VERSION ""

NS_ :

BS_:

BU_: ESP_EV

BO_ 3221225472 VECTOR__INDEPENDENT_SIG_MSG: 0 Vector__XXX
 SG_ NoGearshiftReqStatus : 0|2@0+ (1,0) [0|3] "" Vector__XXX
 SG_ CruiseCntShutESPStatus : 0|2@0+ (1,0) [0|3] "" Vector__XXX
 SG_ CruiseCntShutESP : 0|1@0+ (1,0) [0|1] "" Vector__XXX
 SG_ PowerModeStateStatus : 0|2@0+ (1,0) [0|3] "" Vector__XXX

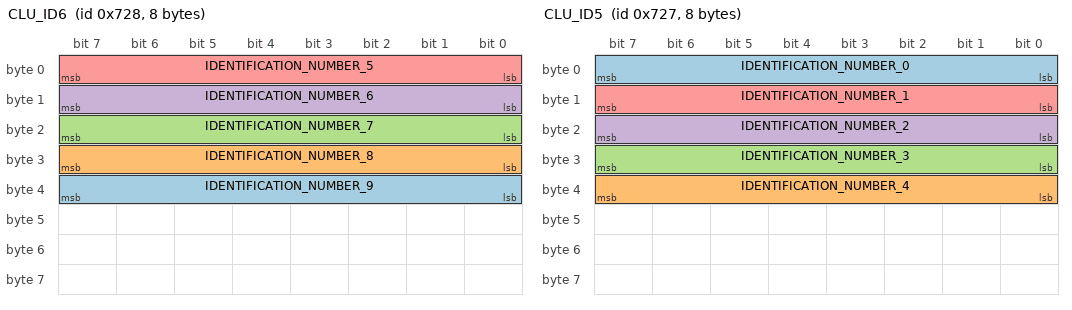
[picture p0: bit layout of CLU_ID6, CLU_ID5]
BO_ 1832 CLU_ID6: 8 Vector__XXX
 SG_ IDENTIFICATION_NUMBER_9 : 32|8@1+ (1,0) [0|255] ""  ESP_EV
 SG_ IDENTIFICATION_NUMBER_8 : 24|8@1+ (1,0) [0|255] ""  ESP_EV
 SG_ IDENTIFICATION_NUMBER_7 : 16|8@1+ (1,0) [0|255] ""  ESP_EV
 SG_ IDENTIFICATION_NUMBER_6 : 8|8@1+ (1,0) [0|255] ""  ESP_EV
 SG_ IDENTIFICATION_NUMBER_5 : 0|8@1+ (1,0) [0|255] ""  ESP_EV

BO_ 1831 CLU_ID5: 8 Vector__XXX
 SG_ IDENTIFICATION_NUMBER_0 : 0|8@1+ (1,0) [0|255] ""  ESP_EV
 SG_ IDENTIFICATION_NUMBER_4 : 32|8@1+ (1,0) [0|255] ""  ESP_EV
 SG_ IDENTIFICATION_NUMBER_3 : 24|8@1+ (1,0) [0|255] ""  ESP_EV
 SG_ IDENTIFICATION_NUMBER_2 : 16|8@1+ (1,0) [0|255] ""  ESP_EV
 SG_ IDENTIFICATION_NUMBER_1 : 8|8@1+ (1,0) [0|255] ""  ESP_EV

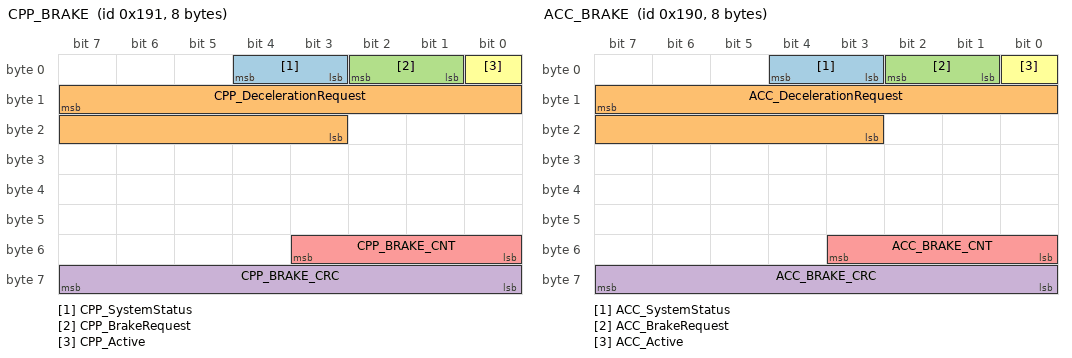
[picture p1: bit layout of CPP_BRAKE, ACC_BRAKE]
BO_ 401 CPP_BRAKE: 8 Vector__XXX
 SG_ CPP_SystemStatus : 4|2@0+ (1,0) [0|3] ""  ESP_EV
 SG_ CPP_DecelerationRequest : 15|13@0+ (0.001,-5) [-5|3.191] "g"  ESP_EV
 SG_ CPP_BrakeRequest : 2|2@0+ (1,0) [0|3] ""  ESP_EV
 SG_ CPP_BRAKE_CRC : 63|8@0+ (1,0) [0|255] ""  ESP_EV
 SG_ CPP_BRAKE_CNT : 51|4@0+ (1,0) [0|15] ""  ESP_EV
 SG_ CPP_Active : 0|1@0+ (1,0) [0|1] ""  ESP_EV

BO_ 400 ACC_BRAKE: 8 Vector__XXX
 SG_ ACC_SystemStatus : 4|2@0+ (1,0) [0|3] ""  ESP_EV
 SG_ ACC_DecelerationRequest : 15|13@0+ (0.001,-5) [-5|3.191] "g"  ESP_EV
 SG_ ACC_BrakeRequest : 2|2@0+ (1,0) [0|3] ""  ESP_EV
 SG_ ACC_BRAKE_CRC : 63|8@0+ (1,0) [0|255] ""  ESP_EV
 SG_ ACC_BRAKE_CNT : 51|4@0+ (1,0) [0|15] ""  ESP_EV
 SG_ ACC_Active : 0|1@0+ (1,0) [0|1] ""  ESP_EV

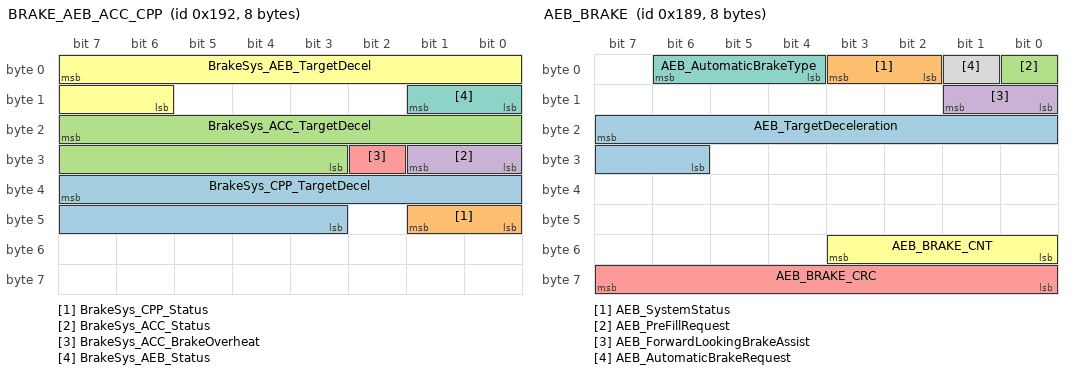
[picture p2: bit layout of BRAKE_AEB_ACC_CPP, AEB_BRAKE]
BO_ 402 BRAKE_AEB_ACC_CPP: 8 ESP_EV
 SG_ BrakeSys_CPP_TargetDecel : 39|13@0+ (0.001,-5) [-5|3.191] "g" Vector__XXX
 SG_ BrakeSys_CPP_Status : 41|2@0+ (1,0) [0|0] "" Vector__XXX
 SG_ BrakeSys_ACC_TargetDecel : 23|13@0+ (0.001,-5) [-5|3.191] "g" Vector__XXX
 SG_ BrakeSys_ACC_Status : 25|2@0+ (1,0) [0|3] "" Vector__XXX
 SG_ BrakeSys_ACC_BrakeOverheat : 26|1@0+ (1,0) [0|1] "" Vector__XXX
 SG_ BrakeSys_AEB_TargetDecel : 7|10@0+ (0.01,-5) [-5|5.23] "g" Vector__XXX
 SG_ BrakeSys_AEB_Status : 9|2@0+ (1,0) [0|3] "" Vector__XXX

BO_ 393 AEB_BRAKE: 8 Vector__XXX
 SG_ AEB_TargetDeceleration : 23|10@0+ (0.01,-5) [-5|5.23] "g"  ESP_EV
 SG_ AEB_SystemStatus : 3|2@0+ (1,0) [0|3] ""  ESP_EV
 SG_ AEB_PreFillRequest : 0|1@0+ (1,0) [0|1] ""  ESP_EV
 SG_ AEB_ForwardLookingBrakeAssist : 9|2@0+ (1,0) [0|2] ""  ESP_EV
 SG_ AEB_BRAKE_CRC : 63|8@0+ (1,0) [0|255] ""  ESP_EV
 SG_ AEB_BRAKE_CNT : 51|4@0+ (1,0) [0|15] ""  ESP_EV
 SG_ AEB_AutomaticBrakeType : 6|3@0+ (1,0) [0|5] ""  ESP_EV
 SG_ AEB_AutomaticBrakeRequest : 1|1@0+ (1,0) [0|1] ""  ESP_EV

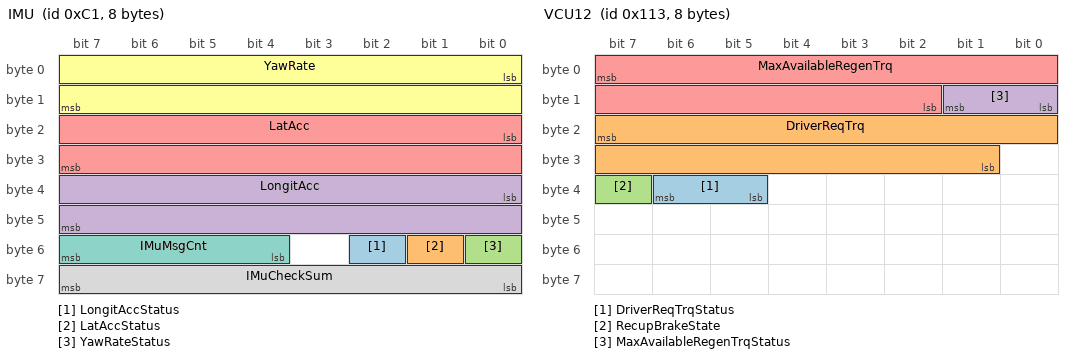
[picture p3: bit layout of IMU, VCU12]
BO_ 193 IMU: 8 Vector__XXX
 SG_ LongitAccStatus : 50|1@1+ (1,0) [0|1] ""  ESP_EV
 SG_ LatAccStatus : 49|1@1+ (1,0) [0|1] ""  ESP_EV
 SG_ YawRateStatus : 48|1@1+ (1,0) [0|1] ""  ESP_EV
 SG_ LongitAcc : 32|16@1+ (0.002,-65.532) [-65.532|65.538] "m/s2"  ESP_EV
 SG_ LatAcc : 16|16@1+ (0.002,-65.532) [-65.532|65.538] "m/s2"  ESP_EV
 SG_ YawRate : 0|16@1+ (0.005,-163.83) [-163.83|163.845] "°/s"  ESP_EV
 SG_ IMuMsgCnt : 52|4@1+ (1,0) [0|15] ""  ESP_EV
 SG_ IMuCheckSum : 56|8@1+ (1,0) [0|255] ""  ESP_EV

BO_ 2015 TesterFunctionalReq: 8 Vector__XXX
 SG_ TesterFunctionalRequestESP : 7|64@0+ (1,0) [0|0] ""  ESP_EV

BO_ 275 VCU12: 8 Vector__XXX
 SG_ DriverReqTrqStatus : 38|2@0+ (1,0) [0|3] ""  ESP_EV
 SG_ DriverReqTrq : 23|15@0+ (0.2,-3276.8) [-3276.8|3276.6] ""  ESP_EV
 SG_ RecupBrakeState : 39|1@0+ (1,0) [0|1] ""  ESP_EV
 SG_ MaxAvailableRegenTrqStatus : 9|2@0+ (1,0) [0|3] ""  ESP_EV
 SG_ MaxAvailableRegenTrq : 7|14@0+ (0.2,0) [0|3276.6] ""  ESP_EV

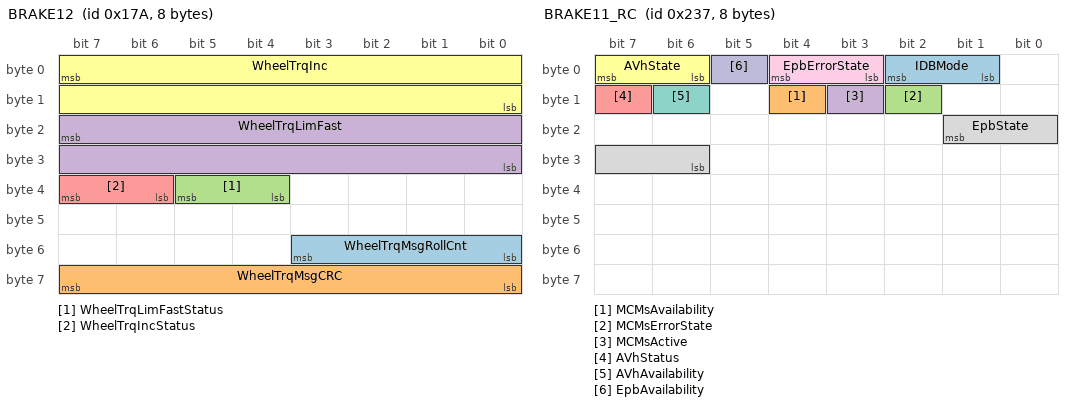
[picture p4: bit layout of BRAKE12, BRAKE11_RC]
BO_ 378 BRAKE12: 8 ESP_EV
 SG_ WheelTrqMsgRollCnt : 51|4@0+ (1,0) [0|15] "" Vector__XXX
 SG_ WheelTrqMsgCRC : 63|8@0+ (1,0) [0|255] "" Vector__XXX
 SG_ WheelTrqLimFastStatus : 37|2@0+ (1,0) [0|3] "" Vector__XXX
 SG_ WheelTrqLimFast : 23|16@0+ (0.1,-3276.8) [-3276.8|3276.7] "Nm" Vector__XXX
 SG_ WheelTrqIncStatus : 39|2@0+ (1,0) [0|3] "" Vector__XXX
 SG_ WheelTrqInc : 7|16@0+ (0.1,-3276.8) [-3276.8|3276.7] "Nm" Vector__XXX

BO_ 567 BRAKE11_RC: 8 ESP_EV
 SG_ IDBMode : 2|2@0+ (1,0) [0|3] "" Vector__XXX
 SG_ MCMsAvailability : 12|1@0+ (1,0) [0|1] "" Vector__XXX
 SG_ MCMsErrorState : 10|1@0+ (1,0) [0|1] "" Vector__XXX
 SG_ MCMsActive : 11|1@0+ (1,0) [0|1] "" Vector__XXX
 SG_ AVhStatus : 15|1@0+ (1,0) [0|1] "" Vector__XXX
 SG_ AVhState : 7|2@0+ (1,0) [0|3] "" Vector__XXX
 SG_ AVhAvailability : 14|1@0+ (1,0) [0|1] "" Vector__XXX
 SG_ EpbState : 17|4@0+ (1,0) [0|15] "" Vector__XXX
 SG_ EpbErrorState : 4|2@0+ (1,0) [0|3] "" Vector__XXX
 SG_ EpbAvailability : 5|1@0+ (1,0) [0|1] "" Vector__XXX

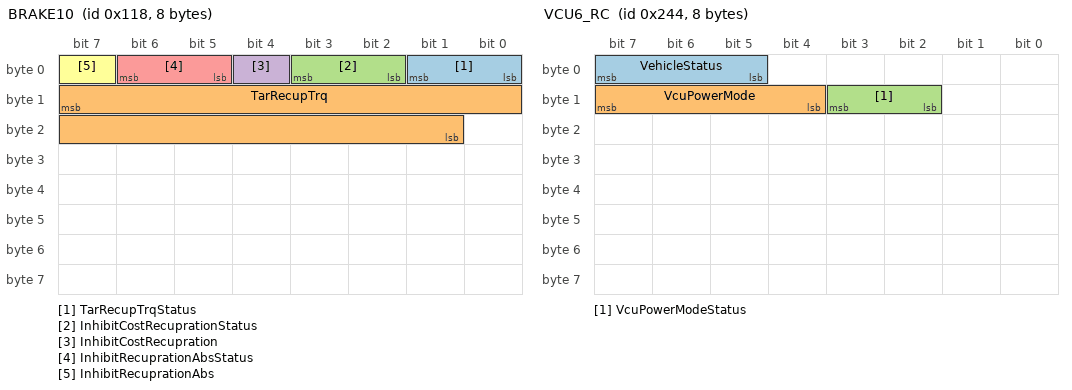
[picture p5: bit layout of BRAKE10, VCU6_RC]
BO_ 280 BRAKE10: 8 ESP_EV
 SG_ TarRecupTrqStatus : 1|2@0+ (1,0) [0|3] "" Vector__XXX
 SG_ TarRecupTrq : 15|15@0+ (0.1,0) [0|3276.7] "" Vector__XXX
 SG_ InhibitCostRecuprationStatus : 3|2@0+ (1,0) [0|3] "" Vector__XXX
 SG_ InhibitCostRecupration : 4|1@0+ (1,0) [0|1] "" Vector__XXX
 SG_ InhibitRecuprationAbsStatus : 6|2@0+ (1,0) [0|3] "" Vector__XXX
 SG_ InhibitRecuprationAbs : 7|1@0+ (1,0) [0|1] "" Vector__XXX

BO_ 1289 NM_ESP_TX: 8 ESP_EV
 SG_ PreviousState_ESP : 19|3@0+ (1,0) [0|7] "" Vector__XXX
 SG_ Reserved63 : 20|1@0+ (1,0) [0|1] "" Vector__XXX
 SG_ Reserved62 : 21|1@0+ (1,0) [0|1] "" Vector__XXX
 SG_ Reserved61 : 22|1@0+ (1,0) [0|1] "" Vector__XXX
 SG_ Reserved60 : 23|1@0+ (1,0) [0|1] "" Vector__XXX
 SG_ Reserved59 : 9|1@0+ (1,0) [0|1] "" Vector__XXX
 SG_ Reserved58 : 10|1@0+ (1,0) [0|1] "" Vector__XXX
 SG_ Reserved57 : 13|1@0+ (1,0) [0|1] "" Vector__XXX
 SG_ Reserved56 : 15|1@0+ (1,0) [0|1] "" Vector__XXX
 SG_ RepeatMessageReq_ESP : 8|1@0+ (1,0) [0|1] "" Vector__XXX
 SG_ PartialNetworkInformation_ESP : 14|1@0+ (1,0) [0|1] "" Vector__XXX
 SG_ NMCoOrdSlpReady_ESP : 11|1@0+ (1,0) [0|1] "" Vector__XXX
 SG_ ESP_NMPDU_USER_DATA_D5 : 63|8@0+ (1,0) [0|255] "" Vector__XXX
 SG_ ESP_NMPDU_USER_DATA_D4 : 55|8@0+ (1,0) [0|255] "" Vector__XXX
 SG_ ESP_NMPDU_USER_DATA_D3 : 47|8@0+ (1,0) [0|255] "" Vector__XXX
 SG_ ESP_NMPDU_USER_DATA_D2 : 39|8@0+ (1,0) [0|255] "" Vector__XXX
 SG_ ESP_NMPDU_USER_DATA_D1 : 31|8@0+ (1,0) [0|255] "" Vector__XXX
 SG_ ESP_NMPDU_SRC_ECU_ID : 7|8@0+ (1,0) [0|255] "" Vector__XXX
 SG_ CurrentState_ESP : 16|1@0+ (1,0) [0|1] "" Vector__XXX
 SG_ ActiveWakeUp_ESP : 12|1@0+ (1,0) [0|1] "" Vector__XXX

BO_ 1163 BRAKE_SF1: 8 Vector__XXX
 SG_ VCUMToFailureStatus : 33|2@0+ (1,0) [0|3] "" Vector__XXX
 SG_ VCUInvalidFailureStatus : 35|2@0+ (1,0) [0|3] "" Vector__XXX

BO_ 580 VCU6_RC: 8 Vector__XXX
 SG_ VehicleStatus : 7|3@0+ (1,0) [0|7] ""  ESP_EV
 SG_ VcuPowerMode : 15|4@0+ (1,0) [0|15] ""  ESP_EV
 SG_ VcuPowerModeStatus : 11|2@0+ (1,0) [0|3] ""  ESP_EV

BO_ 579 VCU5: 8 Vector__XXX
 SG_ GearForDisplayVcu : 7|4@0+ (1,0) [0|15] ""  ESP_EV
 SG_ GearForDisplayVcuStatus : 3|2@0+ (1,0) [0|3] ""  ESP_EV

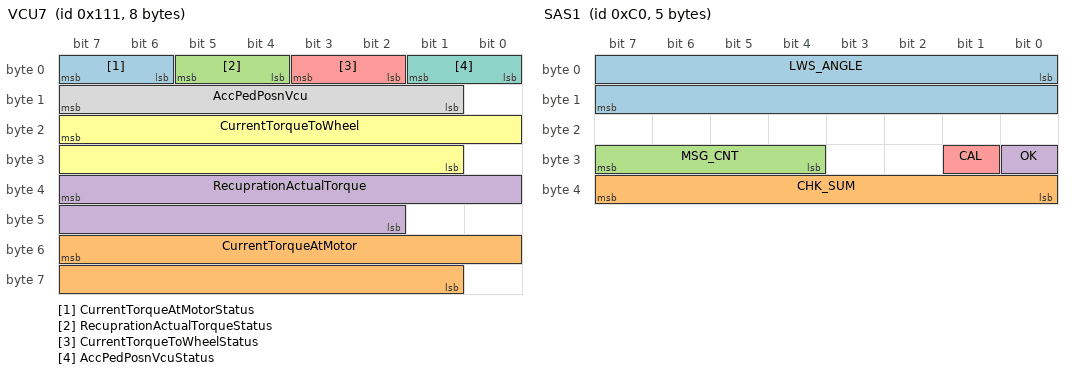
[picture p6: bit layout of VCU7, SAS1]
BO_ 273 VCU7: 8 Vector__XXX
 SG_ CurrentTorqueAtMotorStatus : 7|2@0+ (1,0) [0|3] ""  ESP_EV
 SG_ CurrentTorqueAtMotor : 55|15@0+ (0.2,-3276.8) [-3276.8|3276.6] ""  ESP_EV
 SG_ RecuprationActualTorqueStatus : 5|2@0+ (1,0) [0|3] ""  ESP_EV
 SG_ RecuprationActualTorque : 39|14@0+ (0.2,0) [0|3276.6] ""  ESP_EV
 SG_ CurrentTorqueToWheelStatus : 3|2@0+ (1,0) [0|3] ""  ESP_EV
 SG_ CurrentTorqueToWheel : 23|15@0+ (0.2,-3276.8) [-3276.8|3276.6] ""  ESP_EV
 SG_ AccPedPosnVcuStatus : 1|2@0+ (1,0) [0|3] ""  ESP_EV
 SG_ AccPedPosnVcu : 15|7@0+ (1,0) [0|100] "%"  ESP_EV

BO_ 192 SAS1: 5 Vector__XXX
 SG_ LWS_ANGLE : 0|16@1- (0.1,0) [-780|779.9] "degree"  ESP_EV
 SG_ CHK_SUM : 32|8@1+ (1,0) [0|255] ""  ESP_EV
 SG_ MSG_CNT : 28|4@1+ (1,0) [0|15] ""  ESP_EV
 SG_ OK : 24|1@1+ (1,0) [0|1] ""  ESP_EV
 SG_ CAL : 25|1@1+ (1,0) [0|1] ""  ESP_EV

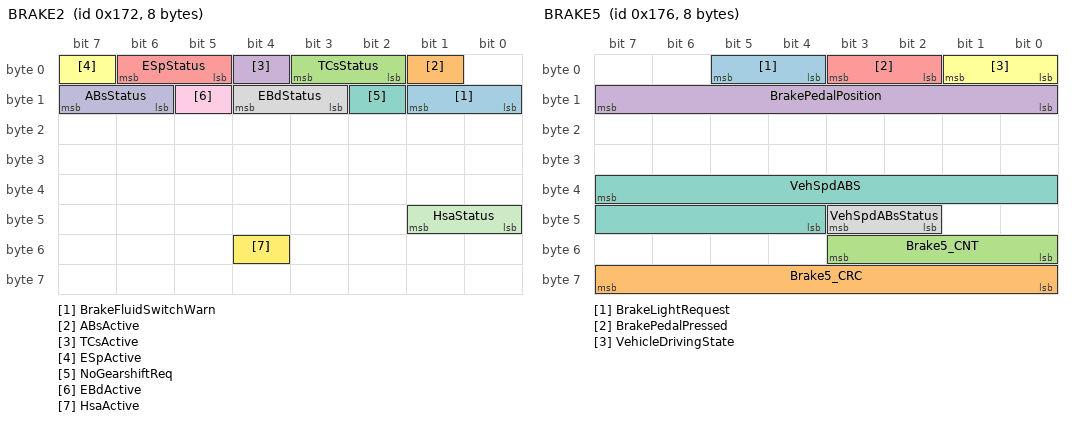
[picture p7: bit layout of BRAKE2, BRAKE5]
BO_ 370 BRAKE2: 8 ESP_EV
 SG_ BrakeFluidSwitchWarn : 9|2@0+ (1,0) [0|0] "" Vector__XXX
 SG_ ABsActive : 1|1@0+ (1,0) [0|1] "" Vector__XXX
 SG_ TCsStatus : 3|2@0+ (1,0) [0|3] "" Vector__XXX
 SG_ TCsActive : 4|1@0+ (1,0) [0|1] "" Vector__XXX
 SG_ ESpStatus : 6|2@0+ (1,0) [0|3] "" Vector__XXX
 SG_ ESpActive : 7|1@0+ (1,0) [0|1] "" Vector__XXX
 SG_ NoGearshiftReq : 10|1@0+ (1,0) [0|1] "" Vector__XXX
 SG_ EBdStatus : 12|2@0+ (1,0) [0|3] "" Vector__XXX
 SG_ EBdActive : 13|1@0+ (1,0) [0|1] "" Vector__XXX
 SG_ ABsStatus : 15|2@0+ (1,0) [0|3] "" Vector__XXX
 SG_ HsaStatus : 41|2@0+ (1,0) [0|3] "" Vector__XXX
 SG_ HsaActive : 52|1@0+ (1,0) [0|1] "" Vector__XXX

BO_ 374 BRAKE5: 8 ESP_EV
 SG_ BrakeLightRequest : 5|2@0+ (1,0) [0|3] "" Vector__XXX
 SG_ Brake5_CRC : 63|8@0+ (1,0) [0|255] "" Vector__XXX
 SG_ Brake5_CNT : 51|4@0+ (1,0) [0|15] "" Vector__XXX
 SG_ BrakePedalPosition : 15|8@0+ (0.4,0) [0|100] "%" Vector__XXX
 SG_ BrakePedalPressed : 3|2@0+ (1,0) [0|3] "" Vector__XXX
 SG_ VehicleDrivingState : 1|2@0+ (1,0) [0|3] "" Vector__XXX
 SG_ VehSpdABS : 39|12@0+ (0.03125,0) [0|127.96875] "m/s" Vector__XXX
 SG_ VehSpdABsStatus : 43|2@0+ (1,0) [0|3] "" Vector__XXX

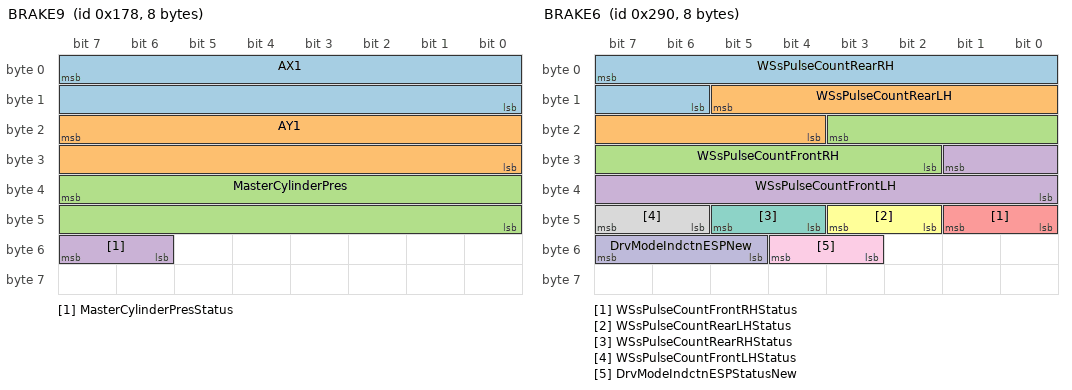
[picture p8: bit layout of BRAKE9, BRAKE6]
BO_ 376 BRAKE9: 8 ESP_EV
 SG_ AX1 : 7|16@0+ (0.0001,-3.2768) [-3.2768|3.2767] "g" Vector__XXX
 SG_ AY1 : 23|16@0+ (0.0001,-3.2768) [-3.2768|3.2767] "g" Vector__XXX
 SG_ MasterCylinderPres : 39|16@0+ (0.05,-40) [-40|400] "bar" Vector__XXX
 SG_ MasterCylinderPresStatus : 55|2@0+ (1,0) [0|3] "" Vector__XXX

BO_ 656 BRAKE6: 8 ESP_EV
 SG_ WSsPulseCountRearRH : 7|10@0+ (1,0) [0|1023] "Pulse" Vector__XXX
 SG_ WSsPulseCountRearLH : 13|10@0+ (1,0) [0|1023] "Pulse" Vector__XXX
 SG_ WSsPulseCountFrontRH : 19|10@0+ (1,0) [0|1023] "Pulse" Vector__XXX
 SG_ WSsPulseCountFrontLH : 25|10@0+ (1,0) [0|1023] "Pulse" Vector__XXX
 SG_ WSsPulseCountFrontRHStatus : 41|2@0+ (1,0) [0|3] "" Vector__XXX
 SG_ WSsPulseCountRearLHStatus : 43|2@0+ (1,0) [0|3] "" Vector__XXX
 SG_ WSsPulseCountRearRHStatus : 45|2@0+ (1,0) [0|3] "" Vector__XXX
 SG_ WSsPulseCountFrontLHStatus : 47|2@0+ (1,0) [0|3] "" Vector__XXX
 SG_ DrvModeIndctnESPStatusNew : 52|2@0+ (1,0) [0|3] "" Vector__XXX
 SG_ DrvModeIndctnESPNew : 55|3@0+ (1,0) [0|7] "" Vector__XXX

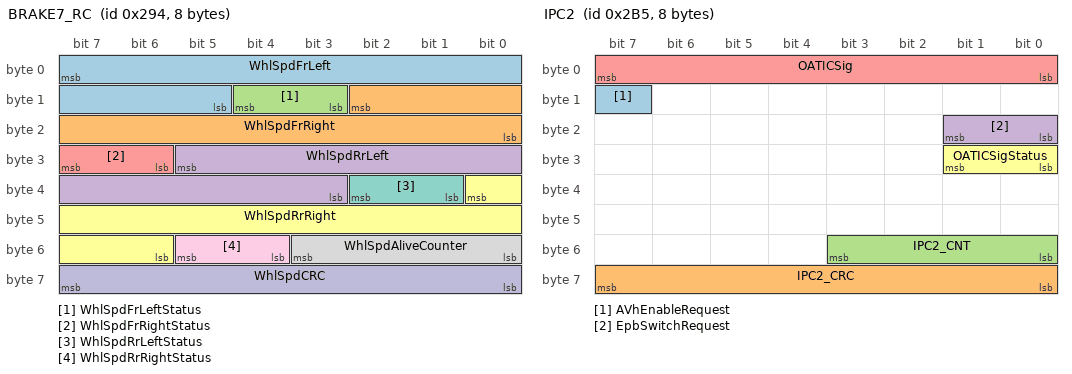
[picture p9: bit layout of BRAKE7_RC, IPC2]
BO_ 660 BRAKE7_RC: 8 ESP_EV
 SG_ WhlSpdFrLeft : 7|11@0+ (2,0) [0|4094] "rpm" Vector__XXX
 SG_ WhlSpdFrRight : 10|11@0+ (2,0) [0|4094] "rpm" Vector__XXX
 SG_ WhlSpdFrLeftStatus : 12|2@0+ (1,0) [0|3] "" Vector__XXX
 SG_ WhlSpdRrLeft : 29|11@0+ (2,0) [0|4094] "rpm" Vector__XXX
 SG_ WhlSpdFrRightStatus : 31|2@0+ (1,0) [0|3] "" Vector__XXX
 SG_ WhlSpdRrRight : 32|11@0+ (2,0) [0|4094] "rpm" Vector__XXX
 SG_ WhlSpdRrLeftStatus : 34|2@0+ (1,0) [0|3] "" Vector__XXX
 SG_ WhlSpdAliveCounter : 51|4@0+ (1,0) [0|15] "" Vector__XXX
 SG_ WhlSpdRrRightStatus : 53|2@0+ (1,0) [0|3] "" Vector__XXX
 SG_ WhlSpdCRC : 63|8@0+ (1,0) [0|255] "" Vector__XXX

BO_ 693 IPC2: 8 Vector__XXX
 SG_ AVhEnableRequest : 15|1@0+ (1,0) [0|1] ""  ESP_EV
 SG_ IPC2_CRC : 63|8@0+ (1,0) [0|255] ""  ESP_EV
 SG_ IPC2_CNT : 51|4@0+ (1,0) [0|15] ""  ESP_EV
 SG_ EpbSwitchRequest : 17|2@0+ (1,0) [0|3] ""  ESP_EV
 SG_ OATICSig : 7|8@0+ (0.5,-40) [-40|85] "degC"  ESP_EV
 SG_ OATICSigStatus : 25|2@0+ (1,0) [0|3] ""  ESP_EV

BO_ 722 BCM_HUICTrailer_RC1: 8 Vector__XXX
 SG_ PowerModeState : 5|4@0+ (1,0) [0|15] ""  ESP_EV

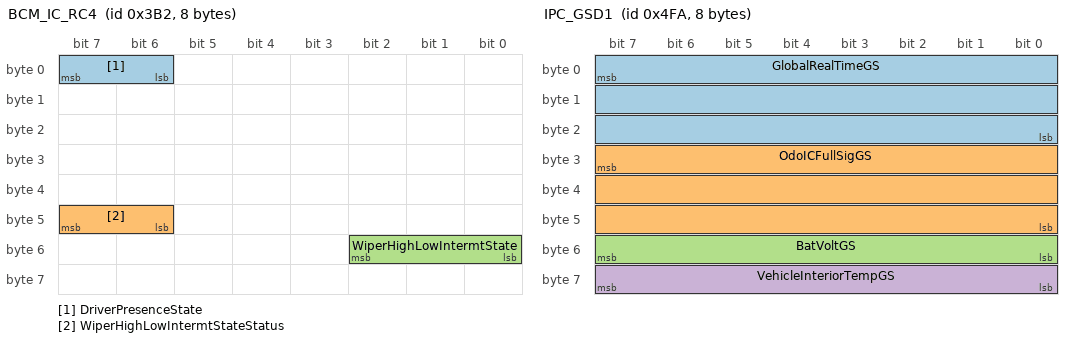
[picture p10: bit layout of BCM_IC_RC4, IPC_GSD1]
BO_ 946 BCM_IC_RC4: 8 Vector__XXX
 SG_ DriverPresenceState : 7|2@0+ (1,0) [0|3] ""  ESP_EV
 SG_ WiperHighLowIntermtStateStatus : 47|2@0+ (1,0) [0|3] ""  ESP_EV
 SG_ WiperHighLowIntermtState : 50|3@0+ (1,0) [0|7] ""  ESP_EV

BO_ 1274 IPC_GSD1: 8 Vector__XXX
 SG_ GlobalRealTimeGS : 7|24@0+ (1,0) [0|16777214] "min"  ESP_EV
 SG_ OdoICFullSigGS : 31|24@0+ (1,0) [0|16777214] "km"  ESP_EV
 SG_ BatVoltGS : 55|8@0+ (0.1,0) [0|25.4] "V"  ESP_EV
 SG_ VehicleInteriorTempGS : 63|8@0+ (1,-40) [-40|214] "Deg"  ESP_EV

BO_ 1280 NM_ESP_RX: 8 Vector__XXX
 SG_ BCM_NMPDU_SRC_ECU_ID : 7|8@0+ (1,0) [0|255] ""  ESP_EV
 SG_ RepeatMessageReq_BCM : 8|1@0+ (1,0) [0|1] ""  ESP_EV
 SG_ Reserved0 : 9|1@0+ (1,0) [0|1] ""  ESP_EV
 SG_ Reserved1 : 10|1@0+ (1,0) [0|1] ""  ESP_EV
 SG_ NMCoOrdSlpReady_BCM : 11|1@0+ (1,0) [0|1] ""  ESP_EV
 SG_ ActiveWakeUp_BCM : 12|1@0+ (1,0) [0|1] ""  ESP_EV
 SG_ Reserved2 : 13|1@0+ (1,0) [0|1] ""  ESP_EV
 SG_ PartialNetworkInformation_BCM : 14|1@0+ (1,0) [0|1] ""  ESP_EV
 SG_ Reserved3 : 15|1@0+ (1,0) [0|1] ""  ESP_EV
 SG_ CurrentState_BCM : 16|1@0+ (1,0) [0|1] ""  ESP_EV
 SG_ PreviousState_BCM : 19|3@0+ (1,0) [0|7] ""  ESP_EV
 SG_ Reserved4 : 20|1@0+ (1,0) [0|1] ""  ESP_EV
 SG_ Reserved5 : 21|1@0+ (1,0) [0|1] ""  ESP_EV
 SG_ Reserved6 : 22|1@0+ (1,0) [0|1] ""  ESP_EV
 SG_ Reserved7 : 23|1@0+ (1,0) [0|1] ""  ESP_EV
 SG_ BCM_NMPDU_USER_DATA_D1 : 31|8@0+ (1,0) [0|255] ""  ESP_EV
 SG_ BCM_NMPDU_USER_DATA_D2 : 39|8@0+ (1,0) [0|255] ""  ESP_EV
 SG_ BCM_NMPDU_USER_DATA_D3 : 47|8@0+ (1,0) [0|255] ""  ESP_EV
 SG_ BCM_NMPDU_USER_DATA_D4 : 55|8@0+ (1,0) [0|255] ""  ESP_EV
 SG_ BCM_NMPDU_USER_DATA_D5 : 63|8@0+ (1,0) [0|255] ""  ESP_EV

BO_ 1872 TesterPhysicalReq: 8 Vector__XXX
 SG_ TesterPhysicalRequestESP : 7|64@0+ (1,0) [0|0] ""  ESP_EV

BO_ 1880 TesterPhysicalResp: 8 ESP_EV
 SG_ TesterPhysicalResponseESP : 7|64@0+ (1,0) [0|0] "" Vector__XXX

CM_ "Arrival_P4: P_CAN; Epsilon_v2.00";
CM_ BU_ ESP_EV "ABS ECU EV ";
CM_ BO_ 3221225472 "This is a message for not used signals, created by Vector CANdb++ DBC OLE DB Provider.";
CM_ SG_ 3221225472 NoGearshiftReqStatus "status information of NoGearshiftReq
";
CM_ SG_ 3221225472 CruiseCntShutESPStatus "ESP requested to EMS ECU for shut sown the cruise control function
";
CM_ SG_ 3221225472 CruiseCntShutESP "ESP requested to EMS ECU for shut sown the cruise control function
";
CM_ SG_ 3221225472 PowerModeStateStatus "This signal is used to verify the correctness of Power Mode Status";
CM_ BO_ 1832 "IMU identification information";
CM_ BO_ 1831 "IMU identification information";
CM_ BO_ 401 "CPP brake request message";
CM_ SG_ 401 CPP_SystemStatus "CPP system status of CPP module";
CM_ SG_ 401 CPP_DecelerationRequest "CPP requested deceleration";
CM_ SG_ 401 CPP_BrakeRequest "CPP braking reqeust";
CM_ SG_ 401 CPP_BRAKE_CRC "E2E checksum";
CM_ SG_ 401 CPP_BRAKE_CNT "E2E Counter";
CM_ SG_ 401 CPP_Active "CPP active state";
CM_ SG_ 400 ACC_SystemStatus "ACC system status of ACC module";
CM_ SG_ 400 ACC_DecelerationRequest "ACC requested deceleration";
CM_ SG_ 400 ACC_BrakeRequest "ACC braking reqeust";
CM_ SG_ 400 ACC_BRAKE_CRC "E2E checksum";
CM_ SG_ 400 ACC_BRAKE_CNT "E2E Counter";
CM_ SG_ 400 ACC_Active "ACC active state";
CM_ SG_ 402 BrakeSys_CPP_TargetDecel "CPP applied target decel";
CM_ SG_ 402 BrakeSys_CPP_Status "CPP braking status";
CM_ SG_ 402 BrakeSys_ACC_TargetDecel "Brake System Automatic Braking Target Decel. Rate";
CM_ SG_ 402 BrakeSys_ACC_Status "ACC Brake System Automatic Braking Status";
CM_ SG_ 402 BrakeSys_ACC_BrakeOverheat "Brake System notification overheated brakes";
CM_ SG_ 402 BrakeSys_AEB_TargetDecel "Brake System Automatic Braking Target Decel. Rate";
CM_ SG_ 402 BrakeSys_AEB_Status "Brake System Automatic Braking Status";
CM_ SG_ 393 AEB_TargetDeceleration "AEB traget deceleration";
CM_ SG_ 393 AEB_SystemStatus "AEB system status of AEB module";
CM_ SG_ 393 AEB_PreFillRequest "Brake Prefill Request";
CM_ SG_ 393 AEB_ForwardLookingBrakeAssist "Forward-looking Brake Assist ";
CM_ SG_ 393 AEB_BRAKE_CRC "E2E Checksum";
CM_ SG_ 393 AEB_BRAKE_CNT "E2E counter";
CM_ SG_ 393 AEB_AutomaticBrakeType "Collision Preparation System Automatic Braking Type";
CM_ SG_ 393 AEB_AutomaticBrakeRequest "AEB braking reqeust";
CM_ BO_ 193 "Vehicle accelerations data received from IMU.";
CM_ SG_ 193 LongitAccStatus "The signal indicates data validity status of the vehicle's longit. acceleration.
";
CM_ SG_ 193 LatAccStatus "The signal indicates data validity status of the vehicle's lateral acceleration.
";
CM_ SG_ 193 YawRateStatus "The signal indicates data validity status of the vehicle's yaw rate.
";
CM_ SG_ 193 LongitAcc "Vehicle's longit. acceleration.";
CM_ SG_ 193 LatAcc "Vehicle's lateral acceleration.";
CM_ SG_ 193 YawRate "Vehicle's yaw rate.";
CM_ SG_ 193 IMuMsgCnt "Message Counter for IMU message.
";
CM_ SG_ 193 IMuCheckSum "Check sum for IMU message.
";
CM_ SG_ 275 DriverReqTrqStatus "Driver requested torque status";
CM_ SG_ 275 DriverReqTrq "Driver requested torque";
CM_ SG_ 275 RecupBrakeState "Recupration brake Enable Flag";
CM_ SG_ 275 MaxAvailableRegenTrqStatus "Status information of MaxAvailableRegenTrq Signal";
CM_ SG_ 275 MaxAvailableRegenTrq "Actual available regen torque at VCU";
CM_ SG_ 378 WheelTrqMsgRollCnt "Rolling counter for the message which consists of MotorTrqInc, MototrTrqLimFast";
CM_ SG_ 378 WheelTrqMsgCRC "CRC for entire message which consists of MotorTrqInc, MototrTrqLimFast";
CM_ SG_ 378 WheelTrqLimFastStatus "status information of EngTrqLimFast
";
CM_ SG_ 378 WheelTrqLimFast "target engine torque limit (fast) in NM.
Signal will be used by VCU ECU for ESP/TCS function from ESP
";
CM_ SG_ 378 WheelTrqIncStatus "Status signal information of MotorTrqInc
";
CM_ SG_ 378 WheelTrqInc "Target Motor torque increases in Nm.
Signal will be used by VCU ECU for ESP/TCS function from  ESP
";
CM_ SG_ 567 IDBMode "To inform other Controllers that the EPB Rollerbench Mode or Dyno Mode is active";
CM_ SG_ 567 MCMsAvailability "MCMs Function availability indication";
CM_ SG_ 567 MCMsErrorState "Status information of MCMS";
CM_ SG_ 567 MCMsActive "Indication that ESP system currently performs MCMS Intervention or not";
CM_ SG_ 567 AVhStatus "status of AVH function";
CM_ SG_ 567 AVhState "state of AVH function";
CM_ SG_ 567 AVhAvailability "AVH function availability indication";
CM_ SG_ 567 EpbState "status of EPB system";
CM_ SG_ 567 EpbErrorState "error indication of EPB system";
CM_ SG_ 567 EpbAvailability "EPB function availability information";
CM_ SG_ 280 TarRecupTrqStatus "Status signal of TarRegenTrq Signal";
CM_ SG_ 280 TarRecupTrq "Target Regen torque Value for VCU";
CM_ SG_ 280 InhibitCostRecuprationStatus "Costing Recupration Request Status";
CM_ SG_ 280 InhibitCostRecupration "costing Recupration Request";
CM_ SG_ 280 InhibitRecuprationAbsStatus "Recupration Request Status";
CM_ SG_ 280 InhibitRecuprationAbs "Recupration Request";
CM_ BO_ 1163 "Supervsion frame transmitted by ABS EV ECU";
CM_ SG_ 1163 VCUMToFailureStatus "VCUMTO failure status";
CM_ SG_ 1163 VCUInvalidFailureStatus "VCU invalid failure status";
CM_ SG_ 580 VehicleStatus "Vehicle status display messages";
CM_ SG_ 580 VcuPowerMode "Indicates the VCU power mode";
CM_ SG_ 580 VcuPowerModeStatus "This information is used to determine the plausibility status for VCU power mode message";
CM_ SG_ 579 GearForDisplayVcu "Gear For Display";
CM_ SG_ 579 GearForDisplayVcuStatus "Gear For Display Status";
CM_ SG_ 273 CurrentTorqueAtMotorStatus "Status signal of Current Torque At Motor";
CM_ SG_ 273 CurrentTorqueAtMotor "Current Torque At Motor values";
CM_ SG_ 273 RecuprationActualTorqueStatus "Recupration Request Status";
CM_ SG_ 273 RecuprationActualTorque "Recupration Torque values";
CM_ SG_ 273 CurrentTorqueToWheelStatus "Status signal of Current Torque To Wheel signal";
CM_ SG_ 273 CurrentTorqueToWheel "Current Torque To Wheel values";
CM_ SG_ 273 AccPedPosnVcuStatus "This information is used to determine the accelerator pedal position signal status";
CM_ SG_ 273 AccPedPosnVcu "This information is used to determine the accelerator pedal position";
CM_ SG_ 192 LWS_ANGLE "Current steering wheel angle
";
CM_ SG_ 192 CHK_SUM "Check sum for SAS Messages
";
CM_ SG_ 192 MSG_CNT "Message Counter for SAS Message
";
CM_ SG_ 192 OK "The signal indicates the failure status of the steering angle sensor
";
CM_ SG_ 192 CAL "Calibration status of the steering angle sensor
";
CM_ SG_ 370 BrakeFluidSwitchWarn "BFLS_Warning_Active is set if DTC is active: 
BFLSwitch_Invalid
0x5051 7B";
CM_ SG_ 370 ABsActive "Indication that ABS / ESP system currently performs ABS intervention";
CM_ SG_ 370 TCsStatus "status information of TCs";
CM_ SG_ 370 TCsActive "Indication that ESP system currently performs TCS intervention";
CM_ SG_ 370 ESpStatus "status information of Esp
";
CM_ SG_ 370 ESpActive "Indication that ESP system currently performs an ESP intervention
";
CM_ SG_ 370 NoGearshiftReq "Indication that ESP system inhibits automatic gear shift
";
CM_ SG_ 370 EBdStatus "status information of EBD
";
CM_ SG_ 370 EBdActive "Indication that ABS / ESP system currently performs EBD intervention
";
CM_ SG_ 370 ABsStatus "status information of ABs";
CM_ SG_ 370 HsaStatus "status information of HSA";
CM_ SG_ 370 HsaActive "Indication that ESP system currently performs HSA intervention.";
CM_ SG_ 374 BrakeLightRequest "Brake lights state that is required to be applied";
CM_ SG_ 374 Brake5_CRC "CRC for the message 0x176";
CM_ SG_ 374 Brake5_CNT "rolling counter for message 0x176";
CM_ SG_ 374 BrakePedalPosition "Brake Pedal position in percent
0x0 ~ 0xFA :   Valid, 0% ~ 100%
0xFB ~ 0xFE : Reserved
0xFF: Faulty";
CM_ SG_ 374 BrakePedalPressed "Indicates if the driver is applying the brake pedal (threshold tbd)";
CM_ SG_ 374 VehicleDrivingState "Inidicates if the vehicle is stationary (threshold tbd) or moving";
CM_ SG_ 374 VehSpdABS "vehicle speed signal calculated by ABS and ESP ECU and will be given to IC

";
CM_ SG_ 374 VehSpdABsStatus "status information of VehSpdABs";
CM_ SG_ 376 AX1 "Longitudinal accelaration information";
CM_ SG_ 376 AY1 "Lateral accelaration information";
CM_ SG_ 376 MasterCylinderPres "Master cylinder pressure";
CM_ SG_ 376 MasterCylinderPresStatus "Master cylinder pressure signal status";
CM_ SG_ 656 WSsPulseCountRearRH "ESP transmits it to HU for navigation purposes.";
CM_ SG_ 656 WSsPulseCountRearLH "ESP transmits it to HU for navigation purposes.";
CM_ SG_ 656 WSsPulseCountFrontRH "ESP transmits it to HU for navigation purposes.";
CM_ SG_ 656 WSsPulseCountFrontLH "ESP transmits it to HU for navigation purposes.";
CM_ SG_ 656 WSsPulseCountFrontRHStatus "ESP transmits it to HU for navigation purposes";
CM_ SG_ 656 WSsPulseCountRearLHStatus "ESP transmits it to HU for navigation purposes";
CM_ SG_ 656 WSsPulseCountRearRHStatus "ESP transmits it to HU for navigation purposes";
CM_ SG_ 656 WSsPulseCountFrontLHStatus "ESP transmits it to HU for navigation purposes";
CM_ SG_ 656 DrvModeIndctnESPStatusNew "Status of the Drive mode indication ESP signal. It is 'Package Protected' signal.";
CM_ SG_ 656 DrvModeIndctnESPNew "Information to ESP to IPC and rotary switch indicating that it has switched to correcpoding mode. It is 'Package Protected' signal.";
CM_ SG_ 660 WhlSpdFrLeft "Angular wheel speed signal transmitted by ABS and ESP ECU and will be given to PEPS & ESCL";
CM_ SG_ 660 WhlSpdFrRight "Angular wheel speed signal transmitted by ABS and ESP ECU and will be given to PEPS & ESCL";
CM_ SG_ 660 WhlSpdFrLeftStatus "status information of WhlSpdFL";
CM_ SG_ 660 WhlSpdRrLeft "Angular wheel speed signal transmitted by ABS and ESP ECU and will be given to PEPS & ESCL";
CM_ SG_ 660 WhlSpdFrRightStatus "status information of WhlSpdFR 
";
CM_ SG_ 660 WhlSpdRrRight "Angular wheel speed signal transmitted by ABS and ESP ECU and will be given to EPAS & other
";
CM_ SG_ 660 WhlSpdRrLeftStatus "status information of WhlSpdRR
";
CM_ SG_ 660 WhlSpdAliveCounter "rolling counter for message 0x294";
CM_ SG_ 660 WhlSpdRrRightStatus "status information of WhlSpdRL
";
CM_ SG_ 660 WhlSpdCRC "CRC for the message 0x294";
CM_ SG_ 693 AVhEnableRequest "Autohold (AVH) function enabler.
IF AVhEnableRequest is 0x0 THEN Autohold function shall be disabled on the vehicle.
IF AVhEnableRequest is 0x1 THEN Autohold function shall be enabled on the vehicle.";
CM_ SG_ 693 EpbSwitchRequest "EPB soft switch request to apply/release EPB, including dynamic apply";
CM_ SG_ 693 OATICSig "Signal represents Outside Ambient Temperature raw value evaluated by Instrument Cluster ";
CM_ SG_ 693 OATICSigStatus "Signal represents Status of OATSig";
CM_ SG_ 722 PowerModeState "Vehicle power mode signal shall be used by all ECUs of the vehicle for their respective functional implementation";
CM_ SG_ 946 DriverPresenceState "Driver Presence State";
CM_ SG_ 946 WiperHighLowIntermtStateStatus "Status of the Wiper Wiper High, Low, Intermittent state whether Valid or not";
CM_ SG_ 946 WiperHighLowIntermtState "Status of the Wiper High, Low, Intermittent state to various ECUs";
CM_ SG_ 1274 GlobalRealTimeGS "Global Real Time
";
CM_ SG_ 1274 OdoICFullSigGS "Total Distance Travelled";
CM_ SG_ 1274 BatVoltGS "Supply Voltage of Instrument Cluster";
CM_ SG_ 1274 VehicleInteriorTempGS "Vehicle Interior Temperature
";
BA_DEF_  "BusType" STRING ;
BA_DEF_  "DBName" STRING ;
BA_DEF_ SG_  "Remarks" STRING ;
BA_DEF_ SG_  "GenSigTimeoutTime_HU_Mid_X451" INT 0 65535;
BA_DEF_ SG_  "GenSigTimeoutTime_HU_High_X451" INT 0 65535;
BA_DEF_ SG_  "GenSigTimeoutTime_HU_B" INT 0 65535;
BA_DEF_ SG_  "GenSigTimeoutTime_HU_A" INT 0 65535;
BA_DEF_ SG_  "GenSigTimeoutTime_BCM_Mid" INT 0 65535;
BA_DEF_ SG_  "GenSigTimeoutMsg_HU_Mid_X451" INT 0 65535;
BA_DEF_ SG_  "GenSigTimeoutMsg_HU_High_X451" INT 0 65535;
BA_DEF_ SG_  "GenSigTimeoutMsg_HU_B" INT 0 65535;
BA_DEF_ SG_  "GenSigTimeoutMsg_HU_A" INT 0 65535;
BA_DEF_ SG_  "GenSigStartValue" INT 0 0;
BA_DEF_ SG_  "GenSigSendType" ENUM  "Cyclic","OnWrite","OnWriteWithRepetition","OnChange","OnChangeWithRepetition","IfActive","IfActiveWithRepetition","NoSigSendType","NotUsed","NotUsed","NotUsed","NotUsed","NotUsed";
BA_DEF_ SG_  "GenSigInactiveValue" INT 0 0;
BA_DEF_ SG_  "GenSigEnvVarType" ENUM  "int","float","undef";
BA_DEF_ SG_  "GenSigCycleTimeActive" INT 0 0;
BA_DEF_ SG_  "GenSigCycleTime" INT 0 0;
BA_DEF_ SG_  "GenSigTimeoutMsg_HU_High_X445" INT 0 65535;
BA_DEF_ SG_  "GenSigTimeoutMsg_HU_Mid_X445" INT 0 65535;
BA_DEF_ SG_  "GenSigTimeoutTime_HU_High_X445" INT 0 65535;
BA_DEF_ SG_  "GenSigTimeoutTime_HU_Mid_X445" INT 0 65535;
BA_DEF_ BO_  "NmAsrMessage" ENUM  "<n.a.>","No","Yes";
BA_DEF_ BO_  "MessageTimeout" INT 0 65535;
BA_DEF_ BO_  "GenMsgStartDelayTime" INT 0 0;
BA_DEF_ BO_  "GenMsgSendType" ENUM  "Cyclic","NotUsed","NotUsed","NotUsed","NotUsed","NotUsed","OnChange","IfActive","NoMsgSendType","NotUsed";
BA_DEF_ BO_  "GenMsgILSupport" ENUM  "No","Yes";
BA_DEF_ BO_  "GenMsgCycleTime" INT 0 0;
BA_DEF_ BO_  "DiagUudtResponse" ENUM  "false","true";
BA_DEF_ BO_  "DiagUsdtResponse" ENUM  "false","true";
BA_DEF_ BO_  "DiagResponse" ENUM  "No","Yes";
BA_DEF_ BO_  "DiagRequest" ENUM  "No","Yes";
BA_DEF_ BU_  "NodeLayerModules" STRING ;
BA_DEF_ BU_  "NmStationAddress" INT 0 63;
BA_DEF_ BU_  "NmCAN" INT 1 3;
BA_DEF_ BU_  "NmAsrNodeIdentifier" HEX 0 255;
BA_DEF_ BU_  "NmAsrNode" ENUM  "<n.a.>","No","Yes";
BA_DEF_ BU_  "NmAsrCanMsgReducedTime" INT 1 65535;
BA_DEF_ BU_  "ECU" STRING ;
BA_DEF_DEF_  "BusType" "";
BA_DEF_DEF_  "DBName" "";
BA_DEF_DEF_  "Remarks" "null";
BA_DEF_DEF_  "GenSigTimeoutTime_HU_Mid_X451" 500;
BA_DEF_DEF_  "GenSigTimeoutTime_HU_High_X451" 500;
BA_DEF_DEF_  "GenSigTimeoutTime_HU_B" 500;
BA_DEF_DEF_  "GenSigTimeoutTime_HU_A" 500;
BA_DEF_DEF_  "GenSigTimeoutTime_BCM_Mid" 0;
BA_DEF_DEF_  "GenSigTimeoutMsg_HU_Mid_X451" 500;
BA_DEF_DEF_  "GenSigTimeoutMsg_HU_High_X451" 500;
BA_DEF_DEF_  "GenSigTimeoutMsg_HU_B" 500;
BA_DEF_DEF_  "GenSigTimeoutMsg_HU_A" 500;
BA_DEF_DEF_  "GenSigStartValue" 0;
BA_DEF_DEF_  "GenSigSendType" "Cyclic";
BA_DEF_DEF_  "GenSigInactiveValue" 0;
BA_DEF_DEF_  "GenSigEnvVarType" "undef";
BA_DEF_DEF_  "GenSigCycleTimeActive" 0;
BA_DEF_DEF_  "GenSigCycleTime" 0;
BA_DEF_DEF_  "GenSigTimeoutMsg_HU_High_X445" 500;
BA_DEF_DEF_  "GenSigTimeoutMsg_HU_Mid_X445" 500;
BA_DEF_DEF_  "GenSigTimeoutTime_HU_High_X445" 500;
BA_DEF_DEF_  "GenSigTimeoutTime_HU_Mid_X445" 500;
BA_DEF_DEF_  "NmAsrMessage" "<n.a.>";
BA_DEF_DEF_  "MessageTimeout" 500;
BA_DEF_DEF_  "GenMsgStartDelayTime" 0;
BA_DEF_DEF_  "GenMsgSendType" "Cyclic";
BA_DEF_DEF_  "GenMsgILSupport" "Yes";
BA_DEF_DEF_  "GenMsgCycleTime" 0;
BA_DEF_DEF_  "DiagUudtResponse" "false";
BA_DEF_DEF_  "DiagUsdtResponse" "false";
BA_DEF_DEF_  "DiagResponse" "No";
BA_DEF_DEF_  "DiagRequest" "No";
BA_DEF_DEF_  "NodeLayerModules" "null";
BA_DEF_DEF_  "NmStationAddress" 0;
BA_DEF_DEF_  "NmCAN" 3;
BA_DEF_DEF_  "NmAsrNodeIdentifier" 2;
BA_DEF_DEF_  "NmAsrNode" "<n.a.>";
BA_DEF_DEF_  "NmAsrCanMsgReducedTime" 50;
BA_DEF_DEF_  "ECU" "";
BA_ "BusType" "CAN";
BA_ "DBName" "ESP_EV";
BA_ "ECU" BU_ ESP_EV "ABS_EV";
BA_ "GenMsgCycleTime" BO_ 1832 500;
BA_ "GenMsgCycleTime" BO_ 1831 500;
BA_ "GenMsgCycleTime" BO_ 401 10;
BA_ "GenMsgCycleTime" BO_ 400 10;
BA_ "GenMsgCycleTime" BO_ 402 10;
BA_ "GenMsgCycleTime" BO_ 393 10;
BA_ "GenMsgCycleTime" BO_ 193 10;
BA_ "GenMsgCycleTime" BO_ 275 10;
BA_ "GenMsgCycleTime" BO_ 378 20;
BA_ "GenMsgCycleTime" BO_ 567 50;
BA_ "GenMsgCycleTime" BO_ 280 10;
BA_ "MessageTimeout" BO_ 1289 1000;
BA_ "GenMsgCycleTime" BO_ 1289 200;
BA_ "MessageTimeout" BO_ 1163 0;
BA_ "GenMsgCycleTime" BO_ 1163 100;
BA_ "GenMsgCycleTime" BO_ 580 100;
BA_ "GenMsgCycleTime" BO_ 579 100;
BA_ "GenMsgCycleTime" BO_ 273 10;
BA_ "GenMsgCycleTime" BO_ 192 10;
BA_ "GenMsgCycleTime" BO_ 370 20;
BA_ "GenMsgCycleTime" BO_ 374 20;
BA_ "GenMsgCycleTime" BO_ 376 20;
BA_ "GenMsgCycleTime" BO_ 656 100;
BA_ "GenMsgCycleTime" BO_ 660 10;
BA_ "GenMsgCycleTime" BO_ 693 10;
BA_ "GenMsgStartDelayTime" BO_ 722 10;
BA_ "GenMsgCycleTime" BO_ 722 100;
BA_ "MessageTimeout" BO_ 946 2500;
BA_ "GenMsgCycleTime" BO_ 946 500;
BA_ "MessageTimeout" BO_ 1274 5000;
BA_ "GenMsgCycleTime" BO_ 1274 1000;
BA_ "MessageTimeout" BO_ 1280 1000;
BA_ "GenMsgCycleTime" BO_ 1280 200;
BA_ "MessageTimeout" BO_ 1872 0;
BA_ "GenMsgSendType" BO_ 1872 8;
BA_ "GenMsgILSupport" BO_ 1872 0;
BA_ "DiagRequest" BO_ 1872 1;
BA_ "MessageTimeout" BO_ 1880 0;
BA_ "GenMsgSendType" BO_ 1880 8;
BA_ "GenMsgILSupport" BO_ 1880 0;
BA_ "DiagResponse" BO_ 1880 1;
BA_ "GenSigTimeoutTime_HU_B" SG_ 3221225472 NoGearshiftReqStatus 0;
BA_ "GenSigTimeoutTime_HU_A" SG_ 3221225472 NoGearshiftReqStatus 0;
BA_ "GenSigTimeoutMsg_HU_B" SG_ 3221225472 NoGearshiftReqStatus 0;
BA_ "GenSigTimeoutMsg_HU_A" SG_ 3221225472 NoGearshiftReqStatus 0;
BA_ "GenSigSendType" SG_ 3221225472 NoGearshiftReqStatus 7;
BA_ "GenSigCycleTimeActive" SG_ 3221225472 NoGearshiftReqStatus 20;
BA_ "GenSigCycleTime" SG_ 3221225472 NoGearshiftReqStatus 20;
BA_ "GenSigTimeoutTime_HU_B" SG_ 3221225472 CruiseCntShutESPStatus 0;
BA_ "GenSigTimeoutTime_HU_A" SG_ 3221225472 CruiseCntShutESPStatus 0;
BA_ "GenSigTimeoutMsg_HU_B" SG_ 3221225472 CruiseCntShutESPStatus 0;
BA_ "GenSigTimeoutMsg_HU_A" SG_ 3221225472 CruiseCntShutESPStatus 0;
BA_ "GenSigSendType" SG_ 3221225472 CruiseCntShutESPStatus 7;
BA_ "GenSigCycleTimeActive" SG_ 3221225472 CruiseCntShutESPStatus 20;
BA_ "GenSigCycleTime" SG_ 3221225472 CruiseCntShutESPStatus 20;
BA_ "GenSigTimeoutTime_HU_B" SG_ 3221225472 CruiseCntShutESP 0;
BA_ "GenSigTimeoutTime_HU_A" SG_ 3221225472 CruiseCntShutESP 0;
BA_ "GenSigTimeoutMsg_HU_B" SG_ 3221225472 CruiseCntShutESP 0;
BA_ "GenSigTimeoutMsg_HU_A" SG_ 3221225472 CruiseCntShutESP 0;
BA_ "GenSigSendType" SG_ 3221225472 CruiseCntShutESP 7;
BA_ "GenSigCycleTimeActive" SG_ 3221225472 CruiseCntShutESP 20;
BA_ "GenSigCycleTime" SG_ 3221225472 CruiseCntShutESP 20;
BA_ "GenSigSendType" SG_ 3221225472 PowerModeStateStatus 7;
BA_ "GenSigCycleTimeActive" SG_ 3221225472 PowerModeStateStatus 100;
BA_ "GenSigCycleTime" SG_ 3221225472 PowerModeStateStatus 100;
BA_ "GenSigStartValue" SG_ 401 CPP_DecelerationRequest 5000;
BA_ "GenSigStartValue" SG_ 400 ACC_DecelerationRequest 5000;
BA_ "GenSigStartValue" SG_ 402 BrakeSys_CPP_TargetDecel 5000;
BA_ "GenSigStartValue" SG_ 402 BrakeSys_ACC_TargetDecel 5000;
BA_ "GenSigStartValue" SG_ 402 BrakeSys_AEB_TargetDecel 500;
BA_ "GenSigStartValue" SG_ 393 AEB_TargetDeceleration 500;
BA_ "GenSigTimeoutTime_HU_B" SG_ 193 LongitAccStatus 0;
BA_ "GenSigTimeoutTime_HU_A" SG_ 193 LongitAccStatus 0;
BA_ "GenSigTimeoutMsg_HU_B" SG_ 193 LongitAccStatus 0;
BA_ "GenSigTimeoutMsg_HU_A" SG_ 193 LongitAccStatus 0;
BA_ "GenSigSendType" SG_ 193 LongitAccStatus 7;
BA_ "GenSigCycleTimeActive" SG_ 193 LongitAccStatus 10;
BA_ "GenSigCycleTime" SG_ 193 LongitAccStatus 10;
BA_ "GenSigTimeoutTime_HU_B" SG_ 193 LatAccStatus 0;
BA_ "GenSigTimeoutTime_HU_A" SG_ 193 LatAccStatus 0;
BA_ "GenSigTimeoutMsg_HU_B" SG_ 193 LatAccStatus 0;
BA_ "GenSigTimeoutMsg_HU_A" SG_ 193 LatAccStatus 0;
BA_ "GenSigSendType" SG_ 193 LatAccStatus 7;
BA_ "GenSigCycleTimeActive" SG_ 193 LatAccStatus 10;
BA_ "GenSigCycleTime" SG_ 193 LatAccStatus 10;
BA_ "GenSigTimeoutTime_HU_B" SG_ 193 YawRateStatus 0;
BA_ "GenSigTimeoutTime_HU_A" SG_ 193 YawRateStatus 0;
BA_ "GenSigTimeoutMsg_HU_B" SG_ 193 YawRateStatus 0;
BA_ "GenSigTimeoutMsg_HU_A" SG_ 193 YawRateStatus 0;
BA_ "GenSigSendType" SG_ 193 YawRateStatus 7;
BA_ "GenSigCycleTimeActive" SG_ 193 YawRateStatus 10;
BA_ "GenSigCycleTime" SG_ 193 YawRateStatus 10;
BA_ "GenSigTimeoutTime_HU_B" SG_ 193 LongitAcc 0;
BA_ "GenSigTimeoutTime_HU_A" SG_ 193 LongitAcc 0;
BA_ "GenSigTimeoutMsg_HU_B" SG_ 193 LongitAcc 0;
BA_ "GenSigTimeoutMsg_HU_A" SG_ 193 LongitAcc 0;
BA_ "GenSigStartValue" SG_ 193 LongitAcc 32766;
BA_ "GenSigSendType" SG_ 193 LongitAcc 7;
BA_ "GenSigCycleTimeActive" SG_ 193 LongitAcc 10;
BA_ "GenSigCycleTime" SG_ 193 LongitAcc 10;
BA_ "GenSigTimeoutTime_HU_B" SG_ 193 LatAcc 0;
BA_ "GenSigTimeoutTime_HU_A" SG_ 193 LatAcc 0;
BA_ "GenSigTimeoutMsg_HU_B" SG_ 193 LatAcc 0;
BA_ "GenSigTimeoutMsg_HU_A" SG_ 193 LatAcc 0;
BA_ "GenSigStartValue" SG_ 193 LatAcc 32766;
BA_ "GenSigSendType" SG_ 193 LatAcc 7;
BA_ "GenSigCycleTimeActive" SG_ 193 LatAcc 10;
BA_ "GenSigCycleTime" SG_ 193 LatAcc 10;
BA_ "GenSigTimeoutTime_HU_B" SG_ 193 YawRate 0;
BA_ "GenSigTimeoutTime_HU_A" SG_ 193 YawRate 0;
BA_ "GenSigTimeoutMsg_HU_B" SG_ 193 YawRate 0;
BA_ "GenSigTimeoutMsg_HU_A" SG_ 193 YawRate 0;
BA_ "GenSigStartValue" SG_ 193 YawRate 32766;
BA_ "GenSigSendType" SG_ 193 YawRate 7;
BA_ "GenSigCycleTimeActive" SG_ 193 YawRate 10;
BA_ "GenSigCycleTime" SG_ 193 YawRate 10;
BA_ "GenSigTimeoutTime_HU_B" SG_ 193 IMuMsgCnt 0;
BA_ "GenSigTimeoutTime_HU_A" SG_ 193 IMuMsgCnt 0;
BA_ "GenSigTimeoutMsg_HU_B" SG_ 193 IMuMsgCnt 0;
BA_ "GenSigTimeoutMsg_HU_A" SG_ 193 IMuMsgCnt 0;
BA_ "GenSigSendType" SG_ 193 IMuMsgCnt 7;
BA_ "GenSigCycleTimeActive" SG_ 193 IMuMsgCnt 10;
BA_ "GenSigCycleTime" SG_ 193 IMuMsgCnt 10;
BA_ "GenSigTimeoutTime_HU_B" SG_ 193 IMuCheckSum 0;
BA_ "GenSigTimeoutTime_HU_A" SG_ 193 IMuCheckSum 0;
BA_ "GenSigTimeoutMsg_HU_B" SG_ 193 IMuCheckSum 0;
BA_ "GenSigTimeoutMsg_HU_A" SG_ 193 IMuCheckSum 0;
BA_ "GenSigSendType" SG_ 193 IMuCheckSum 7;
BA_ "GenSigCycleTimeActive" SG_ 193 IMuCheckSum 10;
BA_ "GenSigCycleTime" SG_ 193 IMuCheckSum 10;
BA_ "GenSigTimeoutTime_HU_Mid_X451" SG_ 275 DriverReqTrqStatus 0;
BA_ "GenSigTimeoutTime_HU_High_X451" SG_ 275 DriverReqTrqStatus 0;
BA_ "GenSigTimeoutTime_HU_B" SG_ 275 DriverReqTrqStatus 0;
BA_ "GenSigTimeoutTime_HU_A" SG_ 275 DriverReqTrqStatus 0;
BA_ "GenSigTimeoutMsg_HU_Mid_X451" SG_ 275 DriverReqTrqStatus 0;
BA_ "GenSigTimeoutMsg_HU_High_X451" SG_ 275 DriverReqTrqStatus 0;
BA_ "GenSigTimeoutMsg_HU_B" SG_ 275 DriverReqTrqStatus 0;
BA_ "GenSigTimeoutMsg_HU_A" SG_ 275 DriverReqTrqStatus 0;
BA_ "GenSigSendType" SG_ 275 DriverReqTrqStatus 7;
BA_ "GenSigCycleTimeActive" SG_ 275 DriverReqTrqStatus 10;
BA_ "GenSigCycleTime" SG_ 275 DriverReqTrqStatus 10;
BA_ "GenSigTimeoutTime_HU_Mid_X451" SG_ 275 DriverReqTrq 0;
BA_ "GenSigTimeoutTime_HU_High_X451" SG_ 275 DriverReqTrq 0;
BA_ "GenSigTimeoutTime_HU_B" SG_ 275 DriverReqTrq 0;
BA_ "GenSigTimeoutTime_HU_A" SG_ 275 DriverReqTrq 0;
BA_ "GenSigTimeoutMsg_HU_Mid_X451" SG_ 275 DriverReqTrq 0;
BA_ "GenSigTimeoutMsg_HU_High_X451" SG_ 275 DriverReqTrq 0;
BA_ "GenSigTimeoutMsg_HU_B" SG_ 275 DriverReqTrq 0;
BA_ "GenSigTimeoutMsg_HU_A" SG_ 275 DriverReqTrq 0;
BA_ "GenSigStartValue" SG_ 275 DriverReqTrq 16384;
BA_ "GenSigSendType" SG_ 275 DriverReqTrq 7;
BA_ "GenSigCycleTimeActive" SG_ 275 DriverReqTrq 10;
BA_ "GenSigCycleTime" SG_ 275 DriverReqTrq 10;
BA_ "GenSigTimeoutTime_HU_Mid_X451" SG_ 275 RecupBrakeState 0;
BA_ "GenSigTimeoutTime_HU_High_X451" SG_ 275 RecupBrakeState 0;
BA_ "GenSigTimeoutTime_HU_B" SG_ 275 RecupBrakeState 0;
BA_ "GenSigTimeoutTime_HU_A" SG_ 275 RecupBrakeState 0;
BA_ "GenSigTimeoutMsg_HU_Mid_X451" SG_ 275 RecupBrakeState 0;
BA_ "GenSigTimeoutMsg_HU_High_X451" SG_ 275 RecupBrakeState 0;
BA_ "GenSigTimeoutMsg_HU_B" SG_ 275 RecupBrakeState 0;
BA_ "GenSigTimeoutMsg_HU_A" SG_ 275 RecupBrakeState 0;
BA_ "GenSigSendType" SG_ 275 RecupBrakeState 7;
BA_ "GenSigCycleTimeActive" SG_ 275 RecupBrakeState 10;
BA_ "GenSigCycleTime" SG_ 275 RecupBrakeState 10;
BA_ "GenSigTimeoutMsg_HU_High_X445" SG_ 275 RecupBrakeState 0;
BA_ "GenSigTimeoutMsg_HU_Mid_X445" SG_ 275 RecupBrakeState 0;
BA_ "GenSigTimeoutTime_HU_High_X445" SG_ 275 RecupBrakeState 0;
BA_ "GenSigTimeoutTime_HU_Mid_X445" SG_ 275 RecupBrakeState 0;
BA_ "GenSigTimeoutTime_HU_Mid_X451" SG_ 275 MaxAvailableRegenTrqStatus 0;
BA_ "GenSigTimeoutTime_HU_High_X451" SG_ 275 MaxAvailableRegenTrqStatus 0;
BA_ "GenSigTimeoutTime_HU_B" SG_ 275 MaxAvailableRegenTrqStatus 0;
BA_ "GenSigTimeoutTime_HU_A" SG_ 275 MaxAvailableRegenTrqStatus 0;
BA_ "GenSigTimeoutMsg_HU_Mid_X451" SG_ 275 MaxAvailableRegenTrqStatus 0;
BA_ "GenSigTimeoutMsg_HU_High_X451" SG_ 275 MaxAvailableRegenTrqStatus 0;
BA_ "GenSigTimeoutMsg_HU_B" SG_ 275 MaxAvailableRegenTrqStatus 0;
BA_ "GenSigTimeoutMsg_HU_A" SG_ 275 MaxAvailableRegenTrqStatus 0;
BA_ "GenSigSendType" SG_ 275 MaxAvailableRegenTrqStatus 7;
BA_ "GenSigCycleTimeActive" SG_ 275 MaxAvailableRegenTrqStatus 10;
BA_ "GenSigCycleTime" SG_ 275 MaxAvailableRegenTrqStatus 10;
BA_ "GenSigTimeoutTime_HU_Mid_X451" SG_ 275 MaxAvailableRegenTrq 0;
BA_ "GenSigTimeoutTime_HU_High_X451" SG_ 275 MaxAvailableRegenTrq 0;
BA_ "GenSigTimeoutTime_HU_B" SG_ 275 MaxAvailableRegenTrq 0;
BA_ "GenSigTimeoutTime_HU_A" SG_ 275 MaxAvailableRegenTrq 0;
BA_ "GenSigTimeoutMsg_HU_Mid_X451" SG_ 275 MaxAvailableRegenTrq 0;
BA_ "GenSigTimeoutMsg_HU_High_X451" SG_ 275 MaxAvailableRegenTrq 0;
BA_ "GenSigTimeoutMsg_HU_B" SG_ 275 MaxAvailableRegenTrq 0;
BA_ "GenSigTimeoutMsg_HU_A" SG_ 275 MaxAvailableRegenTrq 0;
BA_ "GenSigSendType" SG_ 275 MaxAvailableRegenTrq 7;
BA_ "GenSigCycleTimeActive" SG_ 275 MaxAvailableRegenTrq 10;
BA_ "GenSigCycleTime" SG_ 275 MaxAvailableRegenTrq 10;
BA_ "GenSigTimeoutTime_HU_B" SG_ 378 WheelTrqMsgRollCnt 0;
BA_ "GenSigTimeoutTime_HU_A" SG_ 378 WheelTrqMsgRollCnt 0;
BA_ "GenSigTimeoutMsg_HU_B" SG_ 378 WheelTrqMsgRollCnt 0;
BA_ "GenSigTimeoutMsg_HU_A" SG_ 378 WheelTrqMsgRollCnt 0;
BA_ "GenSigSendType" SG_ 378 WheelTrqMsgRollCnt 7;
BA_ "GenSigCycleTimeActive" SG_ 378 WheelTrqMsgRollCnt 20;
BA_ "GenSigCycleTime" SG_ 378 WheelTrqMsgRollCnt 20;
BA_ "GenSigTimeoutTime_HU_B" SG_ 378 WheelTrqMsgCRC 0;
BA_ "GenSigTimeoutTime_HU_A" SG_ 378 WheelTrqMsgCRC 0;
BA_ "GenSigTimeoutMsg_HU_B" SG_ 378 WheelTrqMsgCRC 0;
BA_ "GenSigTimeoutMsg_HU_A" SG_ 378 WheelTrqMsgCRC 0;
BA_ "GenSigSendType" SG_ 378 WheelTrqMsgCRC 7;
BA_ "GenSigCycleTimeActive" SG_ 378 WheelTrqMsgCRC 20;
BA_ "GenSigCycleTime" SG_ 378 WheelTrqMsgCRC 20;
BA_ "GenSigTimeoutTime_HU_B" SG_ 378 WheelTrqLimFastStatus 0;
BA_ "GenSigTimeoutTime_HU_A" SG_ 378 WheelTrqLimFastStatus 0;
BA_ "GenSigTimeoutMsg_HU_B" SG_ 378 WheelTrqLimFastStatus 0;
BA_ "GenSigTimeoutMsg_HU_A" SG_ 378 WheelTrqLimFastStatus 0;
BA_ "GenSigSendType" SG_ 378 WheelTrqLimFastStatus 7;
BA_ "GenSigCycleTimeActive" SG_ 378 WheelTrqLimFastStatus 20;
BA_ "GenSigCycleTime" SG_ 378 WheelTrqLimFastStatus 20;
BA_ "GenSigTimeoutTime_HU_B" SG_ 378 WheelTrqLimFast 0;
BA_ "GenSigTimeoutTime_HU_A" SG_ 378 WheelTrqLimFast 0;
BA_ "GenSigTimeoutMsg_HU_B" SG_ 378 WheelTrqLimFast 0;
BA_ "GenSigTimeoutMsg_HU_A" SG_ 378 WheelTrqLimFast 0;
BA_ "GenSigStartValue" SG_ 378 WheelTrqLimFast 32768;
BA_ "GenSigSendType" SG_ 378 WheelTrqLimFast 7;
BA_ "GenSigCycleTimeActive" SG_ 378 WheelTrqLimFast 20;
BA_ "GenSigCycleTime" SG_ 378 WheelTrqLimFast 20;
BA_ "GenSigSendType" SG_ 378 WheelTrqIncStatus 7;
BA_ "GenSigCycleTimeActive" SG_ 378 WheelTrqIncStatus 20;
BA_ "GenSigCycleTime" SG_ 378 WheelTrqIncStatus 20;
BA_ "GenSigStartValue" SG_ 378 WheelTrqInc 32768;
BA_ "GenSigSendType" SG_ 378 WheelTrqInc 7;
BA_ "GenSigCycleTimeActive" SG_ 378 WheelTrqInc 20;
BA_ "GenSigCycleTime" SG_ 378 WheelTrqInc 20;
BA_ "GenSigSendType" SG_ 567 MCMsAvailability 7;
BA_ "GenSigCycleTimeActive" SG_ 567 MCMsAvailability 50;
BA_ "GenSigCycleTime" SG_ 567 MCMsAvailability 50;
BA_ "GenSigSendType" SG_ 567 MCMsErrorState 7;
BA_ "GenSigCycleTimeActive" SG_ 567 MCMsErrorState 50;
BA_ "GenSigCycleTime" SG_ 567 MCMsErrorState 50;
BA_ "GenSigSendType" SG_ 567 MCMsActive 7;
BA_ "GenSigCycleTimeActive" SG_ 567 MCMsActive 50;
BA_ "GenSigCycleTime" SG_ 567 MCMsActive 50;
BA_ "GenSigSendType" SG_ 567 AVhStatus 7;
BA_ "GenSigCycleTimeActive" SG_ 567 AVhStatus 50;
BA_ "GenSigCycleTime" SG_ 567 AVhStatus 50;
BA_ "GenSigSendType" SG_ 567 AVhState 7;
BA_ "GenSigCycleTimeActive" SG_ 567 AVhState 50;
BA_ "GenSigCycleTime" SG_ 567 AVhState 50;
BA_ "GenSigSendType" SG_ 567 AVhAvailability 7;
BA_ "GenSigCycleTimeActive" SG_ 567 AVhAvailability 50;
BA_ "GenSigCycleTime" SG_ 567 AVhAvailability 50;
BA_ "GenSigStartValue" SG_ 567 EpbState 2;
BA_ "GenSigSendType" SG_ 567 EpbState 7;
BA_ "GenSigCycleTimeActive" SG_ 567 EpbState 50;
BA_ "GenSigCycleTime" SG_ 567 EpbState 50;
BA_ "GenSigStartValue" SG_ 567 EpbErrorState 2;
BA_ "GenSigSendType" SG_ 567 EpbErrorState 7;
BA_ "GenSigCycleTimeActive" SG_ 567 EpbErrorState 50;
BA_ "GenSigCycleTime" SG_ 567 EpbErrorState 50;
BA_ "GenSigSendType" SG_ 567 EpbAvailability 7;
BA_ "GenSigCycleTimeActive" SG_ 567 EpbAvailability 50;
BA_ "GenSigCycleTime" SG_ 567 EpbAvailability 50;
BA_ "GenSigTimeoutTime_HU_Mid_X451" SG_ 280 TarRecupTrqStatus 0;
BA_ "GenSigTimeoutTime_HU_High_X451" SG_ 280 TarRecupTrqStatus 0;
BA_ "GenSigTimeoutTime_HU_B" SG_ 280 TarRecupTrqStatus 0;
BA_ "GenSigTimeoutTime_HU_A" SG_ 280 TarRecupTrqStatus 0;
BA_ "GenSigTimeoutMsg_HU_Mid_X451" SG_ 280 TarRecupTrqStatus 0;
BA_ "GenSigTimeoutMsg_HU_High_X451" SG_ 280 TarRecupTrqStatus 0;
BA_ "GenSigTimeoutMsg_HU_B" SG_ 280 TarRecupTrqStatus 0;
BA_ "GenSigTimeoutMsg_HU_A" SG_ 280 TarRecupTrqStatus 0;
BA_ "GenSigSendType" SG_ 280 TarRecupTrqStatus 7;
BA_ "GenSigCycleTimeActive" SG_ 280 TarRecupTrqStatus 10;
BA_ "GenSigCycleTime" SG_ 280 TarRecupTrqStatus 10;
BA_ "GenSigTimeoutMsg_HU_High_X445" SG_ 280 TarRecupTrqStatus 0;
BA_ "GenSigTimeoutMsg_HU_Mid_X445" SG_ 280 TarRecupTrqStatus 0;
BA_ "GenSigTimeoutTime_HU_High_X445" SG_ 280 TarRecupTrqStatus 0;
BA_ "GenSigTimeoutTime_HU_Mid_X445" SG_ 280 TarRecupTrqStatus 0;
BA_ "GenSigTimeoutTime_HU_Mid_X451" SG_ 280 TarRecupTrq 0;
BA_ "GenSigTimeoutTime_HU_High_X451" SG_ 280 TarRecupTrq 0;
BA_ "GenSigTimeoutTime_HU_B" SG_ 280 TarRecupTrq 0;
BA_ "GenSigTimeoutTime_HU_A" SG_ 280 TarRecupTrq 0;
BA_ "GenSigTimeoutMsg_HU_Mid_X451" SG_ 280 TarRecupTrq 0;
BA_ "GenSigTimeoutMsg_HU_High_X451" SG_ 280 TarRecupTrq 0;
BA_ "GenSigTimeoutMsg_HU_B" SG_ 280 TarRecupTrq 0;
BA_ "GenSigTimeoutMsg_HU_A" SG_ 280 TarRecupTrq 0;
BA_ "GenSigSendType" SG_ 280 TarRecupTrq 7;
BA_ "GenSigCycleTimeActive" SG_ 280 TarRecupTrq 10;
BA_ "GenSigCycleTime" SG_ 280 TarRecupTrq 10;
BA_ "GenSigTimeoutMsg_HU_High_X445" SG_ 280 TarRecupTrq 0;
BA_ "GenSigTimeoutMsg_HU_Mid_X445" SG_ 280 TarRecupTrq 0;
BA_ "GenSigTimeoutTime_HU_High_X445" SG_ 280 TarRecupTrq 0;
BA_ "GenSigTimeoutTime_HU_Mid_X445" SG_ 280 TarRecupTrq 0;
BA_ "GenSigTimeoutTime_HU_Mid_X451" SG_ 280 InhibitCostRecuprationStatus 0;
BA_ "GenSigTimeoutTime_HU_High_X451" SG_ 280 InhibitCostRecuprationStatus 0;
BA_ "GenSigTimeoutTime_HU_B" SG_ 280 InhibitCostRecuprationStatus 0;
BA_ "GenSigTimeoutTime_HU_A" SG_ 280 InhibitCostRecuprationStatus 0;
BA_ "GenSigTimeoutMsg_HU_Mid_X451" SG_ 280 InhibitCostRecuprationStatus 0;
BA_ "GenSigTimeoutMsg_HU_High_X451" SG_ 280 InhibitCostRecuprationStatus 0;
BA_ "GenSigTimeoutMsg_HU_B" SG_ 280 InhibitCostRecuprationStatus 0;
BA_ "GenSigTimeoutMsg_HU_A" SG_ 280 InhibitCostRecuprationStatus 0;
BA_ "GenSigSendType" SG_ 280 InhibitCostRecuprationStatus 7;
BA_ "GenSigCycleTimeActive" SG_ 280 InhibitCostRecuprationStatus 10;
BA_ "GenSigCycleTime" SG_ 280 InhibitCostRecuprationStatus 10;
BA_ "GenSigTimeoutMsg_HU_High_X445" SG_ 280 InhibitCostRecuprationStatus 0;
BA_ "GenSigTimeoutMsg_HU_Mid_X445" SG_ 280 InhibitCostRecuprationStatus 0;
BA_ "GenSigTimeoutTime_HU_High_X445" SG_ 280 InhibitCostRecuprationStatus 0;
BA_ "GenSigTimeoutTime_HU_Mid_X445" SG_ 280 InhibitCostRecuprationStatus 0;
BA_ "GenSigTimeoutTime_HU_Mid_X451" SG_ 280 InhibitCostRecupration 0;
BA_ "GenSigTimeoutTime_HU_High_X451" SG_ 280 InhibitCostRecupration 0;
BA_ "GenSigTimeoutTime_HU_B" SG_ 280 InhibitCostRecupration 0;
BA_ "GenSigTimeoutTime_HU_A" SG_ 280 InhibitCostRecupration 0;
BA_ "GenSigTimeoutMsg_HU_Mid_X451" SG_ 280 InhibitCostRecupration 0;
BA_ "GenSigTimeoutMsg_HU_High_X451" SG_ 280 InhibitCostRecupration 0;
BA_ "GenSigTimeoutMsg_HU_B" SG_ 280 InhibitCostRecupration 0;
BA_ "GenSigTimeoutMsg_HU_A" SG_ 280 InhibitCostRecupration 0;
BA_ "GenSigSendType" SG_ 280 InhibitCostRecupration 7;
BA_ "GenSigCycleTimeActive" SG_ 280 InhibitCostRecupration 10;
BA_ "GenSigCycleTime" SG_ 280 InhibitCostRecupration 10;
BA_ "GenSigTimeoutMsg_HU_High_X445" SG_ 280 InhibitCostRecupration 0;
BA_ "GenSigTimeoutMsg_HU_Mid_X445" SG_ 280 InhibitCostRecupration 0;
BA_ "GenSigTimeoutTime_HU_High_X445" SG_ 280 InhibitCostRecupration 0;
BA_ "GenSigTimeoutTime_HU_Mid_X445" SG_ 280 InhibitCostRecupration 0;
BA_ "GenSigTimeoutTime_HU_Mid_X451" SG_ 280 InhibitRecuprationAbsStatus 0;
BA_ "GenSigTimeoutTime_HU_High_X451" SG_ 280 InhibitRecuprationAbsStatus 0;
BA_ "GenSigTimeoutTime_HU_B" SG_ 280 InhibitRecuprationAbsStatus 0;
BA_ "GenSigTimeoutTime_HU_A" SG_ 280 InhibitRecuprationAbsStatus 0;
BA_ "GenSigTimeoutMsg_HU_Mid_X451" SG_ 280 InhibitRecuprationAbsStatus 0;
BA_ "GenSigTimeoutMsg_HU_High_X451" SG_ 280 InhibitRecuprationAbsStatus 0;
BA_ "GenSigTimeoutMsg_HU_B" SG_ 280 InhibitRecuprationAbsStatus 0;
BA_ "GenSigTimeoutMsg_HU_A" SG_ 280 InhibitRecuprationAbsStatus 0;
BA_ "GenSigSendType" SG_ 280 InhibitRecuprationAbsStatus 7;
BA_ "GenSigCycleTimeActive" SG_ 280 InhibitRecuprationAbsStatus 10;
BA_ "GenSigCycleTime" SG_ 280 InhibitRecuprationAbsStatus 10;
BA_ "GenSigTimeoutMsg_HU_High_X445" SG_ 280 InhibitRecuprationAbsStatus 0;
BA_ "GenSigTimeoutMsg_HU_Mid_X445" SG_ 280 InhibitRecuprationAbsStatus 0;
BA_ "GenSigTimeoutTime_HU_High_X445" SG_ 280 InhibitRecuprationAbsStatus 0;
BA_ "GenSigTimeoutTime_HU_Mid_X445" SG_ 280 InhibitRecuprationAbsStatus 0;
BA_ "GenSigTimeoutTime_HU_Mid_X451" SG_ 280 InhibitRecuprationAbs 0;
BA_ "GenSigTimeoutTime_HU_High_X451" SG_ 280 InhibitRecuprationAbs 0;
BA_ "GenSigTimeoutTime_HU_B" SG_ 280 InhibitRecuprationAbs 0;
BA_ "GenSigTimeoutTime_HU_A" SG_ 280 InhibitRecuprationAbs 0;
BA_ "GenSigTimeoutMsg_HU_Mid_X451" SG_ 280 InhibitRecuprationAbs 0;
BA_ "GenSigTimeoutMsg_HU_High_X451" SG_ 280 InhibitRecuprationAbs 0;
BA_ "GenSigTimeoutMsg_HU_B" SG_ 280 InhibitRecuprationAbs 0;
BA_ "GenSigTimeoutMsg_HU_A" SG_ 280 InhibitRecuprationAbs 0;
BA_ "GenSigSendType" SG_ 280 InhibitRecuprationAbs 7;
BA_ "GenSigCycleTimeActive" SG_ 280 InhibitRecuprationAbs 10;
BA_ "GenSigCycleTime" SG_ 280 InhibitRecuprationAbs 10;
BA_ "GenSigTimeoutMsg_HU_High_X445" SG_ 280 InhibitRecuprationAbs 0;
BA_ "GenSigTimeoutMsg_HU_Mid_X445" SG_ 280 InhibitRecuprationAbs 0;
BA_ "GenSigTimeoutTime_HU_High_X445" SG_ 280 InhibitRecuprationAbs 0;
BA_ "GenSigTimeoutTime_HU_Mid_X445" SG_ 280 InhibitRecuprationAbs 0;
BA_ "GenSigTimeoutTime_HU_Mid_X451" SG_ 1289 PreviousState_ESP 0;
BA_ "GenSigTimeoutTime_HU_High_X451" SG_ 1289 PreviousState_ESP 0;
BA_ "GenSigTimeoutTime_HU_B" SG_ 1289 PreviousState_ESP 0;
BA_ "GenSigTimeoutTime_HU_A" SG_ 1289 PreviousState_ESP 0;
BA_ "GenSigTimeoutMsg_HU_Mid_X451" SG_ 1289 PreviousState_ESP 0;
BA_ "GenSigTimeoutMsg_HU_High_X451" SG_ 1289 PreviousState_ESP 0;
BA_ "GenSigTimeoutMsg_HU_B" SG_ 1289 PreviousState_ESP 0;
BA_ "GenSigTimeoutMsg_HU_A" SG_ 1289 PreviousState_ESP 0;
BA_ "GenSigSendType" SG_ 1289 PreviousState_ESP 7;
BA_ "GenSigCycleTimeActive" SG_ 1289 PreviousState_ESP 200;
BA_ "GenSigCycleTime" SG_ 1289 PreviousState_ESP 200;
BA_ "GenSigTimeoutTime_HU_Mid_X451" SG_ 1289 Reserved63 0;
BA_ "GenSigTimeoutTime_HU_High_X451" SG_ 1289 Reserved63 0;
BA_ "GenSigTimeoutTime_HU_B" SG_ 1289 Reserved63 0;
BA_ "GenSigTimeoutTime_HU_A" SG_ 1289 Reserved63 0;
BA_ "GenSigTimeoutMsg_HU_Mid_X451" SG_ 1289 Reserved63 0;
BA_ "GenSigTimeoutMsg_HU_High_X451" SG_ 1289 Reserved63 0;
BA_ "GenSigTimeoutMsg_HU_B" SG_ 1289 Reserved63 0;
BA_ "GenSigTimeoutMsg_HU_A" SG_ 1289 Reserved63 0;
BA_ "GenSigSendType" SG_ 1289 Reserved63 7;
BA_ "GenSigCycleTimeActive" SG_ 1289 Reserved63 200;
BA_ "GenSigCycleTime" SG_ 1289 Reserved63 200;
BA_ "GenSigTimeoutTime_HU_Mid_X451" SG_ 1289 Reserved62 0;
BA_ "GenSigTimeoutTime_HU_High_X451" SG_ 1289 Reserved62 0;
BA_ "GenSigTimeoutTime_HU_B" SG_ 1289 Reserved62 0;
BA_ "GenSigTimeoutTime_HU_A" SG_ 1289 Reserved62 0;
BA_ "GenSigTimeoutMsg_HU_Mid_X451" SG_ 1289 Reserved62 0;
BA_ "GenSigTimeoutMsg_HU_High_X451" SG_ 1289 Reserved62 0;
BA_ "GenSigTimeoutMsg_HU_B" SG_ 1289 Reserved62 0;
BA_ "GenSigTimeoutMsg_HU_A" SG_ 1289 Reserved62 0;
BA_ "GenSigSendType" SG_ 1289 Reserved62 7;
BA_ "GenSigCycleTimeActive" SG_ 1289 Reserved62 200;
BA_ "GenSigCycleTime" SG_ 1289 Reserved62 200;
BA_ "GenSigTimeoutTime_HU_Mid_X451" SG_ 1289 Reserved61 0;
BA_ "GenSigTimeoutTime_HU_High_X451" SG_ 1289 Reserved61 0;
BA_ "GenSigTimeoutTime_HU_B" SG_ 1289 Reserved61 0;
BA_ "GenSigTimeoutTime_HU_A" SG_ 1289 Reserved61 0;
BA_ "GenSigTimeoutMsg_HU_Mid_X451" SG_ 1289 Reserved61 0;
BA_ "GenSigTimeoutMsg_HU_High_X451" SG_ 1289 Reserved61 0;
BA_ "GenSigTimeoutMsg_HU_B" SG_ 1289 Reserved61 0;
BA_ "GenSigTimeoutMsg_HU_A" SG_ 1289 Reserved61 0;
BA_ "GenSigSendType" SG_ 1289 Reserved61 7;
BA_ "GenSigCycleTimeActive" SG_ 1289 Reserved61 200;
BA_ "GenSigCycleTime" SG_ 1289 Reserved61 200;
BA_ "GenSigTimeoutTime_HU_Mid_X451" SG_ 1289 Reserved60 0;
BA_ "GenSigTimeoutTime_HU_High_X451" SG_ 1289 Reserved60 0;
BA_ "GenSigTimeoutTime_HU_B" SG_ 1289 Reserved60 0;
BA_ "GenSigTimeoutTime_HU_A" SG_ 1289 Reserved60 0;
BA_ "GenSigTimeoutMsg_HU_Mid_X451" SG_ 1289 Reserved60 0;
BA_ "GenSigTimeoutMsg_HU_High_X451" SG_ 1289 Reserved60 0;
BA_ "GenSigTimeoutMsg_HU_B" SG_ 1289 Reserved60 0;
BA_ "GenSigTimeoutMsg_HU_A" SG_ 1289 Reserved60 0;
BA_ "GenSigSendType" SG_ 1289 Reserved60 7;
BA_ "GenSigCycleTimeActive" SG_ 1289 Reserved60 200;
BA_ "GenSigCycleTime" SG_ 1289 Reserved60 200;
BA_ "GenSigTimeoutTime_HU_Mid_X451" SG_ 1289 Reserved59 0;
BA_ "GenSigTimeoutTime_HU_High_X451" SG_ 1289 Reserved59 0;
BA_ "GenSigTimeoutTime_HU_B" SG_ 1289 Reserved59 0;
BA_ "GenSigTimeoutTime_HU_A" SG_ 1289 Reserved59 0;
BA_ "GenSigTimeoutMsg_HU_Mid_X451" SG_ 1289 Reserved59 0;
BA_ "GenSigTimeoutMsg_HU_High_X451" SG_ 1289 Reserved59 0;
BA_ "GenSigTimeoutMsg_HU_B" SG_ 1289 Reserved59 0;
BA_ "GenSigTimeoutMsg_HU_A" SG_ 1289 Reserved59 0;
BA_ "GenSigSendType" SG_ 1289 Reserved59 7;
BA_ "GenSigCycleTimeActive" SG_ 1289 Reserved59 200;
BA_ "GenSigCycleTime" SG_ 1289 Reserved59 200;
BA_ "GenSigTimeoutTime_HU_Mid_X451" SG_ 1289 Reserved58 0;
BA_ "GenSigTimeoutTime_HU_High_X451" SG_ 1289 Reserved58 0;
BA_ "GenSigTimeoutTime_HU_B" SG_ 1289 Reserved58 0;
BA_ "GenSigTimeoutTime_HU_A" SG_ 1289 Reserved58 0;
BA_ "GenSigTimeoutMsg_HU_Mid_X451" SG_ 1289 Reserved58 0;
BA_ "GenSigTimeoutMsg_HU_High_X451" SG_ 1289 Reserved58 0;
BA_ "GenSigTimeoutMsg_HU_B" SG_ 1289 Reserved58 0;
BA_ "GenSigTimeoutMsg_HU_A" SG_ 1289 Reserved58 0;
BA_ "GenSigSendType" SG_ 1289 Reserved58 7;
BA_ "GenSigCycleTimeActive" SG_ 1289 Reserved58 200;
BA_ "GenSigCycleTime" SG_ 1289 Reserved58 200;
BA_ "GenSigTimeoutTime_HU_Mid_X451" SG_ 1289 Reserved57 0;
BA_ "GenSigTimeoutTime_HU_High_X451" SG_ 1289 Reserved57 0;
BA_ "GenSigTimeoutTime_HU_B" SG_ 1289 Reserved57 0;
BA_ "GenSigTimeoutTime_HU_A" SG_ 1289 Reserved57 0;
BA_ "GenSigTimeoutMsg_HU_Mid_X451" SG_ 1289 Reserved57 0;
BA_ "GenSigTimeoutMsg_HU_High_X451" SG_ 1289 Reserved57 0;
BA_ "GenSigTimeoutMsg_HU_B" SG_ 1289 Reserved57 0;
BA_ "GenSigTimeoutMsg_HU_A" SG_ 1289 Reserved57 0;
BA_ "GenSigSendType" SG_ 1289 Reserved57 7;
BA_ "GenSigCycleTimeActive" SG_ 1289 Reserved57 200;
BA_ "GenSigCycleTime" SG_ 1289 Reserved57 200;
BA_ "GenSigTimeoutTime_HU_Mid_X451" SG_ 1289 Reserved56 0;
BA_ "GenSigTimeoutTime_HU_High_X451" SG_ 1289 Reserved56 0;
BA_ "GenSigTimeoutTime_HU_B" SG_ 1289 Reserved56 0;
BA_ "GenSigTimeoutTime_HU_A" SG_ 1289 Reserved56 0;
BA_ "GenSigTimeoutMsg_HU_Mid_X451" SG_ 1289 Reserved56 0;
BA_ "GenSigTimeoutMsg_HU_High_X451" SG_ 1289 Reserved56 0;
BA_ "GenSigTimeoutMsg_HU_B" SG_ 1289 Reserved56 0;
BA_ "GenSigTimeoutMsg_HU_A" SG_ 1289 Reserved56 0;
BA_ "GenSigSendType" SG_ 1289 Reserved56 7;
BA_ "GenSigCycleTimeActive" SG_ 1289 Reserved56 200;
BA_ "GenSigCycleTime" SG_ 1289 Reserved56 200;
BA_ "GenSigTimeoutTime_HU_Mid_X451" SG_ 1289 RepeatMessageReq_ESP 0;
BA_ "GenSigTimeoutTime_HU_High_X451" SG_ 1289 RepeatMessageReq_ESP 0;
BA_ "GenSigTimeoutTime_HU_B" SG_ 1289 RepeatMessageReq_ESP 0;
BA_ "GenSigTimeoutTime_HU_A" SG_ 1289 RepeatMessageReq_ESP 0;
BA_ "GenSigTimeoutMsg_HU_Mid_X451" SG_ 1289 RepeatMessageReq_ESP 0;
BA_ "GenSigTimeoutMsg_HU_High_X451" SG_ 1289 RepeatMessageReq_ESP 0;
BA_ "GenSigTimeoutMsg_HU_B" SG_ 1289 RepeatMessageReq_ESP 0;
BA_ "GenSigTimeoutMsg_HU_A" SG_ 1289 RepeatMessageReq_ESP 0;
BA_ "GenSigSendType" SG_ 1289 RepeatMessageReq_ESP 7;
BA_ "GenSigCycleTimeActive" SG_ 1289 RepeatMessageReq_ESP 200;
BA_ "GenSigCycleTime" SG_ 1289 RepeatMessageReq_ESP 200;
BA_ "GenSigTimeoutTime_HU_Mid_X451" SG_ 1289 PartialNetworkInformation_ESP 0;
BA_ "GenSigTimeoutTime_HU_High_X451" SG_ 1289 PartialNetworkInformation_ESP 0;
BA_ "GenSigTimeoutTime_HU_B" SG_ 1289 PartialNetworkInformation_ESP 0;
BA_ "GenSigTimeoutTime_HU_A" SG_ 1289 PartialNetworkInformation_ESP 0;
BA_ "GenSigTimeoutMsg_HU_Mid_X451" SG_ 1289 PartialNetworkInformation_ESP 0;
BA_ "GenSigTimeoutMsg_HU_High_X451" SG_ 1289 PartialNetworkInformation_ESP 0;
BA_ "GenSigTimeoutMsg_HU_B" SG_ 1289 PartialNetworkInformation_ESP 0;
BA_ "GenSigTimeoutMsg_HU_A" SG_ 1289 PartialNetworkInformation_ESP 0;
BA_ "GenSigSendType" SG_ 1289 PartialNetworkInformation_ESP 7;
BA_ "GenSigCycleTimeActive" SG_ 1289 PartialNetworkInformation_ESP 200;
BA_ "GenSigCycleTime" SG_ 1289 PartialNetworkInformation_ESP 200;
BA_ "GenSigTimeoutTime_HU_Mid_X451" SG_ 1289 NMCoOrdSlpReady_ESP 0;
BA_ "GenSigTimeoutTime_HU_High_X451" SG_ 1289 NMCoOrdSlpReady_ESP 0;
BA_ "GenSigTimeoutTime_HU_B" SG_ 1289 NMCoOrdSlpReady_ESP 0;
BA_ "GenSigTimeoutTime_HU_A" SG_ 1289 NMCoOrdSlpReady_ESP 0;
BA_ "GenSigTimeoutMsg_HU_Mid_X451" SG_ 1289 NMCoOrdSlpReady_ESP 0;
BA_ "GenSigTimeoutMsg_HU_High_X451" SG_ 1289 NMCoOrdSlpReady_ESP 0;
BA_ "GenSigTimeoutMsg_HU_B" SG_ 1289 NMCoOrdSlpReady_ESP 0;
BA_ "GenSigTimeoutMsg_HU_A" SG_ 1289 NMCoOrdSlpReady_ESP 0;
BA_ "GenSigSendType" SG_ 1289 NMCoOrdSlpReady_ESP 7;
BA_ "GenSigCycleTimeActive" SG_ 1289 NMCoOrdSlpReady_ESP 200;
BA_ "GenSigCycleTime" SG_ 1289 NMCoOrdSlpReady_ESP 200;
BA_ "GenSigTimeoutTime_HU_Mid_X451" SG_ 1289 ESP_NMPDU_USER_DATA_D5 0;
BA_ "GenSigTimeoutTime_HU_High_X451" SG_ 1289 ESP_NMPDU_USER_DATA_D5 0;
BA_ "GenSigTimeoutTime_HU_B" SG_ 1289 ESP_NMPDU_USER_DATA_D5 0;
BA_ "GenSigTimeoutTime_HU_A" SG_ 1289 ESP_NMPDU_USER_DATA_D5 0;
BA_ "GenSigTimeoutMsg_HU_Mid_X451" SG_ 1289 ESP_NMPDU_USER_DATA_D5 0;
BA_ "GenSigTimeoutMsg_HU_High_X451" SG_ 1289 ESP_NMPDU_USER_DATA_D5 0;
BA_ "GenSigTimeoutMsg_HU_B" SG_ 1289 ESP_NMPDU_USER_DATA_D5 0;
BA_ "GenSigTimeoutMsg_HU_A" SG_ 1289 ESP_NMPDU_USER_DATA_D5 0;
BA_ "GenSigSendType" SG_ 1289 ESP_NMPDU_USER_DATA_D5 7;
BA_ "GenSigCycleTimeActive" SG_ 1289 ESP_NMPDU_USER_DATA_D5 200;
BA_ "GenSigCycleTime" SG_ 1289 ESP_NMPDU_USER_DATA_D5 200;
BA_ "GenSigTimeoutTime_HU_Mid_X451" SG_ 1289 ESP_NMPDU_USER_DATA_D4 0;
BA_ "GenSigTimeoutTime_HU_High_X451" SG_ 1289 ESP_NMPDU_USER_DATA_D4 0;
BA_ "GenSigTimeoutTime_HU_B" SG_ 1289 ESP_NMPDU_USER_DATA_D4 0;
BA_ "GenSigTimeoutTime_HU_A" SG_ 1289 ESP_NMPDU_USER_DATA_D4 0;
BA_ "GenSigTimeoutMsg_HU_Mid_X451" SG_ 1289 ESP_NMPDU_USER_DATA_D4 0;
BA_ "GenSigTimeoutMsg_HU_High_X451" SG_ 1289 ESP_NMPDU_USER_DATA_D4 0;
BA_ "GenSigTimeoutMsg_HU_B" SG_ 1289 ESP_NMPDU_USER_DATA_D4 0;
BA_ "GenSigTimeoutMsg_HU_A" SG_ 1289 ESP_NMPDU_USER_DATA_D4 0;
BA_ "GenSigSendType" SG_ 1289 ESP_NMPDU_USER_DATA_D4 7;
BA_ "GenSigCycleTimeActive" SG_ 1289 ESP_NMPDU_USER_DATA_D4 200;
BA_ "GenSigCycleTime" SG_ 1289 ESP_NMPDU_USER_DATA_D4 200;
BA_ "GenSigTimeoutTime_HU_Mid_X451" SG_ 1289 ESP_NMPDU_USER_DATA_D3 0;
BA_ "GenSigTimeoutTime_HU_High_X451" SG_ 1289 ESP_NMPDU_USER_DATA_D3 0;
BA_ "GenSigTimeoutTime_HU_B" SG_ 1289 ESP_NMPDU_USER_DATA_D3 0;
BA_ "GenSigTimeoutTime_HU_A" SG_ 1289 ESP_NMPDU_USER_DATA_D3 0;
BA_ "GenSigTimeoutMsg_HU_Mid_X451" SG_ 1289 ESP_NMPDU_USER_DATA_D3 0;
BA_ "GenSigTimeoutMsg_HU_High_X451" SG_ 1289 ESP_NMPDU_USER_DATA_D3 0;
BA_ "GenSigTimeoutMsg_HU_B" SG_ 1289 ESP_NMPDU_USER_DATA_D3 0;
BA_ "GenSigTimeoutMsg_HU_A" SG_ 1289 ESP_NMPDU_USER_DATA_D3 0;
BA_ "GenSigSendType" SG_ 1289 ESP_NMPDU_USER_DATA_D3 7;
BA_ "GenSigCycleTimeActive" SG_ 1289 ESP_NMPDU_USER_DATA_D3 200;
BA_ "GenSigCycleTime" SG_ 1289 ESP_NMPDU_USER_DATA_D3 200;
BA_ "GenSigTimeoutTime_HU_Mid_X451" SG_ 1289 ESP_NMPDU_USER_DATA_D2 0;
BA_ "GenSigTimeoutTime_HU_High_X451" SG_ 1289 ESP_NMPDU_USER_DATA_D2 0;
BA_ "GenSigTimeoutTime_HU_B" SG_ 1289 ESP_NMPDU_USER_DATA_D2 0;
BA_ "GenSigTimeoutTime_HU_A" SG_ 1289 ESP_NMPDU_USER_DATA_D2 0;
BA_ "GenSigTimeoutMsg_HU_Mid_X451" SG_ 1289 ESP_NMPDU_USER_DATA_D2 0;
BA_ "GenSigTimeoutMsg_HU_High_X451" SG_ 1289 ESP_NMPDU_USER_DATA_D2 0;
BA_ "GenSigTimeoutMsg_HU_B" SG_ 1289 ESP_NMPDU_USER_DATA_D2 0;
BA_ "GenSigTimeoutMsg_HU_A" SG_ 1289 ESP_NMPDU_USER_DATA_D2 0;
BA_ "GenSigSendType" SG_ 1289 ESP_NMPDU_USER_DATA_D2 7;
BA_ "GenSigCycleTimeActive" SG_ 1289 ESP_NMPDU_USER_DATA_D2 200;
BA_ "GenSigCycleTime" SG_ 1289 ESP_NMPDU_USER_DATA_D2 200;
BA_ "GenSigTimeoutTime_HU_Mid_X451" SG_ 1289 ESP_NMPDU_USER_DATA_D1 0;
BA_ "GenSigTimeoutTime_HU_High_X451" SG_ 1289 ESP_NMPDU_USER_DATA_D1 0;
BA_ "GenSigTimeoutTime_HU_B" SG_ 1289 ESP_NMPDU_USER_DATA_D1 0;
BA_ "GenSigTimeoutTime_HU_A" SG_ 1289 ESP_NMPDU_USER_DATA_D1 0;
BA_ "GenSigTimeoutMsg_HU_Mid_X451" SG_ 1289 ESP_NMPDU_USER_DATA_D1 0;
BA_ "GenSigTimeoutMsg_HU_High_X451" SG_ 1289 ESP_NMPDU_USER_DATA_D1 0;
BA_ "GenSigTimeoutMsg_HU_B" SG_ 1289 ESP_NMPDU_USER_DATA_D1 0;
BA_ "GenSigTimeoutMsg_HU_A" SG_ 1289 ESP_NMPDU_USER_DATA_D1 0;
BA_ "GenSigSendType" SG_ 1289 ESP_NMPDU_USER_DATA_D1 7;
BA_ "GenSigCycleTimeActive" SG_ 1289 ESP_NMPDU_USER_DATA_D1 200;
BA_ "GenSigCycleTime" SG_ 1289 ESP_NMPDU_USER_DATA_D1 200;
BA_ "GenSigTimeoutTime_HU_Mid_X451" SG_ 1289 ESP_NMPDU_SRC_ECU_ID 0;
BA_ "GenSigTimeoutTime_HU_High_X451" SG_ 1289 ESP_NMPDU_SRC_ECU_ID 0;
BA_ "GenSigTimeoutTime_HU_B" SG_ 1289 ESP_NMPDU_SRC_ECU_ID 0;
BA_ "GenSigTimeoutTime_HU_A" SG_ 1289 ESP_NMPDU_SRC_ECU_ID 0;
BA_ "GenSigTimeoutMsg_HU_Mid_X451" SG_ 1289 ESP_NMPDU_SRC_ECU_ID 0;
BA_ "GenSigTimeoutMsg_HU_High_X451" SG_ 1289 ESP_NMPDU_SRC_ECU_ID 0;
BA_ "GenSigTimeoutMsg_HU_B" SG_ 1289 ESP_NMPDU_SRC_ECU_ID 0;
BA_ "GenSigTimeoutMsg_HU_A" SG_ 1289 ESP_NMPDU_SRC_ECU_ID 0;
BA_ "GenSigSendType" SG_ 1289 ESP_NMPDU_SRC_ECU_ID 7;
BA_ "GenSigCycleTimeActive" SG_ 1289 ESP_NMPDU_SRC_ECU_ID 200;
BA_ "GenSigCycleTime" SG_ 1289 ESP_NMPDU_SRC_ECU_ID 200;
BA_ "GenSigTimeoutTime_HU_Mid_X451" SG_ 1289 CurrentState_ESP 0;
BA_ "GenSigTimeoutTime_HU_High_X451" SG_ 1289 CurrentState_ESP 0;
BA_ "GenSigTimeoutTime_HU_B" SG_ 1289 CurrentState_ESP 0;
BA_ "GenSigTimeoutTime_HU_A" SG_ 1289 CurrentState_ESP 0;
BA_ "GenSigTimeoutMsg_HU_Mid_X451" SG_ 1289 CurrentState_ESP 0;
BA_ "GenSigTimeoutMsg_HU_High_X451" SG_ 1289 CurrentState_ESP 0;
BA_ "GenSigTimeoutMsg_HU_B" SG_ 1289 CurrentState_ESP 0;
BA_ "GenSigTimeoutMsg_HU_A" SG_ 1289 CurrentState_ESP 0;
BA_ "GenSigSendType" SG_ 1289 CurrentState_ESP 7;
BA_ "GenSigCycleTimeActive" SG_ 1289 CurrentState_ESP 200;
BA_ "GenSigCycleTime" SG_ 1289 CurrentState_ESP 200;
BA_ "GenSigTimeoutTime_HU_Mid_X451" SG_ 1289 ActiveWakeUp_ESP 0;
BA_ "GenSigTimeoutTime_HU_High_X451" SG_ 1289 ActiveWakeUp_ESP 0;
BA_ "GenSigTimeoutTime_HU_B" SG_ 1289 ActiveWakeUp_ESP 0;
BA_ "GenSigTimeoutTime_HU_A" SG_ 1289 ActiveWakeUp_ESP 0;
BA_ "GenSigTimeoutMsg_HU_Mid_X451" SG_ 1289 ActiveWakeUp_ESP 0;
BA_ "GenSigTimeoutMsg_HU_High_X451" SG_ 1289 ActiveWakeUp_ESP 0;
BA_ "GenSigTimeoutMsg_HU_B" SG_ 1289 ActiveWakeUp_ESP 0;
BA_ "GenSigTimeoutMsg_HU_A" SG_ 1289 ActiveWakeUp_ESP 0;
BA_ "GenSigSendType" SG_ 1289 ActiveWakeUp_ESP 7;
BA_ "GenSigCycleTimeActive" SG_ 1289 ActiveWakeUp_ESP 200;
BA_ "GenSigCycleTime" SG_ 1289 ActiveWakeUp_ESP 200;
BA_ "GenSigTimeoutTime_HU_Mid_X451" SG_ 1163 VCUMToFailureStatus 0;
BA_ "GenSigTimeoutTime_HU_High_X451" SG_ 1163 VCUMToFailureStatus 0;
BA_ "GenSigTimeoutTime_HU_B" SG_ 1163 VCUMToFailureStatus 0;
BA_ "GenSigTimeoutTime_HU_A" SG_ 1163 VCUMToFailureStatus 0;
BA_ "GenSigTimeoutMsg_HU_Mid_X451" SG_ 1163 VCUMToFailureStatus 0;
BA_ "GenSigTimeoutMsg_HU_High_X451" SG_ 1163 VCUMToFailureStatus 0;
BA_ "GenSigTimeoutMsg_HU_B" SG_ 1163 VCUMToFailureStatus 0;
BA_ "GenSigTimeoutMsg_HU_A" SG_ 1163 VCUMToFailureStatus 0;
BA_ "GenSigSendType" SG_ 1163 VCUMToFailureStatus 7;
BA_ "GenSigCycleTimeActive" SG_ 1163 VCUMToFailureStatus 100;
BA_ "GenSigCycleTime" SG_ 1163 VCUMToFailureStatus 100;
BA_ "GenSigTimeoutTime_HU_Mid_X451" SG_ 1163 VCUInvalidFailureStatus 0;
BA_ "GenSigTimeoutTime_HU_High_X451" SG_ 1163 VCUInvalidFailureStatus 0;
BA_ "GenSigTimeoutTime_HU_B" SG_ 1163 VCUInvalidFailureStatus 0;
BA_ "GenSigTimeoutTime_HU_A" SG_ 1163 VCUInvalidFailureStatus 0;
BA_ "GenSigTimeoutMsg_HU_Mid_X451" SG_ 1163 VCUInvalidFailureStatus 0;
BA_ "GenSigTimeoutMsg_HU_High_X451" SG_ 1163 VCUInvalidFailureStatus 0;
BA_ "GenSigTimeoutMsg_HU_B" SG_ 1163 VCUInvalidFailureStatus 0;
BA_ "GenSigTimeoutMsg_HU_A" SG_ 1163 VCUInvalidFailureStatus 0;
BA_ "GenSigSendType" SG_ 1163 VCUInvalidFailureStatus 7;
BA_ "GenSigCycleTimeActive" SG_ 1163 VCUInvalidFailureStatus 100;
BA_ "GenSigCycleTime" SG_ 1163 VCUInvalidFailureStatus 100;
BA_ "GenSigTimeoutTime_HU_Mid_X451" SG_ 580 VehicleStatus 0;
BA_ "GenSigTimeoutTime_HU_High_X451" SG_ 580 VehicleStatus 0;
BA_ "GenSigTimeoutTime_HU_B" SG_ 580 VehicleStatus 0;
BA_ "GenSigTimeoutTime_HU_A" SG_ 580 VehicleStatus 0;
BA_ "GenSigTimeoutMsg_HU_Mid_X451" SG_ 580 VehicleStatus 0;
BA_ "GenSigTimeoutMsg_HU_High_X451" SG_ 580 VehicleStatus 0;
BA_ "GenSigTimeoutMsg_HU_B" SG_ 580 VehicleStatus 0;
BA_ "GenSigTimeoutMsg_HU_A" SG_ 580 VehicleStatus 0;
BA_ "GenSigSendType" SG_ 580 VehicleStatus 7;
BA_ "GenSigCycleTimeActive" SG_ 580 VehicleStatus 100;
BA_ "GenSigCycleTime" SG_ 580 VehicleStatus 100;
BA_ "GenSigSendType" SG_ 580 VcuPowerMode 7;
BA_ "GenSigCycleTimeActive" SG_ 580 VcuPowerMode 100;
BA_ "GenSigCycleTime" SG_ 580 VcuPowerMode 100;
BA_ "GenSigSendType" SG_ 580 VcuPowerModeStatus 7;
BA_ "GenSigCycleTimeActive" SG_ 580 VcuPowerModeStatus 100;
BA_ "GenSigCycleTime" SG_ 580 VcuPowerModeStatus 100;
BA_ "GenSigTimeoutTime_HU_Mid_X451" SG_ 579 GearForDisplayVcu 0;
BA_ "GenSigTimeoutTime_HU_High_X451" SG_ 579 GearForDisplayVcu 0;
BA_ "GenSigTimeoutTime_HU_B" SG_ 579 GearForDisplayVcu 0;
BA_ "GenSigTimeoutTime_HU_A" SG_ 579 GearForDisplayVcu 0;
BA_ "GenSigTimeoutMsg_HU_Mid_X451" SG_ 579 GearForDisplayVcu 0;
BA_ "GenSigTimeoutMsg_HU_High_X451" SG_ 579 GearForDisplayVcu 0;
BA_ "GenSigTimeoutMsg_HU_B" SG_ 579 GearForDisplayVcu 0;
BA_ "GenSigTimeoutMsg_HU_A" SG_ 579 GearForDisplayVcu 0;
BA_ "GenSigStartValue" SG_ 579 GearForDisplayVcu 1;
BA_ "GenSigSendType" SG_ 579 GearForDisplayVcu 7;
BA_ "GenSigCycleTimeActive" SG_ 579 GearForDisplayVcu 100;
BA_ "GenSigCycleTime" SG_ 579 GearForDisplayVcu 100;
BA_ "GenSigTimeoutTime_HU_Mid_X451" SG_ 579 GearForDisplayVcuStatus 0;
BA_ "GenSigTimeoutTime_HU_High_X451" SG_ 579 GearForDisplayVcuStatus 0;
BA_ "GenSigTimeoutTime_HU_B" SG_ 579 GearForDisplayVcuStatus 0;
BA_ "GenSigTimeoutTime_HU_A" SG_ 579 GearForDisplayVcuStatus 0;
BA_ "GenSigTimeoutMsg_HU_Mid_X451" SG_ 579 GearForDisplayVcuStatus 0;
BA_ "GenSigTimeoutMsg_HU_High_X451" SG_ 579 GearForDisplayVcuStatus 0;
BA_ "GenSigTimeoutMsg_HU_B" SG_ 579 GearForDisplayVcuStatus 0;
BA_ "GenSigTimeoutMsg_HU_A" SG_ 579 GearForDisplayVcuStatus 0;
BA_ "GenSigSendType" SG_ 579 GearForDisplayVcuStatus 7;
BA_ "GenSigCycleTimeActive" SG_ 579 GearForDisplayVcuStatus 100;
BA_ "GenSigCycleTime" SG_ 579 GearForDisplayVcuStatus 100;
BA_ "GenSigTimeoutTime_HU_Mid_X451" SG_ 273 CurrentTorqueAtMotorStatus 0;
BA_ "GenSigTimeoutTime_HU_High_X451" SG_ 273 CurrentTorqueAtMotorStatus 0;
BA_ "GenSigTimeoutTime_HU_B" SG_ 273 CurrentTorqueAtMotorStatus 0;
BA_ "GenSigTimeoutTime_HU_A" SG_ 273 CurrentTorqueAtMotorStatus 0;
BA_ "GenSigTimeoutMsg_HU_Mid_X451" SG_ 273 CurrentTorqueAtMotorStatus 0;
BA_ "GenSigTimeoutMsg_HU_High_X451" SG_ 273 CurrentTorqueAtMotorStatus 0;
BA_ "GenSigTimeoutMsg_HU_B" SG_ 273 CurrentTorqueAtMotorStatus 0;
BA_ "GenSigTimeoutMsg_HU_A" SG_ 273 CurrentTorqueAtMotorStatus 0;
BA_ "GenSigSendType" SG_ 273 CurrentTorqueAtMotorStatus 7;
BA_ "GenSigCycleTimeActive" SG_ 273 CurrentTorqueAtMotorStatus 10;
BA_ "GenSigCycleTime" SG_ 273 CurrentTorqueAtMotorStatus 10;
BA_ "GenSigTimeoutTime_HU_Mid_X451" SG_ 273 CurrentTorqueAtMotor 0;
BA_ "GenSigTimeoutTime_HU_High_X451" SG_ 273 CurrentTorqueAtMotor 0;
BA_ "GenSigTimeoutTime_HU_B" SG_ 273 CurrentTorqueAtMotor 0;
BA_ "GenSigTimeoutTime_HU_A" SG_ 273 CurrentTorqueAtMotor 0;
BA_ "GenSigTimeoutMsg_HU_Mid_X451" SG_ 273 CurrentTorqueAtMotor 0;
BA_ "GenSigTimeoutMsg_HU_High_X451" SG_ 273 CurrentTorqueAtMotor 0;
BA_ "GenSigTimeoutMsg_HU_B" SG_ 273 CurrentTorqueAtMotor 0;
BA_ "GenSigTimeoutMsg_HU_A" SG_ 273 CurrentTorqueAtMotor 0;
BA_ "GenSigStartValue" SG_ 273 CurrentTorqueAtMotor 16384;
BA_ "GenSigSendType" SG_ 273 CurrentTorqueAtMotor 7;
BA_ "GenSigCycleTimeActive" SG_ 273 CurrentTorqueAtMotor 10;
BA_ "GenSigCycleTime" SG_ 273 CurrentTorqueAtMotor 10;
BA_ "GenSigTimeoutTime_HU_Mid_X451" SG_ 273 RecuprationActualTorqueStatus 0;
BA_ "GenSigTimeoutTime_HU_High_X451" SG_ 273 RecuprationActualTorqueStatus 0;
BA_ "GenSigTimeoutTime_HU_B" SG_ 273 RecuprationActualTorqueStatus 0;
BA_ "GenSigTimeoutTime_HU_A" SG_ 273 RecuprationActualTorqueStatus 0;
BA_ "GenSigTimeoutMsg_HU_Mid_X451" SG_ 273 RecuprationActualTorqueStatus 0;
BA_ "GenSigTimeoutMsg_HU_High_X451" SG_ 273 RecuprationActualTorqueStatus 0;
BA_ "GenSigTimeoutMsg_HU_B" SG_ 273 RecuprationActualTorqueStatus 0;
BA_ "GenSigTimeoutMsg_HU_A" SG_ 273 RecuprationActualTorqueStatus 0;
BA_ "GenSigSendType" SG_ 273 RecuprationActualTorqueStatus 7;
BA_ "GenSigCycleTimeActive" SG_ 273 RecuprationActualTorqueStatus 10;
BA_ "GenSigCycleTime" SG_ 273 RecuprationActualTorqueStatus 10;
BA_ "GenSigTimeoutTime_HU_Mid_X451" SG_ 273 RecuprationActualTorque 0;
BA_ "GenSigTimeoutTime_HU_High_X451" SG_ 273 RecuprationActualTorque 0;
BA_ "GenSigTimeoutTime_HU_B" SG_ 273 RecuprationActualTorque 0;
BA_ "GenSigTimeoutTime_HU_A" SG_ 273 RecuprationActualTorque 0;
BA_ "GenSigTimeoutMsg_HU_Mid_X451" SG_ 273 RecuprationActualTorque 0;
BA_ "GenSigTimeoutMsg_HU_High_X451" SG_ 273 RecuprationActualTorque 0;
BA_ "GenSigTimeoutMsg_HU_B" SG_ 273 RecuprationActualTorque 0;
BA_ "GenSigTimeoutMsg_HU_A" SG_ 273 RecuprationActualTorque 0;
BA_ "GenSigSendType" SG_ 273 RecuprationActualTorque 7;
BA_ "GenSigCycleTimeActive" SG_ 273 RecuprationActualTorque 10;
BA_ "GenSigCycleTime" SG_ 273 RecuprationActualTorque 10;
BA_ "GenSigTimeoutTime_HU_Mid_X451" SG_ 273 CurrentTorqueToWheelStatus 0;
BA_ "GenSigTimeoutTime_HU_High_X451" SG_ 273 CurrentTorqueToWheelStatus 0;
BA_ "GenSigTimeoutTime_HU_B" SG_ 273 CurrentTorqueToWheelStatus 0;
BA_ "GenSigTimeoutTime_HU_A" SG_ 273 CurrentTorqueToWheelStatus 0;
BA_ "GenSigTimeoutMsg_HU_Mid_X451" SG_ 273 CurrentTorqueToWheelStatus 0;
BA_ "GenSigTimeoutMsg_HU_High_X451" SG_ 273 CurrentTorqueToWheelStatus 0;
BA_ "GenSigTimeoutMsg_HU_B" SG_ 273 CurrentTorqueToWheelStatus 0;
BA_ "GenSigTimeoutMsg_HU_A" SG_ 273 CurrentTorqueToWheelStatus 0;
BA_ "GenSigSendType" SG_ 273 CurrentTorqueToWheelStatus 7;
BA_ "GenSigCycleTimeActive" SG_ 273 CurrentTorqueToWheelStatus 10;
BA_ "GenSigCycleTime" SG_ 273 CurrentTorqueToWheelStatus 10;
BA_ "GenSigTimeoutTime_HU_Mid_X451" SG_ 273 CurrentTorqueToWheel 0;
BA_ "GenSigTimeoutTime_HU_High_X451" SG_ 273 CurrentTorqueToWheel 0;
BA_ "GenSigTimeoutTime_HU_B" SG_ 273 CurrentTorqueToWheel 0;
BA_ "GenSigTimeoutTime_HU_A" SG_ 273 CurrentTorqueToWheel 0;
BA_ "GenSigTimeoutMsg_HU_Mid_X451" SG_ 273 CurrentTorqueToWheel 0;
BA_ "GenSigTimeoutMsg_HU_High_X451" SG_ 273 CurrentTorqueToWheel 0;
BA_ "GenSigTimeoutMsg_HU_B" SG_ 273 CurrentTorqueToWheel 0;
BA_ "GenSigTimeoutMsg_HU_A" SG_ 273 CurrentTorqueToWheel 0;
BA_ "GenSigStartValue" SG_ 273 CurrentTorqueToWheel 16384;
BA_ "GenSigSendType" SG_ 273 CurrentTorqueToWheel 7;
BA_ "GenSigCycleTimeActive" SG_ 273 CurrentTorqueToWheel 10;
BA_ "GenSigCycleTime" SG_ 273 CurrentTorqueToWheel 10;
BA_ "GenSigTimeoutTime_HU_Mid_X451" SG_ 273 AccPedPosnVcuStatus 0;
BA_ "GenSigTimeoutTime_HU_High_X451" SG_ 273 AccPedPosnVcuStatus 0;
BA_ "GenSigTimeoutTime_HU_B" SG_ 273 AccPedPosnVcuStatus 0;
BA_ "GenSigTimeoutTime_HU_A" SG_ 273 AccPedPosnVcuStatus 0;
BA_ "GenSigTimeoutMsg_HU_Mid_X451" SG_ 273 AccPedPosnVcuStatus 0;
BA_ "GenSigTimeoutMsg_HU_High_X451" SG_ 273 AccPedPosnVcuStatus 0;
BA_ "GenSigTimeoutMsg_HU_B" SG_ 273 AccPedPosnVcuStatus 0;
BA_ "GenSigTimeoutMsg_HU_A" SG_ 273 AccPedPosnVcuStatus 0;
BA_ "GenSigSendType" SG_ 273 AccPedPosnVcuStatus 7;
BA_ "GenSigCycleTimeActive" SG_ 273 AccPedPosnVcuStatus 10;
BA_ "GenSigCycleTime" SG_ 273 AccPedPosnVcuStatus 10;
BA_ "GenSigTimeoutTime_HU_Mid_X451" SG_ 273 AccPedPosnVcu 0;
BA_ "GenSigTimeoutTime_HU_High_X451" SG_ 273 AccPedPosnVcu 0;
BA_ "GenSigTimeoutTime_HU_B" SG_ 273 AccPedPosnVcu 0;
BA_ "GenSigTimeoutTime_HU_A" SG_ 273 AccPedPosnVcu 0;
BA_ "GenSigTimeoutMsg_HU_Mid_X451" SG_ 273 AccPedPosnVcu 0;
BA_ "GenSigTimeoutMsg_HU_High_X451" SG_ 273 AccPedPosnVcu 0;
BA_ "GenSigTimeoutMsg_HU_B" SG_ 273 AccPedPosnVcu 0;
BA_ "GenSigTimeoutMsg_HU_A" SG_ 273 AccPedPosnVcu 0;
BA_ "GenSigSendType" SG_ 273 AccPedPosnVcu 7;
BA_ "GenSigCycleTimeActive" SG_ 273 AccPedPosnVcu 10;
BA_ "GenSigCycleTime" SG_ 273 AccPedPosnVcu 10;
BA_ "GenSigSendType" SG_ 192 LWS_ANGLE 7;
BA_ "GenSigCycleTimeActive" SG_ 192 LWS_ANGLE 10;
BA_ "GenSigCycleTime" SG_ 192 LWS_ANGLE 10;
BA_ "GenSigTimeoutTime_HU_B" SG_ 192 CHK_SUM 0;
BA_ "GenSigTimeoutTime_HU_A" SG_ 192 CHK_SUM 0;
BA_ "GenSigTimeoutMsg_HU_B" SG_ 192 CHK_SUM 0;
BA_ "GenSigTimeoutMsg_HU_A" SG_ 192 CHK_SUM 0;
BA_ "GenSigSendType" SG_ 192 CHK_SUM 7;
BA_ "GenSigCycleTimeActive" SG_ 192 CHK_SUM 10;
BA_ "GenSigCycleTime" SG_ 192 CHK_SUM 10;
BA_ "GenSigTimeoutTime_HU_B" SG_ 192 MSG_CNT 0;
BA_ "GenSigTimeoutTime_HU_A" SG_ 192 MSG_CNT 0;
BA_ "GenSigTimeoutMsg_HU_B" SG_ 192 MSG_CNT 0;
BA_ "GenSigTimeoutMsg_HU_A" SG_ 192 MSG_CNT 0;
BA_ "GenSigSendType" SG_ 192 MSG_CNT 7;
BA_ "GenSigCycleTimeActive" SG_ 192 MSG_CNT 10;
BA_ "GenSigCycleTime" SG_ 192 MSG_CNT 10;
BA_ "GenSigTimeoutTime_HU_B" SG_ 192 OK 0;
BA_ "GenSigTimeoutTime_HU_A" SG_ 192 OK 0;
BA_ "GenSigTimeoutMsg_HU_B" SG_ 192 OK 0;
BA_ "GenSigTimeoutMsg_HU_A" SG_ 192 OK 0;
BA_ "GenSigSendType" SG_ 192 OK 7;
BA_ "GenSigCycleTimeActive" SG_ 192 OK 10;
BA_ "GenSigCycleTime" SG_ 192 OK 10;
BA_ "GenSigTimeoutTime_HU_B" SG_ 192 CAL 0;
BA_ "GenSigTimeoutTime_HU_A" SG_ 192 CAL 0;
BA_ "GenSigTimeoutMsg_HU_B" SG_ 192 CAL 0;
BA_ "GenSigTimeoutMsg_HU_A" SG_ 192 CAL 0;
BA_ "GenSigSendType" SG_ 192 CAL 7;
BA_ "GenSigCycleTimeActive" SG_ 192 CAL 10;
BA_ "GenSigCycleTime" SG_ 192 CAL 10;
BA_ "GenSigSendType" SG_ 370 ABsActive 7;
BA_ "GenSigCycleTimeActive" SG_ 370 ABsActive 20;
BA_ "GenSigCycleTime" SG_ 370 ABsActive 20;
BA_ "GenSigTimeoutTime_HU_B" SG_ 370 TCsStatus 0;
BA_ "GenSigTimeoutTime_HU_A" SG_ 370 TCsStatus 0;
BA_ "GenSigTimeoutMsg_HU_B" SG_ 370 TCsStatus 0;
BA_ "GenSigTimeoutMsg_HU_A" SG_ 370 TCsStatus 0;
BA_ "GenSigSendType" SG_ 370 TCsStatus 7;
BA_ "GenSigCycleTimeActive" SG_ 370 TCsStatus 20;
BA_ "GenSigCycleTime" SG_ 370 TCsStatus 20;
BA_ "GenSigTimeoutTime_HU_B" SG_ 370 TCsActive 0;
BA_ "GenSigTimeoutTime_HU_A" SG_ 370 TCsActive 0;
BA_ "GenSigTimeoutMsg_HU_B" SG_ 370 TCsActive 0;
BA_ "GenSigTimeoutMsg_HU_A" SG_ 370 TCsActive 0;
BA_ "GenSigSendType" SG_ 370 TCsActive 7;
BA_ "GenSigCycleTimeActive" SG_ 370 TCsActive 20;
BA_ "GenSigCycleTime" SG_ 370 TCsActive 20;
BA_ "GenSigTimeoutTime_HU_B" SG_ 370 ESpStatus 0;
BA_ "GenSigTimeoutTime_HU_A" SG_ 370 ESpStatus 0;
BA_ "GenSigTimeoutMsg_HU_B" SG_ 370 ESpStatus 0;
BA_ "GenSigTimeoutMsg_HU_A" SG_ 370 ESpStatus 0;
BA_ "GenSigSendType" SG_ 370 ESpStatus 7;
BA_ "GenSigCycleTimeActive" SG_ 370 ESpStatus 20;
BA_ "GenSigCycleTime" SG_ 370 ESpStatus 20;
BA_ "GenSigTimeoutTime_HU_B" SG_ 370 ESpActive 0;
BA_ "GenSigTimeoutTime_HU_A" SG_ 370 ESpActive 0;
BA_ "GenSigTimeoutMsg_HU_B" SG_ 370 ESpActive 0;
BA_ "GenSigTimeoutMsg_HU_A" SG_ 370 ESpActive 0;
BA_ "GenSigSendType" SG_ 370 ESpActive 7;
BA_ "GenSigCycleTimeActive" SG_ 370 ESpActive 20;
BA_ "GenSigCycleTime" SG_ 370 ESpActive 20;
BA_ "GenSigTimeoutTime_HU_B" SG_ 370 NoGearshiftReq 0;
BA_ "GenSigTimeoutTime_HU_A" SG_ 370 NoGearshiftReq 0;
BA_ "GenSigTimeoutMsg_HU_B" SG_ 370 NoGearshiftReq 0;
BA_ "GenSigTimeoutMsg_HU_A" SG_ 370 NoGearshiftReq 0;
BA_ "GenSigSendType" SG_ 370 NoGearshiftReq 7;
BA_ "GenSigCycleTimeActive" SG_ 370 NoGearshiftReq 20;
BA_ "GenSigCycleTime" SG_ 370 NoGearshiftReq 20;
BA_ "GenSigSendType" SG_ 370 EBdStatus 7;
BA_ "GenSigCycleTimeActive" SG_ 370 EBdStatus 20;
BA_ "GenSigCycleTime" SG_ 370 EBdStatus 20;
BA_ "GenSigSendType" SG_ 370 EBdActive 7;
BA_ "GenSigCycleTimeActive" SG_ 370 EBdActive 20;
BA_ "GenSigCycleTime" SG_ 370 EBdActive 20;
BA_ "GenSigSendType" SG_ 370 ABsStatus 7;
BA_ "GenSigCycleTimeActive" SG_ 370 ABsStatus 20;
BA_ "GenSigCycleTime" SG_ 370 ABsStatus 20;
BA_ "GenSigTimeoutTime_HU_B" SG_ 370 HsaStatus 0;
BA_ "GenSigTimeoutTime_HU_A" SG_ 370 HsaStatus 0;
BA_ "GenSigTimeoutMsg_HU_B" SG_ 370 HsaStatus 0;
BA_ "GenSigTimeoutMsg_HU_A" SG_ 370 HsaStatus 0;
BA_ "GenSigSendType" SG_ 370 HsaStatus 7;
BA_ "GenSigCycleTimeActive" SG_ 370 HsaStatus 20;
BA_ "GenSigCycleTime" SG_ 370 HsaStatus 20;
BA_ "GenSigTimeoutTime_HU_B" SG_ 370 HsaActive 0;
BA_ "GenSigTimeoutTime_HU_A" SG_ 370 HsaActive 0;
BA_ "GenSigTimeoutMsg_HU_B" SG_ 370 HsaActive 0;
BA_ "GenSigTimeoutMsg_HU_A" SG_ 370 HsaActive 0;
BA_ "GenSigSendType" SG_ 370 HsaActive 7;
BA_ "GenSigCycleTimeActive" SG_ 370 HsaActive 20;
BA_ "GenSigCycleTime" SG_ 370 HsaActive 20;
BA_ "GenSigTimeoutTime_HU_B" SG_ 374 VehSpdABS 0;
BA_ "GenSigTimeoutTime_HU_A" SG_ 374 VehSpdABS 0;
BA_ "GenSigTimeoutMsg_HU_B" SG_ 374 VehSpdABS 0;
BA_ "GenSigTimeoutMsg_HU_A" SG_ 374 VehSpdABS 0;
BA_ "GenSigSendType" SG_ 374 VehSpdABS 7;
BA_ "GenSigCycleTimeActive" SG_ 374 VehSpdABS 20;
BA_ "GenSigCycleTime" SG_ 374 VehSpdABS 20;
BA_ "GenSigTimeoutTime_HU_B" SG_ 374 VehSpdABsStatus 0;
BA_ "GenSigTimeoutTime_HU_A" SG_ 374 VehSpdABsStatus 0;
BA_ "GenSigTimeoutMsg_HU_B" SG_ 374 VehSpdABsStatus 0;
BA_ "GenSigTimeoutMsg_HU_A" SG_ 374 VehSpdABsStatus 0;
BA_ "GenSigSendType" SG_ 374 VehSpdABsStatus 7;
BA_ "GenSigCycleTimeActive" SG_ 374 VehSpdABsStatus 20;
BA_ "GenSigCycleTime" SG_ 374 VehSpdABsStatus 20;
BA_ "GenSigTimeoutTime_HU_Mid_X451" SG_ 376 AX1 0;
BA_ "GenSigTimeoutTime_HU_High_X451" SG_ 376 AX1 0;
BA_ "GenSigTimeoutTime_HU_B" SG_ 376 AX1 0;
BA_ "GenSigTimeoutTime_HU_A" SG_ 376 AX1 0;
BA_ "GenSigTimeoutMsg_HU_Mid_X451" SG_ 376 AX1 0;
BA_ "GenSigTimeoutMsg_HU_High_X451" SG_ 376 AX1 0;
BA_ "GenSigTimeoutMsg_HU_B" SG_ 376 AX1 0;
BA_ "GenSigTimeoutMsg_HU_A" SG_ 376 AX1 0;
BA_ "GenSigStartValue" SG_ 376 AX1 32768;
BA_ "GenSigSendType" SG_ 376 AX1 7;
BA_ "GenSigCycleTimeActive" SG_ 376 AX1 20;
BA_ "GenSigCycleTime" SG_ 376 AX1 20;
BA_ "GenSigTimeoutTime_HU_Mid_X451" SG_ 376 AY1 0;
BA_ "GenSigTimeoutTime_HU_High_X451" SG_ 376 AY1 0;
BA_ "GenSigTimeoutTime_HU_B" SG_ 376 AY1 0;
BA_ "GenSigTimeoutTime_HU_A" SG_ 376 AY1 0;
BA_ "GenSigTimeoutMsg_HU_Mid_X451" SG_ 376 AY1 0;
BA_ "GenSigTimeoutMsg_HU_High_X451" SG_ 376 AY1 0;
BA_ "GenSigTimeoutMsg_HU_B" SG_ 376 AY1 0;
BA_ "GenSigTimeoutMsg_HU_A" SG_ 376 AY1 0;
BA_ "GenSigStartValue" SG_ 376 AY1 32768;
BA_ "GenSigSendType" SG_ 376 AY1 7;
BA_ "GenSigCycleTimeActive" SG_ 376 AY1 20;
BA_ "GenSigCycleTime" SG_ 376 AY1 20;
BA_ "GenSigTimeoutTime_HU_Mid_X451" SG_ 376 MasterCylinderPres 0;
BA_ "GenSigTimeoutTime_HU_High_X451" SG_ 376 MasterCylinderPres 0;
BA_ "GenSigTimeoutTime_HU_B" SG_ 376 MasterCylinderPres 0;
BA_ "GenSigTimeoutTime_HU_A" SG_ 376 MasterCylinderPres 0;
BA_ "GenSigTimeoutMsg_HU_Mid_X451" SG_ 376 MasterCylinderPres 0;
BA_ "GenSigTimeoutMsg_HU_High_X451" SG_ 376 MasterCylinderPres 0;
BA_ "GenSigTimeoutMsg_HU_B" SG_ 376 MasterCylinderPres 0;
BA_ "GenSigTimeoutMsg_HU_A" SG_ 376 MasterCylinderPres 0;
BA_ "GenSigStartValue" SG_ 376 MasterCylinderPres 800;
BA_ "GenSigSendType" SG_ 376 MasterCylinderPres 7;
BA_ "GenSigCycleTimeActive" SG_ 376 MasterCylinderPres 20;
BA_ "GenSigCycleTime" SG_ 376 MasterCylinderPres 20;
BA_ "GenSigTimeoutTime_HU_Mid_X451" SG_ 376 MasterCylinderPresStatus 0;
BA_ "GenSigTimeoutTime_HU_High_X451" SG_ 376 MasterCylinderPresStatus 0;
BA_ "GenSigTimeoutTime_HU_B" SG_ 376 MasterCylinderPresStatus 0;
BA_ "GenSigTimeoutTime_HU_A" SG_ 376 MasterCylinderPresStatus 0;
BA_ "GenSigTimeoutMsg_HU_Mid_X451" SG_ 376 MasterCylinderPresStatus 0;
BA_ "GenSigTimeoutMsg_HU_High_X451" SG_ 376 MasterCylinderPresStatus 0;
BA_ "GenSigTimeoutMsg_HU_B" SG_ 376 MasterCylinderPresStatus 0;
BA_ "GenSigTimeoutMsg_HU_A" SG_ 376 MasterCylinderPresStatus 0;
BA_ "GenSigSendType" SG_ 376 MasterCylinderPresStatus 7;
BA_ "GenSigCycleTimeActive" SG_ 376 MasterCylinderPresStatus 20;
BA_ "GenSigCycleTime" SG_ 376 MasterCylinderPresStatus 20;
BA_ "GenSigSendType" SG_ 656 WSsPulseCountRearRH 7;
BA_ "GenSigCycleTimeActive" SG_ 656 WSsPulseCountRearRH 100;
BA_ "GenSigCycleTime" SG_ 656 WSsPulseCountRearRH 100;
BA_ "GenSigSendType" SG_ 656 WSsPulseCountRearLH 7;
BA_ "GenSigCycleTimeActive" SG_ 656 WSsPulseCountRearLH 100;
BA_ "GenSigCycleTime" SG_ 656 WSsPulseCountRearLH 100;
BA_ "GenSigSendType" SG_ 656 WSsPulseCountFrontRH 7;
BA_ "GenSigCycleTimeActive" SG_ 656 WSsPulseCountFrontRH 100;
BA_ "GenSigCycleTime" SG_ 656 WSsPulseCountFrontRH 100;
BA_ "GenSigSendType" SG_ 656 WSsPulseCountFrontLH 7;
BA_ "GenSigCycleTimeActive" SG_ 656 WSsPulseCountFrontLH 100;
BA_ "GenSigCycleTime" SG_ 656 WSsPulseCountFrontLH 100;
BA_ "GenSigSendType" SG_ 656 WSsPulseCountFrontRHStatus 7;
BA_ "GenSigCycleTimeActive" SG_ 656 WSsPulseCountFrontRHStatus 100;
BA_ "GenSigCycleTime" SG_ 656 WSsPulseCountFrontRHStatus 100;
BA_ "GenSigSendType" SG_ 656 WSsPulseCountRearLHStatus 7;
BA_ "GenSigCycleTimeActive" SG_ 656 WSsPulseCountRearLHStatus 100;
BA_ "GenSigCycleTime" SG_ 656 WSsPulseCountRearLHStatus 100;
BA_ "GenSigSendType" SG_ 656 WSsPulseCountRearRHStatus 7;
BA_ "GenSigCycleTimeActive" SG_ 656 WSsPulseCountRearRHStatus 100;
BA_ "GenSigCycleTime" SG_ 656 WSsPulseCountRearRHStatus 100;
BA_ "GenSigSendType" SG_ 656 WSsPulseCountFrontLHStatus 7;
BA_ "GenSigCycleTimeActive" SG_ 656 WSsPulseCountFrontLHStatus 100;
BA_ "GenSigCycleTime" SG_ 656 WSsPulseCountFrontLHStatus 100;
BA_ "GenSigSendType" SG_ 656 DrvModeIndctnESPStatusNew 7;
BA_ "GenSigCycleTimeActive" SG_ 656 DrvModeIndctnESPStatusNew 100;
BA_ "GenSigCycleTime" SG_ 656 DrvModeIndctnESPStatusNew 100;
BA_ "GenSigSendType" SG_ 656 DrvModeIndctnESPNew 7;
BA_ "GenSigCycleTimeActive" SG_ 656 DrvModeIndctnESPNew 100;
BA_ "GenSigCycleTime" SG_ 656 DrvModeIndctnESPNew 100;
BA_ "GenSigTimeoutTime_HU_B" SG_ 660 WhlSpdFrLeft 0;
BA_ "GenSigTimeoutTime_HU_A" SG_ 660 WhlSpdFrLeft 0;
BA_ "GenSigTimeoutMsg_HU_B" SG_ 660 WhlSpdFrLeft 0;
BA_ "GenSigTimeoutMsg_HU_A" SG_ 660 WhlSpdFrLeft 0;
BA_ "GenSigSendType" SG_ 660 WhlSpdFrLeft 7;
BA_ "GenSigCycleTimeActive" SG_ 660 WhlSpdFrLeft 100;
BA_ "GenSigCycleTime" SG_ 660 WhlSpdFrLeft 100;
BA_ "GenSigTimeoutTime_HU_B" SG_ 660 WhlSpdFrRight 0;
BA_ "GenSigTimeoutTime_HU_A" SG_ 660 WhlSpdFrRight 0;
BA_ "GenSigTimeoutMsg_HU_B" SG_ 660 WhlSpdFrRight 0;
BA_ "GenSigTimeoutMsg_HU_A" SG_ 660 WhlSpdFrRight 0;
BA_ "GenSigSendType" SG_ 660 WhlSpdFrRight 7;
BA_ "GenSigCycleTimeActive" SG_ 660 WhlSpdFrRight 100;
BA_ "GenSigCycleTime" SG_ 660 WhlSpdFrRight 100;
BA_ "GenSigTimeoutTime_HU_B" SG_ 660 WhlSpdFrLeftStatus 0;
BA_ "GenSigTimeoutTime_HU_A" SG_ 660 WhlSpdFrLeftStatus 0;
BA_ "GenSigTimeoutMsg_HU_B" SG_ 660 WhlSpdFrLeftStatus 0;
BA_ "GenSigTimeoutMsg_HU_A" SG_ 660 WhlSpdFrLeftStatus 0;
BA_ "GenSigSendType" SG_ 660 WhlSpdFrLeftStatus 7;
BA_ "GenSigCycleTimeActive" SG_ 660 WhlSpdFrLeftStatus 100;
BA_ "GenSigCycleTime" SG_ 660 WhlSpdFrLeftStatus 100;
BA_ "GenSigTimeoutTime_HU_B" SG_ 660 WhlSpdRrLeft 0;
BA_ "GenSigTimeoutTime_HU_A" SG_ 660 WhlSpdRrLeft 0;
BA_ "GenSigTimeoutMsg_HU_B" SG_ 660 WhlSpdRrLeft 0;
BA_ "GenSigTimeoutMsg_HU_A" SG_ 660 WhlSpdRrLeft 0;
BA_ "GenSigSendType" SG_ 660 WhlSpdRrLeft 7;
BA_ "GenSigCycleTimeActive" SG_ 660 WhlSpdRrLeft 100;
BA_ "GenSigCycleTime" SG_ 660 WhlSpdRrLeft 100;
BA_ "GenSigTimeoutTime_HU_B" SG_ 660 WhlSpdFrRightStatus 0;
BA_ "GenSigTimeoutTime_HU_A" SG_ 660 WhlSpdFrRightStatus 0;
BA_ "GenSigTimeoutMsg_HU_B" SG_ 660 WhlSpdFrRightStatus 0;
BA_ "GenSigTimeoutMsg_HU_A" SG_ 660 WhlSpdFrRightStatus 0;
BA_ "GenSigSendType" SG_ 660 WhlSpdFrRightStatus 7;
BA_ "GenSigCycleTimeActive" SG_ 660 WhlSpdFrRightStatus 100;
BA_ "GenSigCycleTime" SG_ 660 WhlSpdFrRightStatus 100;
BA_ "GenSigTimeoutTime_HU_B" SG_ 660 WhlSpdRrRight 0;
BA_ "GenSigTimeoutTime_HU_A" SG_ 660 WhlSpdRrRight 0;
BA_ "GenSigTimeoutMsg_HU_B" SG_ 660 WhlSpdRrRight 0;
BA_ "GenSigTimeoutMsg_HU_A" SG_ 660 WhlSpdRrRight 0;
BA_ "GenSigSendType" SG_ 660 WhlSpdRrRight 7;
BA_ "GenSigCycleTimeActive" SG_ 660 WhlSpdRrRight 100;
BA_ "GenSigCycleTime" SG_ 660 WhlSpdRrRight 100;
BA_ "GenSigTimeoutTime_HU_B" SG_ 660 WhlSpdRrLeftStatus 0;
BA_ "GenSigTimeoutTime_HU_A" SG_ 660 WhlSpdRrLeftStatus 0;
BA_ "GenSigTimeoutMsg_HU_B" SG_ 660 WhlSpdRrLeftStatus 0;
BA_ "GenSigTimeoutMsg_HU_A" SG_ 660 WhlSpdRrLeftStatus 0;
BA_ "GenSigSendType" SG_ 660 WhlSpdRrLeftStatus 7;
BA_ "GenSigCycleTimeActive" SG_ 660 WhlSpdRrLeftStatus 100;
BA_ "GenSigCycleTime" SG_ 660 WhlSpdRrLeftStatus 100;
BA_ "GenSigTimeoutTime_HU_B" SG_ 660 WhlSpdAliveCounter 0;
BA_ "GenSigTimeoutTime_HU_A" SG_ 660 WhlSpdAliveCounter 0;
BA_ "GenSigTimeoutMsg_HU_B" SG_ 660 WhlSpdAliveCounter 0;
BA_ "GenSigTimeoutMsg_HU_A" SG_ 660 WhlSpdAliveCounter 0;
BA_ "GenSigSendType" SG_ 660 WhlSpdAliveCounter 7;
BA_ "GenSigCycleTimeActive" SG_ 660 WhlSpdAliveCounter 100;
BA_ "GenSigCycleTime" SG_ 660 WhlSpdAliveCounter 100;
BA_ "GenSigTimeoutTime_HU_B" SG_ 660 WhlSpdRrRightStatus 0;
BA_ "GenSigTimeoutTime_HU_A" SG_ 660 WhlSpdRrRightStatus 0;
BA_ "GenSigTimeoutMsg_HU_B" SG_ 660 WhlSpdRrRightStatus 0;
BA_ "GenSigTimeoutMsg_HU_A" SG_ 660 WhlSpdRrRightStatus 0;
BA_ "GenSigSendType" SG_ 660 WhlSpdRrRightStatus 7;
BA_ "GenSigCycleTimeActive" SG_ 660 WhlSpdRrRightStatus 100;
BA_ "GenSigCycleTime" SG_ 660 WhlSpdRrRightStatus 100;
BA_ "GenSigTimeoutTime_HU_B" SG_ 660 WhlSpdCRC 0;
BA_ "GenSigTimeoutTime_HU_A" SG_ 660 WhlSpdCRC 0;
BA_ "GenSigTimeoutMsg_HU_B" SG_ 660 WhlSpdCRC 0;
BA_ "GenSigTimeoutMsg_HU_A" SG_ 660 WhlSpdCRC 0;
BA_ "GenSigSendType" SG_ 660 WhlSpdCRC 7;
BA_ "GenSigCycleTimeActive" SG_ 660 WhlSpdCRC 100;
BA_ "GenSigCycleTime" SG_ 660 WhlSpdCRC 100;
BA_ "GenSigSendType" SG_ 693 AVhEnableRequest 3;
BA_ "GenSigCycleTimeActive" SG_ 693 AVhEnableRequest 10;
BA_ "GenSigCycleTime" SG_ 693 AVhEnableRequest 1000;
BA_ "GenSigSendType" SG_ 693 IPC2_CRC 3;
BA_ "GenSigCycleTimeActive" SG_ 693 IPC2_CRC 10;
BA_ "GenSigCycleTime" SG_ 693 IPC2_CRC 1000;
BA_ "GenSigSendType" SG_ 693 IPC2_CNT 3;
BA_ "GenSigCycleTimeActive" SG_ 693 IPC2_CNT 10;
BA_ "GenSigCycleTime" SG_ 693 IPC2_CNT 1000;
BA_ "GenSigSendType" SG_ 693 EpbSwitchRequest 3;
BA_ "GenSigCycleTimeActive" SG_ 693 EpbSwitchRequest 10;
BA_ "GenSigCycleTime" SG_ 693 EpbSwitchRequest 1000;
BA_ "GenSigStartValue" SG_ 693 OATICSig 80;
BA_ "GenSigSendType" SG_ 693 OATICSig 3;
BA_ "GenSigCycleTimeActive" SG_ 693 OATICSig 10;
BA_ "GenSigCycleTime" SG_ 693 OATICSig 1000;
BA_ "GenSigStartValue" SG_ 693 OATICSigStatus 2;
BA_ "GenSigSendType" SG_ 693 OATICSigStatus 3;
BA_ "GenSigCycleTimeActive" SG_ 693 OATICSigStatus 10;
BA_ "GenSigCycleTime" SG_ 693 OATICSigStatus 1000;
BA_ "GenSigStartValue" SG_ 722 PowerModeState 1;
BA_ "GenSigSendType" SG_ 722 PowerModeState 7;
BA_ "GenSigCycleTimeActive" SG_ 722 PowerModeState 100;
BA_ "GenSigCycleTime" SG_ 722 PowerModeState 100;
BA_ "GenSigTimeoutTime_HU_B" SG_ 946 WiperHighLowIntermtStateStatus 0;
BA_ "GenSigTimeoutTime_HU_A" SG_ 946 WiperHighLowIntermtStateStatus 0;
BA_ "GenSigTimeoutMsg_HU_B" SG_ 946 WiperHighLowIntermtStateStatus 0;
BA_ "GenSigTimeoutMsg_HU_A" SG_ 946 WiperHighLowIntermtStateStatus 0;
BA_ "GenSigSendType" SG_ 946 WiperHighLowIntermtStateStatus 7;
BA_ "GenSigCycleTimeActive" SG_ 946 WiperHighLowIntermtStateStatus 500;
BA_ "GenSigCycleTime" SG_ 946 WiperHighLowIntermtStateStatus 500;
BA_ "GenSigTimeoutTime_HU_B" SG_ 946 WiperHighLowIntermtState 0;
BA_ "GenSigTimeoutTime_HU_A" SG_ 946 WiperHighLowIntermtState 0;
BA_ "GenSigTimeoutMsg_HU_B" SG_ 946 WiperHighLowIntermtState 0;
BA_ "GenSigTimeoutMsg_HU_A" SG_ 946 WiperHighLowIntermtState 0;
BA_ "GenSigSendType" SG_ 946 WiperHighLowIntermtState 7;
BA_ "GenSigCycleTimeActive" SG_ 946 WiperHighLowIntermtState 500;
BA_ "GenSigCycleTime" SG_ 946 WiperHighLowIntermtState 500;
BA_ "GenSigTimeoutTime_HU_Mid_X451" SG_ 1274 GlobalRealTimeGS 5000;
BA_ "GenSigTimeoutTime_HU_High_X451" SG_ 1274 GlobalRealTimeGS 5000;
BA_ "GenSigTimeoutTime_HU_B" SG_ 1274 GlobalRealTimeGS 5000;
BA_ "GenSigTimeoutTime_HU_A" SG_ 1274 GlobalRealTimeGS 5000;
BA_ "GenSigTimeoutMsg_HU_Mid_X451" SG_ 1274 GlobalRealTimeGS 5000;
BA_ "GenSigTimeoutMsg_HU_High_X451" SG_ 1274 GlobalRealTimeGS 5000;
BA_ "GenSigTimeoutMsg_HU_B" SG_ 1274 GlobalRealTimeGS 5000;
BA_ "GenSigTimeoutMsg_HU_A" SG_ 1274 GlobalRealTimeGS 5000;
BA_ "GenSigSendType" SG_ 1274 GlobalRealTimeGS 7;
BA_ "GenSigCycleTimeActive" SG_ 1274 GlobalRealTimeGS 1000;
BA_ "GenSigCycleTime" SG_ 1274 GlobalRealTimeGS 1000;
BA_ "GenSigTimeoutMsg_HU_High_X445" SG_ 1274 GlobalRealTimeGS 5000;
BA_ "GenSigTimeoutMsg_HU_Mid_X445" SG_ 1274 GlobalRealTimeGS 5000;
BA_ "GenSigTimeoutTime_HU_High_X445" SG_ 1274 GlobalRealTimeGS 5000;
BA_ "GenSigTimeoutTime_HU_Mid_X445" SG_ 1274 GlobalRealTimeGS 5000;
BA_ "GenSigTimeoutTime_HU_Mid_X451" SG_ 1274 OdoICFullSigGS 5000;
BA_ "GenSigTimeoutTime_HU_High_X451" SG_ 1274 OdoICFullSigGS 5000;
BA_ "GenSigTimeoutTime_HU_B" SG_ 1274 OdoICFullSigGS 5000;
BA_ "GenSigTimeoutTime_HU_A" SG_ 1274 OdoICFullSigGS 5000;
BA_ "GenSigTimeoutMsg_HU_Mid_X451" SG_ 1274 OdoICFullSigGS 5000;
BA_ "GenSigTimeoutMsg_HU_High_X451" SG_ 1274 OdoICFullSigGS 5000;
BA_ "GenSigTimeoutMsg_HU_B" SG_ 1274 OdoICFullSigGS 5000;
BA_ "GenSigTimeoutMsg_HU_A" SG_ 1274 OdoICFullSigGS 5000;
BA_ "GenSigSendType" SG_ 1274 OdoICFullSigGS 7;
BA_ "GenSigCycleTimeActive" SG_ 1274 OdoICFullSigGS 1000;
BA_ "GenSigCycleTime" SG_ 1274 OdoICFullSigGS 1000;
BA_ "GenSigTimeoutMsg_HU_High_X445" SG_ 1274 OdoICFullSigGS 5000;
BA_ "GenSigTimeoutMsg_HU_Mid_X445" SG_ 1274 OdoICFullSigGS 5000;
BA_ "GenSigTimeoutTime_HU_High_X445" SG_ 1274 OdoICFullSigGS 5000;
BA_ "GenSigTimeoutTime_HU_Mid_X445" SG_ 1274 OdoICFullSigGS 5000;
BA_ "GenSigTimeoutTime_HU_Mid_X451" SG_ 1274 BatVoltGS 5000;
BA_ "GenSigTimeoutTime_HU_High_X451" SG_ 1274 BatVoltGS 5000;
BA_ "GenSigTimeoutTime_HU_B" SG_ 1274 BatVoltGS 5000;
BA_ "GenSigTimeoutTime_HU_A" SG_ 1274 BatVoltGS 5000;
BA_ "GenSigTimeoutMsg_HU_Mid_X451" SG_ 1274 BatVoltGS 5000;
BA_ "GenSigTimeoutMsg_HU_High_X451" SG_ 1274 BatVoltGS 5000;
BA_ "GenSigTimeoutMsg_HU_B" SG_ 1274 BatVoltGS 5000;
BA_ "GenSigTimeoutMsg_HU_A" SG_ 1274 BatVoltGS 5000;
BA_ "GenSigSendType" SG_ 1274 BatVoltGS 7;
BA_ "GenSigCycleTimeActive" SG_ 1274 BatVoltGS 1000;
BA_ "GenSigCycleTime" SG_ 1274 BatVoltGS 1000;
BA_ "GenSigTimeoutMsg_HU_High_X445" SG_ 1274 BatVoltGS 5000;
BA_ "GenSigTimeoutMsg_HU_Mid_X445" SG_ 1274 BatVoltGS 5000;
BA_ "GenSigTimeoutTime_HU_High_X445" SG_ 1274 BatVoltGS 5000;
BA_ "GenSigTimeoutTime_HU_Mid_X445" SG_ 1274 BatVoltGS 5000;
BA_ "GenSigTimeoutTime_HU_Mid_X451" SG_ 1274 VehicleInteriorTempGS 5000;
BA_ "GenSigTimeoutTime_HU_High_X451" SG_ 1274 VehicleInteriorTempGS 5000;
BA_ "GenSigTimeoutTime_HU_B" SG_ 1274 VehicleInteriorTempGS 5000;
BA_ "GenSigTimeoutTime_HU_A" SG_ 1274 VehicleInteriorTempGS 5000;
BA_ "GenSigTimeoutMsg_HU_Mid_X451" SG_ 1274 VehicleInteriorTempGS 5000;
BA_ "GenSigTimeoutMsg_HU_High_X451" SG_ 1274 VehicleInteriorTempGS 5000;
BA_ "GenSigTimeoutMsg_HU_B" SG_ 1274 VehicleInteriorTempGS 5000;
BA_ "GenSigTimeoutMsg_HU_A" SG_ 1274 VehicleInteriorTempGS 5000;
BA_ "GenSigStartValue" SG_ 1274 VehicleInteriorTempGS 40;
BA_ "GenSigSendType" SG_ 1274 VehicleInteriorTempGS 7;
BA_ "GenSigCycleTimeActive" SG_ 1274 VehicleInteriorTempGS 1000;
BA_ "GenSigCycleTime" SG_ 1274 VehicleInteriorTempGS 1000;
BA_ "GenSigTimeoutMsg_HU_High_X445" SG_ 1274 VehicleInteriorTempGS 5000;
BA_ "GenSigTimeoutMsg_HU_Mid_X445" SG_ 1274 VehicleInteriorTempGS 5000;
BA_ "GenSigTimeoutTime_HU_High_X445" SG_ 1274 VehicleInteriorTempGS 5000;
BA_ "GenSigTimeoutTime_HU_Mid_X445" SG_ 1274 VehicleInteriorTempGS 5000;
BA_ "GenSigTimeoutTime_HU_Mid_X451" SG_ 1280 BCM_NMPDU_SRC_ECU_ID 1000;
BA_ "GenSigTimeoutTime_HU_High_X451" SG_ 1280 BCM_NMPDU_SRC_ECU_ID 1000;
BA_ "GenSigTimeoutTime_HU_B" SG_ 1280 BCM_NMPDU_SRC_ECU_ID 1000;
BA_ "GenSigTimeoutTime_HU_A" SG_ 1280 BCM_NMPDU_SRC_ECU_ID 1000;
BA_ "GenSigTimeoutMsg_HU_Mid_X451" SG_ 1280 BCM_NMPDU_SRC_ECU_ID 1000;
BA_ "GenSigTimeoutMsg_HU_High_X451" SG_ 1280 BCM_NMPDU_SRC_ECU_ID 1000;
BA_ "GenSigTimeoutMsg_HU_B" SG_ 1280 BCM_NMPDU_SRC_ECU_ID 1000;
BA_ "GenSigTimeoutMsg_HU_A" SG_ 1280 BCM_NMPDU_SRC_ECU_ID 1000;
BA_ "GenSigSendType" SG_ 1280 BCM_NMPDU_SRC_ECU_ID 7;
BA_ "GenSigCycleTimeActive" SG_ 1280 BCM_NMPDU_SRC_ECU_ID 200;
BA_ "GenSigCycleTime" SG_ 1280 BCM_NMPDU_SRC_ECU_ID 200;
BA_ "GenSigTimeoutMsg_HU_High_X445" SG_ 1280 BCM_NMPDU_SRC_ECU_ID 1000;
BA_ "GenSigTimeoutMsg_HU_Mid_X445" SG_ 1280 BCM_NMPDU_SRC_ECU_ID 1000;
BA_ "GenSigTimeoutTime_HU_High_X445" SG_ 1280 BCM_NMPDU_SRC_ECU_ID 1000;
BA_ "GenSigTimeoutTime_HU_Mid_X445" SG_ 1280 BCM_NMPDU_SRC_ECU_ID 1000;
BA_ "GenSigTimeoutTime_HU_Mid_X451" SG_ 1280 RepeatMessageReq_BCM 1000;
BA_ "GenSigTimeoutTime_HU_High_X451" SG_ 1280 RepeatMessageReq_BCM 1000;
BA_ "GenSigTimeoutTime_HU_B" SG_ 1280 RepeatMessageReq_BCM 1000;
BA_ "GenSigTimeoutTime_HU_A" SG_ 1280 RepeatMessageReq_BCM 1000;
BA_ "GenSigTimeoutMsg_HU_Mid_X451" SG_ 1280 RepeatMessageReq_BCM 1000;
BA_ "GenSigTimeoutMsg_HU_High_X451" SG_ 1280 RepeatMessageReq_BCM 1000;
BA_ "GenSigTimeoutMsg_HU_B" SG_ 1280 RepeatMessageReq_BCM 1000;
BA_ "GenSigTimeoutMsg_HU_A" SG_ 1280 RepeatMessageReq_BCM 1000;
BA_ "GenSigSendType" SG_ 1280 RepeatMessageReq_BCM 7;
BA_ "GenSigCycleTimeActive" SG_ 1280 RepeatMessageReq_BCM 200;
BA_ "GenSigCycleTime" SG_ 1280 RepeatMessageReq_BCM 200;
BA_ "GenSigTimeoutMsg_HU_High_X445" SG_ 1280 RepeatMessageReq_BCM 1000;
BA_ "GenSigTimeoutMsg_HU_Mid_X445" SG_ 1280 RepeatMessageReq_BCM 1000;
BA_ "GenSigTimeoutTime_HU_High_X445" SG_ 1280 RepeatMessageReq_BCM 1000;
BA_ "GenSigTimeoutTime_HU_Mid_X445" SG_ 1280 RepeatMessageReq_BCM 1000;
BA_ "GenSigTimeoutTime_HU_Mid_X451" SG_ 1280 Reserved0 1000;
BA_ "GenSigTimeoutTime_HU_High_X451" SG_ 1280 Reserved0 1000;
BA_ "GenSigTimeoutTime_HU_B" SG_ 1280 Reserved0 1000;
BA_ "GenSigTimeoutTime_HU_A" SG_ 1280 Reserved0 1000;
BA_ "GenSigTimeoutMsg_HU_Mid_X451" SG_ 1280 Reserved0 1000;
BA_ "GenSigTimeoutMsg_HU_High_X451" SG_ 1280 Reserved0 1000;
BA_ "GenSigTimeoutMsg_HU_B" SG_ 1280 Reserved0 1000;
BA_ "GenSigTimeoutMsg_HU_A" SG_ 1280 Reserved0 1000;
BA_ "GenSigSendType" SG_ 1280 Reserved0 7;
BA_ "GenSigCycleTimeActive" SG_ 1280 Reserved0 200;
BA_ "GenSigCycleTime" SG_ 1280 Reserved0 200;
BA_ "GenSigTimeoutMsg_HU_High_X445" SG_ 1280 Reserved0 1000;
BA_ "GenSigTimeoutMsg_HU_Mid_X445" SG_ 1280 Reserved0 1000;
BA_ "GenSigTimeoutTime_HU_High_X445" SG_ 1280 Reserved0 1000;
BA_ "GenSigTimeoutTime_HU_Mid_X445" SG_ 1280 Reserved0 1000;
BA_ "GenSigTimeoutTime_HU_Mid_X451" SG_ 1280 Reserved1 1000;
BA_ "GenSigTimeoutTime_HU_High_X451" SG_ 1280 Reserved1 1000;
BA_ "GenSigTimeoutTime_HU_B" SG_ 1280 Reserved1 1000;
BA_ "GenSigTimeoutTime_HU_A" SG_ 1280 Reserved1 1000;
BA_ "GenSigTimeoutMsg_HU_Mid_X451" SG_ 1280 Reserved1 1000;
BA_ "GenSigTimeoutMsg_HU_High_X451" SG_ 1280 Reserved1 1000;
BA_ "GenSigTimeoutMsg_HU_B" SG_ 1280 Reserved1 1000;
BA_ "GenSigTimeoutMsg_HU_A" SG_ 1280 Reserved1 1000;
BA_ "GenSigSendType" SG_ 1280 Reserved1 7;
BA_ "GenSigCycleTimeActive" SG_ 1280 Reserved1 200;
BA_ "GenSigCycleTime" SG_ 1280 Reserved1 200;
BA_ "GenSigTimeoutMsg_HU_High_X445" SG_ 1280 Reserved1 1000;
BA_ "GenSigTimeoutMsg_HU_Mid_X445" SG_ 1280 Reserved1 1000;
BA_ "GenSigTimeoutTime_HU_High_X445" SG_ 1280 Reserved1 1000;
BA_ "GenSigTimeoutTime_HU_Mid_X445" SG_ 1280 Reserved1 1000;
BA_ "GenSigTimeoutTime_HU_Mid_X451" SG_ 1280 NMCoOrdSlpReady_BCM 1000;
BA_ "GenSigTimeoutTime_HU_High_X451" SG_ 1280 NMCoOrdSlpReady_BCM 1000;
BA_ "GenSigTimeoutTime_HU_B" SG_ 1280 NMCoOrdSlpReady_BCM 1000;
BA_ "GenSigTimeoutTime_HU_A" SG_ 1280 NMCoOrdSlpReady_BCM 1000;
BA_ "GenSigTimeoutMsg_HU_Mid_X451" SG_ 1280 NMCoOrdSlpReady_BCM 1000;
BA_ "GenSigTimeoutMsg_HU_High_X451" SG_ 1280 NMCoOrdSlpReady_BCM 1000;
BA_ "GenSigTimeoutMsg_HU_B" SG_ 1280 NMCoOrdSlpReady_BCM 1000;
BA_ "GenSigTimeoutMsg_HU_A" SG_ 1280 NMCoOrdSlpReady_BCM 1000;
BA_ "GenSigSendType" SG_ 1280 NMCoOrdSlpReady_BCM 7;
BA_ "GenSigCycleTimeActive" SG_ 1280 NMCoOrdSlpReady_BCM 200;
BA_ "GenSigCycleTime" SG_ 1280 NMCoOrdSlpReady_BCM 200;
BA_ "GenSigTimeoutMsg_HU_High_X445" SG_ 1280 NMCoOrdSlpReady_BCM 1000;
BA_ "GenSigTimeoutMsg_HU_Mid_X445" SG_ 1280 NMCoOrdSlpReady_BCM 1000;
BA_ "GenSigTimeoutTime_HU_High_X445" SG_ 1280 NMCoOrdSlpReady_BCM 1000;
BA_ "GenSigTimeoutTime_HU_Mid_X445" SG_ 1280 NMCoOrdSlpReady_BCM 1000;
BA_ "GenSigTimeoutTime_HU_Mid_X451" SG_ 1280 ActiveWakeUp_BCM 1000;
BA_ "GenSigTimeoutTime_HU_High_X451" SG_ 1280 ActiveWakeUp_BCM 1000;
BA_ "GenSigTimeoutTime_HU_B" SG_ 1280 ActiveWakeUp_BCM 1000;
BA_ "GenSigTimeoutTime_HU_A" SG_ 1280 ActiveWakeUp_BCM 1000;
BA_ "GenSigTimeoutMsg_HU_Mid_X451" SG_ 1280 ActiveWakeUp_BCM 1000;
BA_ "GenSigTimeoutMsg_HU_High_X451" SG_ 1280 ActiveWakeUp_BCM 1000;
BA_ "GenSigTimeoutMsg_HU_B" SG_ 1280 ActiveWakeUp_BCM 1000;
BA_ "GenSigTimeoutMsg_HU_A" SG_ 1280 ActiveWakeUp_BCM 1000;
BA_ "GenSigSendType" SG_ 1280 ActiveWakeUp_BCM 7;
BA_ "GenSigCycleTimeActive" SG_ 1280 ActiveWakeUp_BCM 200;
BA_ "GenSigCycleTime" SG_ 1280 ActiveWakeUp_BCM 200;
BA_ "GenSigTimeoutMsg_HU_High_X445" SG_ 1280 ActiveWakeUp_BCM 1000;
BA_ "GenSigTimeoutMsg_HU_Mid_X445" SG_ 1280 ActiveWakeUp_BCM 1000;
BA_ "GenSigTimeoutTime_HU_High_X445" SG_ 1280 ActiveWakeUp_BCM 1000;
BA_ "GenSigTimeoutTime_HU_Mid_X445" SG_ 1280 ActiveWakeUp_BCM 1000;
BA_ "GenSigTimeoutTime_HU_Mid_X451" SG_ 1280 Reserved2 1000;
BA_ "GenSigTimeoutTime_HU_High_X451" SG_ 1280 Reserved2 1000;
BA_ "GenSigTimeoutTime_HU_B" SG_ 1280 Reserved2 1000;
BA_ "GenSigTimeoutTime_HU_A" SG_ 1280 Reserved2 1000;
BA_ "GenSigTimeoutMsg_HU_Mid_X451" SG_ 1280 Reserved2 1000;
BA_ "GenSigTimeoutMsg_HU_High_X451" SG_ 1280 Reserved2 1000;
BA_ "GenSigTimeoutMsg_HU_B" SG_ 1280 Reserved2 1000;
BA_ "GenSigTimeoutMsg_HU_A" SG_ 1280 Reserved2 1000;
BA_ "GenSigSendType" SG_ 1280 Reserved2 7;
BA_ "GenSigCycleTimeActive" SG_ 1280 Reserved2 200;
BA_ "GenSigCycleTime" SG_ 1280 Reserved2 200;
BA_ "GenSigTimeoutMsg_HU_High_X445" SG_ 1280 Reserved2 1000;
BA_ "GenSigTimeoutMsg_HU_Mid_X445" SG_ 1280 Reserved2 1000;
BA_ "GenSigTimeoutTime_HU_High_X445" SG_ 1280 Reserved2 1000;
BA_ "GenSigTimeoutTime_HU_Mid_X445" SG_ 1280 Reserved2 1000;
BA_ "GenSigTimeoutTime_HU_Mid_X451" SG_ 1280 PartialNetworkInformation_BCM 1000;
BA_ "GenSigTimeoutTime_HU_High_X451" SG_ 1280 PartialNetworkInformation_BCM 1000;
BA_ "GenSigTimeoutTime_HU_B" SG_ 1280 PartialNetworkInformation_BCM 1000;
BA_ "GenSigTimeoutTime_HU_A" SG_ 1280 PartialNetworkInformation_BCM 1000;
BA_ "GenSigTimeoutMsg_HU_Mid_X451" SG_ 1280 PartialNetworkInformation_BCM 1000;
BA_ "GenSigTimeoutMsg_HU_High_X451" SG_ 1280 PartialNetworkInformation_BCM 1000;
BA_ "GenSigTimeoutMsg_HU_B" SG_ 1280 PartialNetworkInformation_BCM 1000;
BA_ "GenSigTimeoutMsg_HU_A" SG_ 1280 PartialNetworkInformation_BCM 1000;
BA_ "GenSigSendType" SG_ 1280 PartialNetworkInformation_BCM 7;
BA_ "GenSigCycleTimeActive" SG_ 1280 PartialNetworkInformation_BCM 200;
BA_ "GenSigCycleTime" SG_ 1280 PartialNetworkInformation_BCM 200;
BA_ "GenSigTimeoutMsg_HU_High_X445" SG_ 1280 PartialNetworkInformation_BCM 1000;
BA_ "GenSigTimeoutMsg_HU_Mid_X445" SG_ 1280 PartialNetworkInformation_BCM 1000;
BA_ "GenSigTimeoutTime_HU_High_X445" SG_ 1280 PartialNetworkInformation_BCM 1000;
BA_ "GenSigTimeoutTime_HU_Mid_X445" SG_ 1280 PartialNetworkInformation_BCM 1000;
BA_ "GenSigTimeoutTime_HU_Mid_X451" SG_ 1280 Reserved3 1000;
BA_ "GenSigTimeoutTime_HU_High_X451" SG_ 1280 Reserved3 1000;
BA_ "GenSigTimeoutTime_HU_B" SG_ 1280 Reserved3 1000;
BA_ "GenSigTimeoutTime_HU_A" SG_ 1280 Reserved3 1000;
BA_ "GenSigTimeoutMsg_HU_Mid_X451" SG_ 1280 Reserved3 1000;
BA_ "GenSigTimeoutMsg_HU_High_X451" SG_ 1280 Reserved3 1000;
BA_ "GenSigTimeoutMsg_HU_B" SG_ 1280 Reserved3 1000;
BA_ "GenSigTimeoutMsg_HU_A" SG_ 1280 Reserved3 1000;
BA_ "GenSigSendType" SG_ 1280 Reserved3 7;
BA_ "GenSigCycleTimeActive" SG_ 1280 Reserved3 200;
BA_ "GenSigCycleTime" SG_ 1280 Reserved3 200;
BA_ "GenSigTimeoutMsg_HU_High_X445" SG_ 1280 Reserved3 1000;
BA_ "GenSigTimeoutMsg_HU_Mid_X445" SG_ 1280 Reserved3 1000;
BA_ "GenSigTimeoutTime_HU_High_X445" SG_ 1280 Reserved3 1000;
BA_ "GenSigTimeoutTime_HU_Mid_X445" SG_ 1280 Reserved3 1000;
BA_ "GenSigTimeoutTime_HU_Mid_X451" SG_ 1280 CurrentState_BCM 1000;
BA_ "GenSigTimeoutTime_HU_High_X451" SG_ 1280 CurrentState_BCM 1000;
BA_ "GenSigTimeoutTime_HU_B" SG_ 1280 CurrentState_BCM 1000;
BA_ "GenSigTimeoutTime_HU_A" SG_ 1280 CurrentState_BCM 1000;
BA_ "GenSigTimeoutMsg_HU_Mid_X451" SG_ 1280 CurrentState_BCM 1000;
BA_ "GenSigTimeoutMsg_HU_High_X451" SG_ 1280 CurrentState_BCM 1000;
BA_ "GenSigTimeoutMsg_HU_B" SG_ 1280 CurrentState_BCM 1000;
BA_ "GenSigTimeoutMsg_HU_A" SG_ 1280 CurrentState_BCM 1000;
BA_ "GenSigSendType" SG_ 1280 CurrentState_BCM 7;
BA_ "GenSigCycleTimeActive" SG_ 1280 CurrentState_BCM 200;
BA_ "GenSigCycleTime" SG_ 1280 CurrentState_BCM 200;
BA_ "GenSigTimeoutMsg_HU_High_X445" SG_ 1280 CurrentState_BCM 1000;
BA_ "GenSigTimeoutMsg_HU_Mid_X445" SG_ 1280 CurrentState_BCM 1000;
BA_ "GenSigTimeoutTime_HU_High_X445" SG_ 1280 CurrentState_BCM 1000;
BA_ "GenSigTimeoutTime_HU_Mid_X445" SG_ 1280 CurrentState_BCM 1000;
BA_ "GenSigTimeoutTime_HU_Mid_X451" SG_ 1280 PreviousState_BCM 1000;
BA_ "GenSigTimeoutTime_HU_High_X451" SG_ 1280 PreviousState_BCM 1000;
BA_ "GenSigTimeoutTime_HU_B" SG_ 1280 PreviousState_BCM 1000;
BA_ "GenSigTimeoutTime_HU_A" SG_ 1280 PreviousState_BCM 1000;
BA_ "GenSigTimeoutMsg_HU_Mid_X451" SG_ 1280 PreviousState_BCM 1000;
BA_ "GenSigTimeoutMsg_HU_High_X451" SG_ 1280 PreviousState_BCM 1000;
BA_ "GenSigTimeoutMsg_HU_B" SG_ 1280 PreviousState_BCM 1000;
BA_ "GenSigTimeoutMsg_HU_A" SG_ 1280 PreviousState_BCM 1000;
BA_ "GenSigSendType" SG_ 1280 PreviousState_BCM 7;
BA_ "GenSigCycleTimeActive" SG_ 1280 PreviousState_BCM 200;
BA_ "GenSigCycleTime" SG_ 1280 PreviousState_BCM 200;
BA_ "GenSigTimeoutMsg_HU_High_X445" SG_ 1280 PreviousState_BCM 1000;
BA_ "GenSigTimeoutMsg_HU_Mid_X445" SG_ 1280 PreviousState_BCM 1000;
BA_ "GenSigTimeoutTime_HU_High_X445" SG_ 1280 PreviousState_BCM 1000;
BA_ "GenSigTimeoutTime_HU_Mid_X445" SG_ 1280 PreviousState_BCM 1000;
BA_ "GenSigTimeoutTime_HU_Mid_X451" SG_ 1280 Reserved4 1000;
BA_ "GenSigTimeoutTime_HU_High_X451" SG_ 1280 Reserved4 1000;
BA_ "GenSigTimeoutTime_HU_B" SG_ 1280 Reserved4 1000;
BA_ "GenSigTimeoutTime_HU_A" SG_ 1280 Reserved4 1000;
BA_ "GenSigTimeoutMsg_HU_Mid_X451" SG_ 1280 Reserved4 1000;
BA_ "GenSigTimeoutMsg_HU_High_X451" SG_ 1280 Reserved4 1000;
BA_ "GenSigTimeoutMsg_HU_B" SG_ 1280 Reserved4 1000;
BA_ "GenSigTimeoutMsg_HU_A" SG_ 1280 Reserved4 1000;
BA_ "GenSigSendType" SG_ 1280 Reserved4 7;
BA_ "GenSigCycleTimeActive" SG_ 1280 Reserved4 200;
BA_ "GenSigCycleTime" SG_ 1280 Reserved4 200;
BA_ "GenSigTimeoutMsg_HU_High_X445" SG_ 1280 Reserved4 1000;
BA_ "GenSigTimeoutMsg_HU_Mid_X445" SG_ 1280 Reserved4 1000;
BA_ "GenSigTimeoutTime_HU_High_X445" SG_ 1280 Reserved4 1000;
BA_ "GenSigTimeoutTime_HU_Mid_X445" SG_ 1280 Reserved4 1000;
BA_ "GenSigTimeoutTime_HU_Mid_X451" SG_ 1280 Reserved5 1000;
BA_ "GenSigTimeoutTime_HU_High_X451" SG_ 1280 Reserved5 1000;
BA_ "GenSigTimeoutTime_HU_B" SG_ 1280 Reserved5 1000;
BA_ "GenSigTimeoutTime_HU_A" SG_ 1280 Reserved5 1000;
BA_ "GenSigTimeoutMsg_HU_Mid_X451" SG_ 1280 Reserved5 1000;
BA_ "GenSigTimeoutMsg_HU_High_X451" SG_ 1280 Reserved5 1000;
BA_ "GenSigTimeoutMsg_HU_B" SG_ 1280 Reserved5 1000;
BA_ "GenSigTimeoutMsg_HU_A" SG_ 1280 Reserved5 1000;
BA_ "GenSigSendType" SG_ 1280 Reserved5 7;
BA_ "GenSigCycleTimeActive" SG_ 1280 Reserved5 200;
BA_ "GenSigCycleTime" SG_ 1280 Reserved5 200;
BA_ "GenSigTimeoutMsg_HU_High_X445" SG_ 1280 Reserved5 1000;
BA_ "GenSigTimeoutMsg_HU_Mid_X445" SG_ 1280 Reserved5 1000;
BA_ "GenSigTimeoutTime_HU_High_X445" SG_ 1280 Reserved5 1000;
BA_ "GenSigTimeoutTime_HU_Mid_X445" SG_ 1280 Reserved5 1000;
BA_ "GenSigTimeoutTime_HU_Mid_X451" SG_ 1280 Reserved6 1000;
BA_ "GenSigTimeoutTime_HU_High_X451" SG_ 1280 Reserved6 1000;
BA_ "GenSigTimeoutTime_HU_B" SG_ 1280 Reserved6 1000;
BA_ "GenSigTimeoutTime_HU_A" SG_ 1280 Reserved6 1000;
BA_ "GenSigTimeoutMsg_HU_Mid_X451" SG_ 1280 Reserved6 1000;
BA_ "GenSigTimeoutMsg_HU_High_X451" SG_ 1280 Reserved6 1000;
BA_ "GenSigTimeoutMsg_HU_B" SG_ 1280 Reserved6 1000;
BA_ "GenSigTimeoutMsg_HU_A" SG_ 1280 Reserved6 1000;
BA_ "GenSigSendType" SG_ 1280 Reserved6 7;
BA_ "GenSigCycleTimeActive" SG_ 1280 Reserved6 200;
BA_ "GenSigCycleTime" SG_ 1280 Reserved6 200;
BA_ "GenSigTimeoutMsg_HU_High_X445" SG_ 1280 Reserved6 1000;
BA_ "GenSigTimeoutMsg_HU_Mid_X445" SG_ 1280 Reserved6 1000;
BA_ "GenSigTimeoutTime_HU_High_X445" SG_ 1280 Reserved6 1000;
BA_ "GenSigTimeoutTime_HU_Mid_X445" SG_ 1280 Reserved6 1000;
BA_ "GenSigTimeoutTime_HU_Mid_X451" SG_ 1280 Reserved7 1000;
BA_ "GenSigTimeoutTime_HU_High_X451" SG_ 1280 Reserved7 1000;
BA_ "GenSigTimeoutTime_HU_B" SG_ 1280 Reserved7 1000;
BA_ "GenSigTimeoutTime_HU_A" SG_ 1280 Reserved7 1000;
BA_ "GenSigTimeoutMsg_HU_Mid_X451" SG_ 1280 Reserved7 1000;
BA_ "GenSigTimeoutMsg_HU_High_X451" SG_ 1280 Reserved7 1000;
BA_ "GenSigTimeoutMsg_HU_B" SG_ 1280 Reserved7 1000;
BA_ "GenSigTimeoutMsg_HU_A" SG_ 1280 Reserved7 1000;
BA_ "GenSigSendType" SG_ 1280 Reserved7 7;
BA_ "GenSigCycleTimeActive" SG_ 1280 Reserved7 200;
BA_ "GenSigCycleTime" SG_ 1280 Reserved7 200;
BA_ "GenSigTimeoutMsg_HU_High_X445" SG_ 1280 Reserved7 1000;
BA_ "GenSigTimeoutMsg_HU_Mid_X445" SG_ 1280 Reserved7 1000;
BA_ "GenSigTimeoutTime_HU_High_X445" SG_ 1280 Reserved7 1000;
BA_ "GenSigTimeoutTime_HU_Mid_X445" SG_ 1280 Reserved7 1000;
BA_ "GenSigTimeoutTime_HU_Mid_X451" SG_ 1280 BCM_NMPDU_USER_DATA_D1 1000;
BA_ "GenSigTimeoutTime_HU_High_X451" SG_ 1280 BCM_NMPDU_USER_DATA_D1 1000;
BA_ "GenSigTimeoutTime_HU_B" SG_ 1280 BCM_NMPDU_USER_DATA_D1 1000;
BA_ "GenSigTimeoutTime_HU_A" SG_ 1280 BCM_NMPDU_USER_DATA_D1 1000;
BA_ "GenSigTimeoutMsg_HU_Mid_X451" SG_ 1280 BCM_NMPDU_USER_DATA_D1 1000;
BA_ "GenSigTimeoutMsg_HU_High_X451" SG_ 1280 BCM_NMPDU_USER_DATA_D1 1000;
BA_ "GenSigTimeoutMsg_HU_B" SG_ 1280 BCM_NMPDU_USER_DATA_D1 1000;
BA_ "GenSigTimeoutMsg_HU_A" SG_ 1280 BCM_NMPDU_USER_DATA_D1 1000;
BA_ "GenSigSendType" SG_ 1280 BCM_NMPDU_USER_DATA_D1 7;
BA_ "GenSigCycleTimeActive" SG_ 1280 BCM_NMPDU_USER_DATA_D1 200;
BA_ "GenSigCycleTime" SG_ 1280 BCM_NMPDU_USER_DATA_D1 200;
BA_ "GenSigTimeoutMsg_HU_High_X445" SG_ 1280 BCM_NMPDU_USER_DATA_D1 1000;
BA_ "GenSigTimeoutMsg_HU_Mid_X445" SG_ 1280 BCM_NMPDU_USER_DATA_D1 1000;
BA_ "GenSigTimeoutTime_HU_High_X445" SG_ 1280 BCM_NMPDU_USER_DATA_D1 1000;
BA_ "GenSigTimeoutTime_HU_Mid_X445" SG_ 1280 BCM_NMPDU_USER_DATA_D1 1000;
BA_ "GenSigTimeoutTime_HU_Mid_X451" SG_ 1280 BCM_NMPDU_USER_DATA_D2 1000;
BA_ "GenSigTimeoutTime_HU_High_X451" SG_ 1280 BCM_NMPDU_USER_DATA_D2 1000;
BA_ "GenSigTimeoutTime_HU_B" SG_ 1280 BCM_NMPDU_USER_DATA_D2 1000;
BA_ "GenSigTimeoutTime_HU_A" SG_ 1280 BCM_NMPDU_USER_DATA_D2 1000;
BA_ "GenSigTimeoutMsg_HU_Mid_X451" SG_ 1280 BCM_NMPDU_USER_DATA_D2 1000;
BA_ "GenSigTimeoutMsg_HU_High_X451" SG_ 1280 BCM_NMPDU_USER_DATA_D2 1000;
BA_ "GenSigTimeoutMsg_HU_B" SG_ 1280 BCM_NMPDU_USER_DATA_D2 1000;
BA_ "GenSigTimeoutMsg_HU_A" SG_ 1280 BCM_NMPDU_USER_DATA_D2 1000;
BA_ "GenSigSendType" SG_ 1280 BCM_NMPDU_USER_DATA_D2 7;
BA_ "GenSigCycleTimeActive" SG_ 1280 BCM_NMPDU_USER_DATA_D2 200;
BA_ "GenSigCycleTime" SG_ 1280 BCM_NMPDU_USER_DATA_D2 200;
BA_ "GenSigTimeoutMsg_HU_High_X445" SG_ 1280 BCM_NMPDU_USER_DATA_D2 1000;
BA_ "GenSigTimeoutMsg_HU_Mid_X445" SG_ 1280 BCM_NMPDU_USER_DATA_D2 1000;
BA_ "GenSigTimeoutTime_HU_High_X445" SG_ 1280 BCM_NMPDU_USER_DATA_D2 1000;
BA_ "GenSigTimeoutTime_HU_Mid_X445" SG_ 1280 BCM_NMPDU_USER_DATA_D2 1000;
BA_ "GenSigTimeoutTime_HU_Mid_X451" SG_ 1280 BCM_NMPDU_USER_DATA_D3 1000;
BA_ "GenSigTimeoutTime_HU_High_X451" SG_ 1280 BCM_NMPDU_USER_DATA_D3 1000;
BA_ "GenSigTimeoutTime_HU_B" SG_ 1280 BCM_NMPDU_USER_DATA_D3 1000;
BA_ "GenSigTimeoutTime_HU_A" SG_ 1280 BCM_NMPDU_USER_DATA_D3 1000;
BA_ "GenSigTimeoutMsg_HU_Mid_X451" SG_ 1280 BCM_NMPDU_USER_DATA_D3 1000;
BA_ "GenSigTimeoutMsg_HU_High_X451" SG_ 1280 BCM_NMPDU_USER_DATA_D3 1000;
BA_ "GenSigTimeoutMsg_HU_B" SG_ 1280 BCM_NMPDU_USER_DATA_D3 1000;
BA_ "GenSigTimeoutMsg_HU_A" SG_ 1280 BCM_NMPDU_USER_DATA_D3 1000;
BA_ "GenSigSendType" SG_ 1280 BCM_NMPDU_USER_DATA_D3 7;
BA_ "GenSigCycleTimeActive" SG_ 1280 BCM_NMPDU_USER_DATA_D3 200;
BA_ "GenSigCycleTime" SG_ 1280 BCM_NMPDU_USER_DATA_D3 200;
BA_ "GenSigTimeoutMsg_HU_High_X445" SG_ 1280 BCM_NMPDU_USER_DATA_D3 1000;
BA_ "GenSigTimeoutMsg_HU_Mid_X445" SG_ 1280 BCM_NMPDU_USER_DATA_D3 1000;
BA_ "GenSigTimeoutTime_HU_High_X445" SG_ 1280 BCM_NMPDU_USER_DATA_D3 1000;
BA_ "GenSigTimeoutTime_HU_Mid_X445" SG_ 1280 BCM_NMPDU_USER_DATA_D3 1000;
BA_ "GenSigTimeoutTime_HU_Mid_X451" SG_ 1280 BCM_NMPDU_USER_DATA_D4 1000;
BA_ "GenSigTimeoutTime_HU_High_X451" SG_ 1280 BCM_NMPDU_USER_DATA_D4 1000;
BA_ "GenSigTimeoutTime_HU_B" SG_ 1280 BCM_NMPDU_USER_DATA_D4 1000;
BA_ "GenSigTimeoutTime_HU_A" SG_ 1280 BCM_NMPDU_USER_DATA_D4 1000;
BA_ "GenSigTimeoutMsg_HU_Mid_X451" SG_ 1280 BCM_NMPDU_USER_DATA_D4 1000;
BA_ "GenSigTimeoutMsg_HU_High_X451" SG_ 1280 BCM_NMPDU_USER_DATA_D4 1000;
BA_ "GenSigTimeoutMsg_HU_B" SG_ 1280 BCM_NMPDU_USER_DATA_D4 1000;
BA_ "GenSigTimeoutMsg_HU_A" SG_ 1280 BCM_NMPDU_USER_DATA_D4 1000;
BA_ "GenSigSendType" SG_ 1280 BCM_NMPDU_USER_DATA_D4 7;
BA_ "GenSigCycleTimeActive" SG_ 1280 BCM_NMPDU_USER_DATA_D4 200;
BA_ "GenSigCycleTime" SG_ 1280 BCM_NMPDU_USER_DATA_D4 200;
BA_ "GenSigTimeoutMsg_HU_High_X445" SG_ 1280 BCM_NMPDU_USER_DATA_D4 1000;
BA_ "GenSigTimeoutMsg_HU_Mid_X445" SG_ 1280 BCM_NMPDU_USER_DATA_D4 1000;
BA_ "GenSigTimeoutTime_HU_High_X445" SG_ 1280 BCM_NMPDU_USER_DATA_D4 1000;
BA_ "GenSigTimeoutTime_HU_Mid_X445" SG_ 1280 BCM_NMPDU_USER_DATA_D4 1000;
BA_ "GenSigTimeoutTime_HU_Mid_X451" SG_ 1280 BCM_NMPDU_USER_DATA_D5 1000;
BA_ "GenSigTimeoutTime_HU_High_X451" SG_ 1280 BCM_NMPDU_USER_DATA_D5 1000;
BA_ "GenSigTimeoutTime_HU_B" SG_ 1280 BCM_NMPDU_USER_DATA_D5 1000;
BA_ "GenSigTimeoutTime_HU_A" SG_ 1280 BCM_NMPDU_USER_DATA_D5 1000;
BA_ "GenSigTimeoutMsg_HU_Mid_X451" SG_ 1280 BCM_NMPDU_USER_DATA_D5 1000;
BA_ "GenSigTimeoutMsg_HU_High_X451" SG_ 1280 BCM_NMPDU_USER_DATA_D5 1000;
BA_ "GenSigTimeoutMsg_HU_B" SG_ 1280 BCM_NMPDU_USER_DATA_D5 1000;
BA_ "GenSigTimeoutMsg_HU_A" SG_ 1280 BCM_NMPDU_USER_DATA_D5 1000;
BA_ "GenSigSendType" SG_ 1280 BCM_NMPDU_USER_DATA_D5 7;
BA_ "GenSigCycleTimeActive" SG_ 1280 BCM_NMPDU_USER_DATA_D5 200;
BA_ "GenSigCycleTime" SG_ 1280 BCM_NMPDU_USER_DATA_D5 200;
BA_ "GenSigTimeoutMsg_HU_High_X445" SG_ 1280 BCM_NMPDU_USER_DATA_D5 1000;
BA_ "GenSigTimeoutMsg_HU_Mid_X445" SG_ 1280 BCM_NMPDU_USER_DATA_D5 1000;
BA_ "GenSigTimeoutTime_HU_High_X445" SG_ 1280 BCM_NMPDU_USER_DATA_D5 1000;
BA_ "GenSigTimeoutTime_HU_Mid_X445" SG_ 1280 BCM_NMPDU_USER_DATA_D5 1000;
BA_ "GenSigTimeoutTime_HU_B" SG_ 1872 TesterPhysicalRequestESP 0;
BA_ "GenSigTimeoutTime_HU_A" SG_ 1872 TesterPhysicalRequestESP 0;
BA_ "GenSigTimeoutMsg_HU_B" SG_ 1872 TesterPhysicalRequestESP 0;
BA_ "GenSigTimeoutMsg_HU_A" SG_ 1872 TesterPhysicalRequestESP 0;
BA_ "GenSigSendType" SG_ 1872 TesterPhysicalRequestESP 1;
BA_ "GenSigTimeoutTime_HU_B" SG_ 1880 TesterPhysicalResponseESP 0;
BA_ "GenSigTimeoutTime_HU_A" SG_ 1880 TesterPhysicalResponseESP 0;
BA_ "GenSigTimeoutMsg_HU_B" SG_ 1880 TesterPhysicalResponseESP 0;
BA_ "GenSigTimeoutMsg_HU_A" SG_ 1880 TesterPhysicalResponseESP 0;
BA_ "GenSigSendType" SG_ 1880 TesterPhysicalResponseESP 1;
VAL_ 3221225472 NoGearshiftReqStatus 3 "Value is correct.ESP intervention active.Intervention requested" 2 "Value is implausible due to failure at TCS/ESP" 1 "Signal is not available" 0 "Value is correct.No TCS/ESP intervention.No interventon req" ;
VAL_ 3221225472 CruiseCntShutESPStatus 3 "Cruise Control shut down request not available" 2 "Value is implausible " 1 "Reserved for future use" 0 "Signal is correct" ;
VAL_ 3221225472 CruiseCntShutESP 1 "Cruise ctrl shut off is requested by ESP" 0 "Cruise ctrl shut off is not requested by ESP" ;
VAL_ 3221225472 PowerModeStateStatus 3 "Signal not avialable" 2 "Reserved" 1 "Reserved" 0 "Value is plausible" ;
VAL_ 401 CPP_SystemStatus 3 "Failure" 2 "System Available" 1 "System Disabled" 0 "Not used" ;
VAL_ 401 CPP_BrakeRequest 3 "NA" 2 "Hold" 1 "Open Loop Brake to Stop" 0 "No Braking" ;
VAL_ 400 ACC_SystemStatus 3 "Failure" 2 "System Available" 1 "System Disabled" 0 "Not used" ;
VAL_ 400 ACC_BrakeRequest 3 "Hold" 2 "Open Loop Brake to Stop" 1 "Brake Per Decel. request" 0 "No Braking" ;
VAL_ 402 BrakeSys_CPP_Status 2 "Failure" 1 "Active" 0 "Not active" ;
VAL_ 402 BrakeSys_ACC_Status 2 "Failure" 1 "Active" 0 "Not active" ;
VAL_ 402 BrakeSys_ACC_BrakeOverheat 1 "brakes overheated" 0 "normal" ;
VAL_ 402 BrakeSys_AEB_Status 3 "Failure" 2 "Limited" 1 "Active" 0 "Not active" ;
VAL_ 393 AEB_SystemStatus 3 "Failure" 2 "System Available" 1 "System Disabled" 0 "Not used" ;
VAL_ 393 AEB_PreFillRequest 1 "Prefill for AEB requested" 0 "No Prefill request" ;
VAL_ 393 AEB_ForwardLookingBrakeAssist 2 "brake assist entrance increase" 1 "brake assist entrance reduction" 0 "base panic brake assist" ;
VAL_ 393 AEB_AutomaticBrakeType 5 "Hold" 4 "Integrated Brake Assist" 3 "Collision Mitigation Braking" 2 "Forward Emergency Automatic Brak" 1 "Light autonomous braking" 0 "Idle" ;
VAL_ 393 AEB_AutomaticBrakeRequest 1 "AEB automatic brake requested" 0 "AEB idle" ;
VAL_ 193 LongitAccStatus 1 "Data Invalid" 0 "Data Valid" ;
VAL_ 193 LatAccStatus 1 "Data Invalid" 0 "Data Valid" ;
VAL_ 193 YawRateStatus 1 "Data Invalid" 0 "Data Valid" ;
VAL_ 275 DriverReqTrqStatus 3 "Reserved" 2 "Information given by DriverReqTrq is implausible" 1 "Reserved" 0 "Information given by DriverReqTrq is correct and according to specification" ;
VAL_ 275 RecupBrakeState 1 "Recupration Enable" 0 "Recupration Disable" ;
VAL_ 275 MaxAvailableRegenTrqStatus 3 "Reserved for future use" 2 "Information given by MaxAvailableRegenTrq is implausible" 1 "Reserved for future use" 0 "Information given by MaxAvailableRegenTrq is correct and according to specification" ;
VAL_ 378 WheelTrqLimFastStatus 3 "Signal MotorTrqLimFast not available" 2 "information given at MotorTrqLimFast is implausible due to a detected failure at brake system" 1 "information given at MotorTrqLimFast is correct and and TCS/ESP intervention is active. Torque intervention requested." 0 "infomation given at MotorTrqLimFast is correct but TCS/ESP intervention not active. No torque intervention requested." ;
VAL_ 378 WheelTrqIncStatus 3 "Signal MotorTrqInc not available" 2 "Information given at MotorTrqInc is implausible due to a detected failure at brake system." 1 "Information given at MotorTrqInc is correct and according to specification and Torque intervention requested." 0 "Information given at MotorTrqInc is correct and according to specification, No torque intervention requested." ;
VAL_ 567 IDBMode 3 "Reserved" 2 "Dyno Mode" 1 "Rollerbench" 0 "Normal" ;
VAL_ 567 MCMsAvailability 1 "MultiCollisionMitigationSystem function not available" 0 "MultiCollisionMitigationSystem function available" ;
VAL_ 567 MCMsErrorState 1 "MultiCollisionMitigationSystem switched off due to a detected failure at ESP system" 0 "MultiCollisionMitigationSystem fully available @ MFL is OFF" ;
VAL_ 567 MCMsActive 1 "MultiCollisionMitigationSystem intervention by ESP system is active @ tale tell/Text info ON" 0 "No MultiCollisionMitigationSystem intervention by ESP system @ tale tell/Text info OFF" ;
VAL_ 567 AVhStatus 1 "AVH  function switched off due to detected failure at ESP" 0 "AVH function fully available" ;
VAL_ 567 AVhState 3 "Reserved" 2 "AVH Standby" 1 "AVH Active" 0 "AVH OFF" ;
VAL_ 567 AVhAvailability 1 "AVH  Not available" 0 "AVH Available" ;
VAL_ 567 EpbState 8 "Reserved" 7 "Reserved" 6 "Maintenance Mode active" 5 "Dynamic EPB apply" 4 "Locking" 3 "Releasing" 2 "Applied" 1 "Released" 0 "Unknown" ;
VAL_ 567 EpbErrorState 3 "Diagnosis" 2 "Error" 1 "No Error" 0 "Reserved" ;
VAL_ 567 EpbAvailability 1 "EPB Not available" 0 "EPB Available" ;
VAL_ 280 TarRecupTrqStatus 3 "Signal TarRegenTrq not available" 2 "Information given is implausible" 1 "Reserved for future use" 0 "Information given  is correct" ;
VAL_ 280 InhibitCostRecuprationStatus 3 "Reserved for future use" 2 "Information given is implausible" 1 "Reserved for future use" 0 "Information given  is correct" ;
VAL_ 280 InhibitCostRecupration 1 "CoastEnabled" 0 "CoastInhibit" ;
VAL_ 280 InhibitRecuprationAbsStatus 3 "Reserved for future use" 2 "Information given is implausible" 1 "Reserved for future use" 0 "Information given is correct" ;
VAL_ 280 InhibitRecuprationAbs 1 "RecupEnabled" 0 "RecupInhibit" ;
VAL_ 1289 PreviousState_ESP 7 "Reserved" 6 "Reserved" 5 "Reserved" 4 "Bus Sleep State" 3 "Prepare Bus Sleep State" 2 "Ready Sleep State" 1 "Normal Operation State" 0 "Repeat Message State" ;
VAL_ 1289 RepeatMessageReq_ESP 1 "Reserved" 0 "Repeat message state not requested" ;
VAL_ 1289 CurrentState_ESP 1 "Normal Operation State" 0 "Repeat Messgae State" ;
VAL_ 1289 ActiveWakeUp_ESP 1 "Node has  woken up the network(Active wakeup)" 0 "Node has not woken up the network(Passive wakeup)" ;
VAL_ 1163 VCUMToFailureStatus 3 "Reserved" 2 "Failure healed aging in progress" 1 "Failure matured & DTC in memory" 0 "Failure is not detected" ;
VAL_ 1163 VCUInvalidFailureStatus 3 "Reserved" 2 "Failure healed aging in progress" 1 "Failure matured & DTC in memory" 0 "Failure is not detected" ;
VAL_ 580 VehicleStatus 7 "Reserved" 6 "Reserved" 5 "Reserved" 4 "Reserved" 3 "EV System Disengaged" 2 "Not Ready to Go,  HV System Not Ready" 1 "Not Ready to Go, Charger Connected" 0 "Ready to Go" ;
VAL_ 580 VcuPowerMode 15 "Reserved" 14 "Reserved" 13 "Reserved" 12 "Reserved" 11 "Reserved" 10 "Reserved" 9 "Reserved" 8 "Reserved" 7 "Reserved" 6 "Invalid_5" 5 "Invalid_4" 4 "Invalid_3" 3 "Normal_Run" 2 "Invalid_2" 1 "Invalid_1" 0 "Awake" ;
VAL_ 580 VcuPowerModeStatus 3 "Reserved" 2 "Information given is implausible due to a detected failure" 1 "Reserved" 0 "Information given is correct and according to specification" ;
VAL_ 579 GearForDisplayVcu 15 "Reserved" 14 "Reserved" 13 "Reserved" 12 "Reserved" 11 "Reserved" 10 "Reserved" 9 "Reserved" 8 "Reserved" 7 "Reserved" 6 "Reserved" 5 "Drive_2ndGear" 4 "Drive_1stGear" 3 "Neutral" 2 "Reverse" 1 "Park" 0 "Not Used" ;
VAL_ 579 GearForDisplayVcuStatus 3 "Reserved" 2 "Information given is implausible due to a detected failure" 1 "Reserved" 0 "Information given correct and according to specification" ;
VAL_ 273 CurrentTorqueAtMotorStatus 3 "Reserved" 2 "Information given is implausible" 1 "Reserved" 0 "Information given is correct" ;
VAL_ 273 RecuprationActualTorqueStatus 3 "Reserved" 2 "Information in signal RecuprationActualTorqueStatus is implausible" 1 "Reserved" 0 "Information in signal RecuprationActualTorqueStatus is correct" ;
VAL_ 273 CurrentTorqueToWheelStatus 3 "Reserved for future use" 2 "Information given  is implausible" 1 "Reserved for future use" 0 "Information given is correct " ;
VAL_ 273 AccPedPosnVcuStatus 3 "Reserved" 2 "Information in signal AccPedPosnVcuStatus is implausible" 1 "Reserved" 0 "Information in signal AccPedPosnVcuStatus is correct" ;
VAL_ 192 OK 1 "Sensor Informatio is valid" 0 "Sensor Information is invalid, Internal sensor failure occurred" ;
VAL_ 192 CAL 1 "SAS Sensor is calibrated" 0 "SAS Sensor not calibrated" ;
VAL_ 370 BrakeFluidSwitchWarn 3 "not_used2" 2 "BFLS_Warning_Active" 1 "not_used1" 0 "no_BFLS_Warning" ;
VAL_ 370 ABsActive 1 "ABS intervention by ABS/ESP is active" 0 "No ABS internention by ABS/ESP" ;
VAL_ 370 TCsStatus 3 " TCS switched off due to a detected failure at TCS system" 2 "Vehicle not equipped with TCS function" 1 "TCS switched off due to a system passive request" 0 "TCS fully available @ MFL is OFF" ;
VAL_ 370 TCsActive 1 "TCs intervention by ESP system @MFL is ON" 0 "No TCs intervention by ESP system @MFL is OFF" ;
VAL_ 370 ESpStatus 3 "ESP switched off due to a detected failure at ESP system" 2 "Vehicle not equipped with ESP function" 1 "ESP switched off due to a system passive request" 0 "ESP fully available @ MFL is OFF" ;
VAL_ 370 ESpActive 1 "ESP intervention by ESP system is active @ MFL is BLINKING @ 2 Hz (conf value)" 0 "No ESP intervention by ESP system @ MFL is OFF" ;
VAL_ 370 NoGearshiftReq 1 "ESP inhibits automatic gear shift" 0 "Gear shift not inflluenced by ESP" ;
VAL_ 370 EBdStatus 3 "Reserved for future" 2 "EBD function is switched off due to failure @EBD Warn Lamp is ON" 1 "Reserved for future" 0 "EBD function fully available@EBD Warning Lamp is OFF" ;
VAL_ 370 EBdActive 1 "EBD intervention  by ABS/ESP is active" 0 "No EBD intervention by ABS/ESP" ;
VAL_ 370 ABsStatus 3 "Reserved for future" 2 "ABS function switched off due to failure at ABS/ESP@ABS Warn Lamp ON" 1 "Reserved for future" 0 "ABS function fully available@ABS Warning Lamp is OFF" ;
VAL_ 370 HsaStatus 3 "Reserved for future" 2 "HSA function switched off due to a detected failure at  ESP system" 1 "Reserved for future" 0 "HSA function is fully available" ;
VAL_ 370 HsaActive 1 "HSA Intervention by ESP system is active" 0 "No HSA intervention by ESP system" ;
VAL_ 374 BrakeLightRequest 3 "Take no action" 2 "EmcyFlashing" 1 "On" 0 "Off" ;
VAL_ 374 BrakePedalPosition 255 "Error" ;
VAL_ 374 BrakePedalPressed 3 "Faulty" 2 "PedalPressed" 1 "NotPressed" 0 "NotUsed" ;
VAL_ 374 VehicleDrivingState 3 "Faulty" 2 "VehicleIsMoving" 1 "VehicleIsStationary" 0 "NotUsed" ;
VAL_ 374 VehSpdABsStatus 3 "Reserved for future" 2 "Value is implausible" 1 "Reserved for future" 0 "Value is correct" ;
VAL_ 376 MasterCylinderPresStatus 3 "Reserved for future use" 2 "MasterCylinderPres is implausible" 1 "Reserved for future use" 0 "MasterCylinderPres is correct " ;
VAL_ 656 WSsPulseCountFrontRHStatus 3 "Reserved" 2 "value is implausible" 1 "Reserved" 0 "Value is plausible" ;
VAL_ 656 WSsPulseCountRearLHStatus 3 "Reserved" 2 "value is implausible" 1 "Reserved" 0 "Value is plausible" ;
VAL_ 656 WSsPulseCountRearRHStatus 3 "Reserved" 2 "value is implausible" 1 "Reserved" 0 "Value is plausible" ;
VAL_ 656 WSsPulseCountFrontLHStatus 3 "Reserved" 2 "value is implausible" 1 "Reserved" 0 "Value is plausible" ;
VAL_ 656 DrvModeIndctnESPStatusNew 3 "Signal is not available" 2 "Signal is implausible" 1 "Reserved" 0 "Information given is correct and according to specification" ;
VAL_ 656 DrvModeIndctnESPNew 7 "Rough Road" 6 "Wet/Rain" 5 "Reserved" 4 "Sand" 3 "Mud / Ruts / Gravel " 2 "Grass / Snow" 1 "Sports" 0 "Normal" ;
VAL_ 660 WhlSpdFrLeftStatus 3 "Reserved for future" 2 "Information given at WhlSpdFrLeft is implausible due to a detected failure at wheel speed sensor FL" 1 "Reserved for future" 0 "Information given at WhlSpdFrLeft is correct and according to specification" ;
VAL_ 660 WhlSpdFrRightStatus 3 "Reserved for future" 2 "Information given at WhlSpdFrRight is implausible due to a detected failure at wheel speed sensor FR" 1 "Reserved for future" 0 "Information given at WhlSpdFrRight is correct and according to specification" ;
VAL_ 660 WhlSpdRrLeftStatus 3 "Reserved for future" 2 "Information given at WhlSpdRrLeft is implausible due to a detected failure at wheel speed sensor RL" 1 "Reserved for futute" 0 "Information given at WhlSpdRrLeft is correct and according to specification" ;
VAL_ 660 WhlSpdRrRightStatus 3 "Reserved for future" 2 "Information given at WhlSpdRrRight is implausible due to a detected failure at wheel speed sensor RR" 1 "Reserved for future" 0 "Information given at WhlSpdRrRight is correct and according to specification" ;
VAL_ 693 AVhEnableRequest 1 "AVhFuncEnable" 0 "AVhFuncDisable" ;
VAL_ 693 EpbSwitchRequest 3 "Faulty" 2 "EpbSwitchApply" 1 "EpbSwitchRelease" 0 "EpbSwitchIdle" ;
VAL_ 693 OATICSigStatus 3 "Signal not available" 2 "Value is impluasible" 1 "Reserved" 0 "Value is plausible" ;
VAL_ 722 PowerModeState 15 "Reserved" 14 "Reserved" 13 "Reserved" 12 "Reserved" 11 "Invalid_8" 10 "Invalid_7" 9 "Invalid_6" 8 "Invalid_5" 7 "Invalid_4" 6 "Invalid_3" 5 "Invalid_2" 4 "Invalid_1" 3 "Maintenance" 2 "Run" 1 "Accessory" 0 "Off" ;
VAL_ 946 DriverPresenceState 3 "Reserved" 2 "Faulty State" 1 "Driver Unpresent" 0 "Driver Present" ;
VAL_ 946 WiperHighLowIntermtStateStatus 3 "Signal WiperState not available" 2 "Reserved for future use" 1 "Reserved for future use" 0 "Plausible-Information given by WiperState is correct and according to specification" ;
VAL_ 946 WiperHighLowIntermtState 7 "Reserved Bit" 6 "Reserved Bit" 5 "Reserved Bit" 4 "Reserved Bit" 3 "Wiper INTERMITTENT Mode Enable" 2 "Wiper LOW Speed Mode Enable" 1 "Wiper HIGH Speed Mode Enable" 0 "Wiper OFF" ;
VAL_ 1274 GlobalRealTimeGS 16777215 "Signal not available" ;
VAL_ 1274 OdoICFullSigGS 16777215 "Signal not available" ;
VAL_ 1274 BatVoltGS 255 "Signal nlot available" ;
VAL_ 1274 VehicleInteriorTempGS 255 "Signal not available" ;
VAL_ 1280 RepeatMessageReq_BCM 1 "Repeat message state requested" 0 "Repeat message state not requested" ;
VAL_ 1280 ActiveWakeUp_BCM 1 "Node has  woken up the network(Active wakeup)" 0 "Node has not woken up the network(Passive wakeup)" ;
VAL_ 1280 CurrentState_BCM 1 "Normal Operation State" 0 "Repeat Messgae State" ;
VAL_ 1280 PreviousState_BCM 7 "Reserved" 6 "Reserved" 5 "Reserved" 4 " Bus Sleep State" 3 "Prepare Bus Sleep State" 2 "Ready Sleep State" 1 "Normal Operation State" 0 "Repeat Message State" ;
